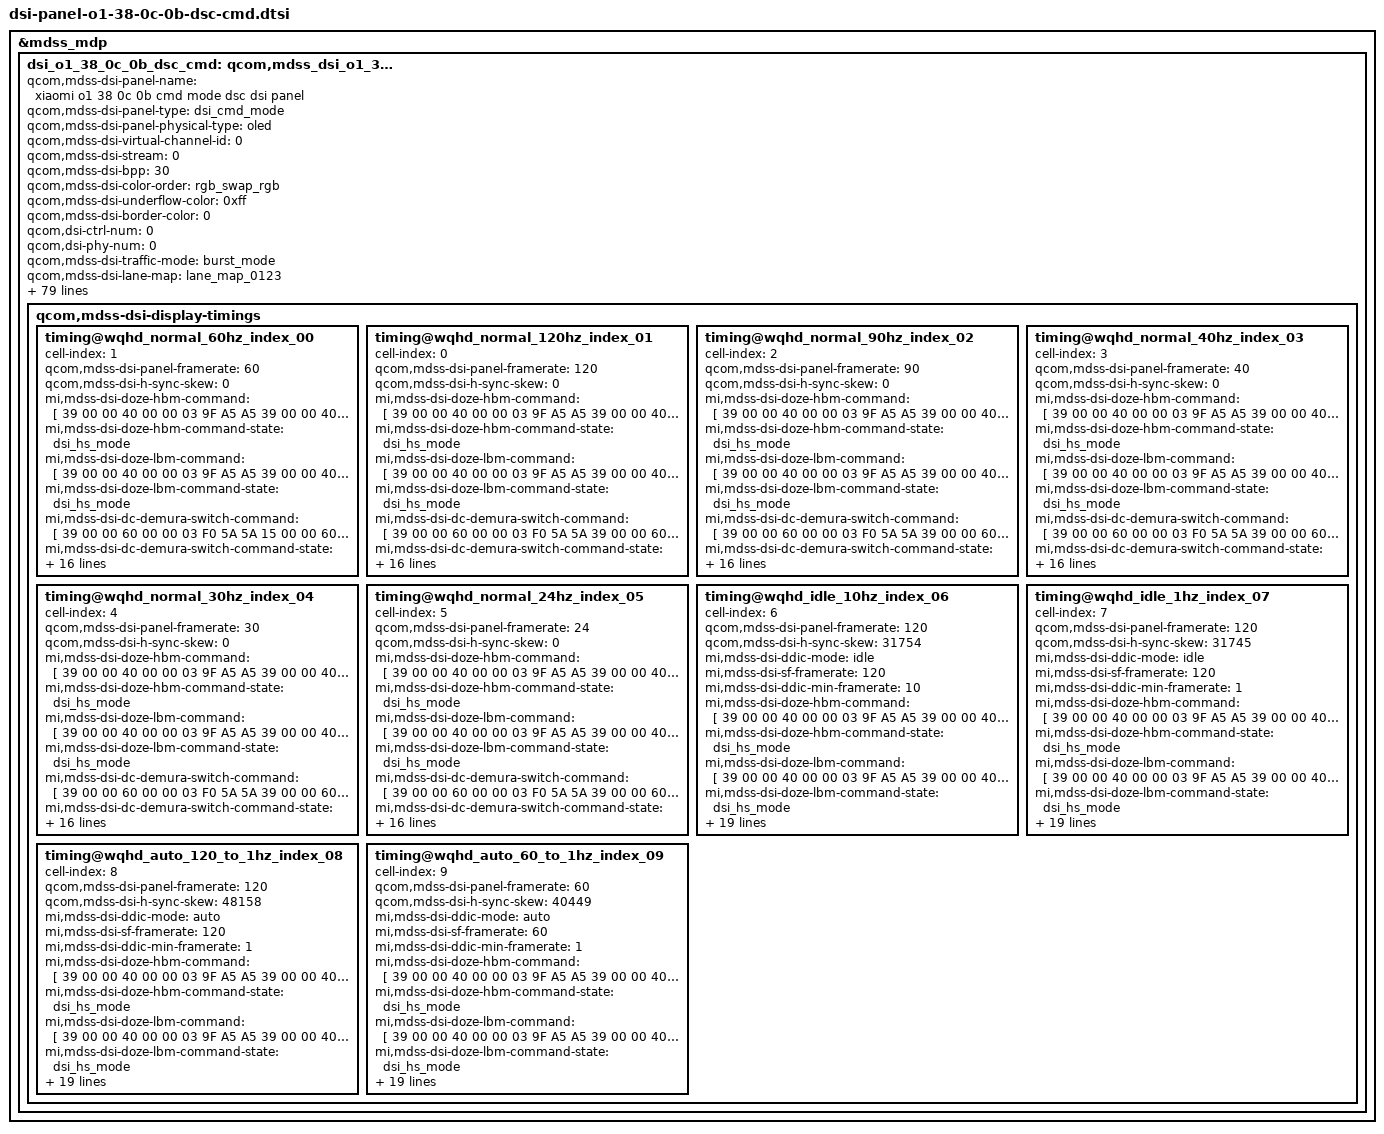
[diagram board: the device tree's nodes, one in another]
&mdss_mdp {
	dsi_o1_38_0c_0b_dsc_cmd: qcom,mdss_dsi_o1_38_0c_0b_dsc_cmd {
		qcom,mdss-dsi-panel-name = "xiaomi o1 38 0c 0b cmd mode dsc dsi panel";
		qcom,mdss-dsi-panel-type = "dsi_cmd_mode";
		qcom,mdss-dsi-panel-physical-type = "oled";
		qcom,mdss-dsi-virtual-channel-id = <0>;
		qcom,mdss-dsi-stream = <0>;
		qcom,mdss-dsi-bpp = <30>;
		qcom,mdss-dsi-color-order = "rgb_swap_rgb";
		qcom,mdss-dsi-underflow-color = <0xff>;
		qcom,mdss-dsi-border-color = <0>;
		qcom,dsi-ctrl-num = <0>;
		qcom,dsi-phy-num = <0>;
		qcom,mdss-dsi-traffic-mode = "burst_mode";
		qcom,mdss-dsi-lane-map = "lane_map_0123";
		qcom,mdss-dsi-bllp-eof-power-mode;
		qcom,mdss-dsi-bllp-power-mode;
		qcom,mdss-dsi-lane-0-state;
		qcom,mdss-dsi-lane-1-state;
		qcom,mdss-dsi-lane-2-state;
		qcom,mdss-dsi-lane-3-state;
		qcom,mdss-dsi-dma-trigger = "trigger_sw";
		qcom,mdss-dsi-mdp-trigger = "none";
		qcom,mdss-dsi-reset-sequence =<1 1>, <0 1>, <1 10>;
		qcom,mdss-pan-physical-width-dimension = <701>;
		qcom,mdss-pan-physical-height-dimension = <1558>;
		qcom,mdss-dsi-te-pin-select = <1>;
		qcom,mdss-dsi-wr-mem-start = <0x2c>;
		qcom,mdss-dsi-wr-mem-continue = <0x3c>;
		qcom,mdss-dsi-te-dcs-command = <1>;
		qcom,mdss-dsi-te-check-enable;
		qcom,mdss-dsi-te-using-te-pin;
		qcom,mdss-dsi-tx-eot-append;
		qcom,mdss-dsi-lp11-init;
		qcom,mdss-dsi-bl-inverted-dbv;
		qcom,mdss-dsi-panel-dimming-enabled;
		qcom,bl-update-flag = "delay_until_first_frame";
		qcom,mdss-dsi-panel-hdr-enabled;
		qcom,mdss-dsi-panel-hdr-color-primaries = <14500 15500 32000
			17000 15500 30000 8000 3000>;
		qcom,mdss-dsi-panel-peak-brightness = <32000000>;
		qcom,mdss-dsi-panel-blackness-level = <3230>;
		qcom,mdss-dsi-dma-schedule-line = <1>;
		qcom,mdss-dsi-dma-schedule-window = <50>;
		mi,panel-id = <0x00004F31 0x00380C0B>;
		mi,panel-on-dimming-delay = <120>;

		/* IRQF_ONESHOT | IRQF_TRIGGER_HEIGH */
		mi,esd-err-irq-gpio = <&tlmm 87 0x2004>;
		mi,esd-err-irq-gpio-flag = <0x2004>;

		qcom,qsync-enable;

		mi,mdss-dsi-panel-wp-read-command = [06 01 00 01 00 00 01 A1];
		mi,mdss-dsi-panel-wp-read-command-state = "dsi_hs_mode";
		mi,mdss-dsi-panel-wp-read-length = <8>;

		mi,mdss-dsi-fac-bl-max-level = <5460>;
		mi,mdss-fac-brightness-max-level = <5460>;
		mi,flatmode-status-check-enabled;
		mi,mdss-dsi-panel-flatmode-status-command = [
				06 01 00 01 00 00 01 5F
		];
		mi,mdss-dsi-panel-flatmode-status-command-state = "dsi_hs_mode";
		mi,mdss-dsi-panel-flatmode-status-read-length = <1>;
		mi,mdss-dsi-panel-flatmode-on-status-value = <0x00>;

		mi,doze-hbm-dbv-level = <412>;
		mi,doze-lbm-dbv-level = <35>;
		qcom,mdss-disable-cesta-hw-sleep;
		mi,sf-set-doze-brightness;

		qcom,mdss-dsi-display-timings {
			timing@wqhd_normal_60hz_index_00 {
				#include "dsi-panel-o1-38-0c-0b-dsc-cmd-common.dtsi"
				cell-index = <1>;
				qcom,mdss-dsi-panel-framerate = <60>;
				qcom,mdss-dsi-h-sync-skew = <0>;
				mi,mdss-dsi-doze-hbm-command = [
					//120HZ
					39 00 00 40 00 00 03 9F A5 A5
					39 00 00 40 00 00 03 F0 5A 5A
					39 00 00 40 00 00 04 B0 00 03 BD
					39 00 00 40 00 00 02 BD 66
					39 00 00 40 00 00 04 B0 00 08 BD
					39 00 00 40 00 00 02 BD 00
					39 00 00 40 00 00 02 B9 19
					39 00 00 40 00 00 04 B0 00 08 B9
					39 00 00 40 00 00 07 B9 02 00 02 02 00 02
					39 00 00 40 00 00 04 B0 00 06 B9
					39 00 00 40 00 00 02 B9 00
					39 00 00 40 00 00 04 B0 00 91 B9
					39 00 00 40 00 00 02 B9 00
					39 00 00 40 00 00 02 BD 01
					39 00 00 40 00 00 02 83 00
					39 00 00 40 00 00 02 F7 2F
					39 00 00 40 00 00 03 F0 A5 A5
					39 00 00 00 11 00 03 9F 5A 5A
					//1HZ AOD
					39 00 00 40 00 00 03 9F A5 A5
					39 00 00 40 00 00 03 F0 5A 5A
					39 00 00 40 00 00 04 B0 00 03 BD
					39 00 00 40 00 00 02 BD 64
					39 00 00 40 00 00 02 53 24
					39 00 00 40 00 00 02 83 1B
					39 00 00 40 00 00 03 51 01 9C
					39 00 00 40 00 00 02 B9 C1
					39 00 00 40 00 00 04 B0 00 08 B9
					39 00 00 40 00 00 07 B9 32 00 02 32 00 02
					39 00 00 40 00 00 04 B0 00 06 B9
					39 00 00 40 00 00 02 B9 03
					39 00 00 40 00 00 02 F7 2F
					39 00 00 40 00 00 03 F0 A5 A5
					39 00 00 00 00 00 03 9F 5A 5A
				];
				mi,mdss-dsi-doze-hbm-command-state = "dsi_hs_mode";

				mi,mdss-dsi-doze-lbm-command = [
					//120HZ
					39 00 00 40 00 00 03 9F A5 A5
					39 00 00 40 00 00 03 F0 5A 5A
					39 00 00 40 00 00 04 B0 00 03 BD
					39 00 00 40 00 00 02 BD 66
					39 00 00 40 00 00 04 B0 00 08 BD
					39 00 00 40 00 00 02 BD 00
					39 00 00 40 00 00 02 B9 19
					39 00 00 40 00 00 04 B0 00 08 B9
					39 00 00 40 00 00 07 B9 02 00 02 02 00 02
					39 00 00 40 00 00 04 B0 00 06 B9
					39 00 00 40 00 00 02 B9 00
					39 00 00 40 00 00 04 B0 00 91 B9
					39 00 00 40 00 00 02 B9 00
					39 00 00 40 00 00 02 BD 01
					39 00 00 40 00 00 02 83 00
					39 00 00 40 00 00 02 F7 2F
					39 00 00 40 00 00 03 F0 A5 A5
					39 00 00 00 11 00 03 9F 5A 5A
					//1HZ AOD
					39 00 00 40 00 00 03 9F A5 A5
					39 00 00 40 00 00 03 F0 5A 5A
					39 00 00 40 00 00 04 B0 00 03 BD
					39 00 00 40 00 00 02 BD 64
					39 00 00 40 00 00 02 53 24
					39 00 00 40 00 00 02 83 1B
					39 00 00 40 00 00 03 51 00 23
					39 00 00 40 00 00 02 B9 C1
					39 00 00 40 00 00 04 B0 00 08 B9
					39 00 00 40 00 00 07 B9 32 00 02 32 00 02
					39 00 00 40 00 00 04 B0 00 06 B9
					39 00 00 40 00 00 02 B9 03
					39 00 00 40 00 00 02 F7 2F
					39 00 00 40 00 00 03 F0 A5 A5
					39 00 00 00 00 00 03 9F 5A 5A
				];
				mi,mdss-dsi-doze-lbm-command-state = "dsi_hs_mode";

				mi,mdss-dsi-dc-demura-switch-command = [
					39 00 00 60 00 00 03 F0 5A 5A
					15 00 00 60 00 00 02 53 20
					39 00 00 60 00 00 04 B0 00 79 62
					15 00 00 60 00 00 02 62 01
					15 00 00 20 03 00 02 F7 2F
					39 00 00 60 00 00 04 B0 01 56 6B
					39 00 00 60 00 00 C2 6B 01 FF FF FF FF FF FF FF
								FF FF FF FF FF FF A8 FF A8 FF 96 FF
								84 FF 73 FF 50 FF 3E FF 1B FF 09 FE
								E6 FE E6 FE E6 FE E6 FE E6 FE E6 FE
								E6 FE E6 FE E6 FE E6 FE E6 FE E6 FE
								E6 FE E6 FE E6 FE E6 FE B1 FF FF FF
								FF FF FF FF FF FF FF FF FF FF A8 FF
								A8 FF 96 FF 84 FF 73 FF 50 FF 3E FF
								1B FF 09 FE E6 FE E6 FE E6 FE E6 FE
								E6 FE E6 FE E6 FE E6 FE E6 FE E6 FE
								E6 FE E6 FE E6 FE E6 FE E6 FE E6 FE
								B1 FF FF FF FF FF FF FF FF FF FF FF
								FF FF A8 FF A8 FF 96 FF 84 FF 73 FF
								50 FF 3E FF 1B FF 09 FE E6 FE E6 FE
								E6 FE E6 FE E6 FE E6 FE E6 FE E6 FE
								E6 FE E6 FE E6 FE E6 FE E6 FE E6 FE
								E6 FE E6 FE B1
					39 00 00 60 00 00 03 51 01 9C
					15 00 00 20 03 00 02 F7 2F
					39 00 00 60 00 00 04 B0 01 56 6B
					15 00 00 60 00 00 02 6B 00
					39 00 00 60 00 00 04 B0 00 79 62
					15 00 00 60 00 00 02 62 00
					15 00 00 60 00 00 02 F7 2F
					39 00 00 20 00 00 03 F0 A5 A5
				];
				mi,mdss-dsi-dc-demura-switch-command-state = "dsi_hs_mode";

				mi,mdss-dsi-pwm-demura-switch-command = [
					39 00 00 60 00 00 03 F0 5A 5A
					15 00 00 60 00 00 02 53 20
					39 00 00 60 00 00 04 B0 00 79 62
					15 00 00 60 00 00 02 62 01
					15 00 00 20 03 00 02 F7 2F
					39 00 00 60 00 00 04 B0 01 56 6B
					39 00 00 60 00 00 C2 6B 01 00 00 00 00 00 00 00
								00 00 00 00 00 00 00 00 00 00 00 00
								00 00 00 00 00 00 00 00 00 00 00 00
								00 00 00 00 00 00 8C 00 8C 00 8C 00
								8C 00 8C 00 8C 00 8C 00 8C 00 8C 00
								8C 00 8C 00 8C 00 8C 00 B0 00 00 00
								00 00 00 00 00 00 00 00 00 00 00 00
								00 00 00 00 00 00 00 00 00 00 00 00
								00 00 00 00 00 00 00 00 00 00 8C 00
								8C 00 8C 00 8C 00 8C 00 8C 00 8C 00
								8C 00 8C 00 8C 00 8C 00 8C 00 8C 00
								B0 00 00 00 00 00 00 00 00 00 00 00
								00 00 00 00 00 00 00 00 00 00 00 00
								00 00 00 00 00 00 00 00 00 00 00 00
								00 00 8C 00 8C 00 8C 00 8C 00 8C 00
								8C 00 8C 00 8C 00 8C 00 8C 00 8C 00
								8C 00 8C 00 B0
					39 00 00 60 00 00 03 51 01 9B
					15 00 00 20 03 00 02 F7 2F
					39 00 00 60 00 00 04 B0 01 56 6B
					15 00 00 60 00 00 02 6B 00
					39 00 00 60 00 00 04 B0 00 79 62
					15 00 00 60 00 00 02 62 00
					15 00 00 60 00 00 02 F7 2F
					39 00 00 20 00 00 03 F0 A5 A5
				];
				mi,mdss-dsi-pwm-demura-switch-command-state = "dsi_hs_mode";

				qcom,mdss-dsi-nolp-command = [
					39 00 00 40 00 00 03 9F A5 A5
					39 00 00 40 00 00 03 F0 5A 5A
					39 00 00 40 00 00 04 B0 00 03 BD
					39 00 00 40 00 00 02 BD 66
					39 00 00 40 00 00 02 B9 19
					39 00 00 40 00 00 04 B0 00 08 B9
					39 00 00 40 00 00 07 B9 02 00 02 02 00 02
					39 00 00 40 00 00 04 B0 00 06 B9
					39 00 00 40 00 00 02 B9 00
					39 00 00 40 00 00 02 53 20
					39 00 00 40 00 00 02 83 00
					39 00 00 40 00 00 03 51 00 23
					39 00 00 40 00 00 02 F7 2F
					39 00 00 40 00 00 03 F0 A5 A5
					39 00 00 00 00 00 03 9F 5A 5A
					//60HZ
					39 00 00 40 00 00 03 9F A5 A5
					39 00 00 40 00 00 03 F0 5A 5A
					39 00 00 40 00 00 04 B0 00 03 BD
					39 00 00 40 00 00 02 BD 66
					39 00 00 40 00 00 04 B0 00 08 BD
					39 00 00 40 00 00 02 BD 01
					39 00 00 40 00 00 02 B9 19
					39 00 00 40 00 00 04 B0 00 08 B9
					39 00 00 40 00 00 07 B9 02 00 02 02 00 02
					39 00 00 40 00 00 04 B0 00 06 B9
					39 00 00 40 00 00 02 B9 01
					39 00 00 40 00 00 04 B0 00 91 B9
					39 00 00 40 00 00 02 B9 00
					39 00 00 40 00 00 02 BD 01
					39 00 00 40 00 00 02 83 01
					39 00 00 40 00 00 02 F7 2F
					39 00 00 40 00 00 03 F0 A5 A5
					39 00 00 00 00 00 03 9F 5A 5A
				];
				qcom,mdss-dsi-nolp-command-update = <0x51 11 2>;
				qcom,mdss-dsi-nolp-command-state = "dsi_hs_mode";
				qcom,mdss-dsi-timing-switch-command = [
					39 00 00 40 00 00 03 9F A5 A5
					39 00 00 40 00 00 03 F0 5A 5A
					39 00 00 40 00 00 04 B0 00 03 BD
					39 00 00 40 00 00 02 BD 66
					39 00 00 40 00 00 04 B0 00 08 BD
					39 00 00 40 00 00 02 BD 00
					39 00 00 40 00 00 02 B9 19
					39 00 00 40 00 00 04 B0 00 08 B9
					39 00 00 40 00 00 07 B9 02 00 02 02 00 02
					39 00 00 40 00 00 04 B0 00 06 B9
					39 00 00 40 00 00 02 B9 00
					39 00 00 40 00 00 04 B0 00 91 B9
					39 00 00 40 00 00 02 B9 00
					39 00 00 40 00 00 02 BD 01
					39 00 00 40 00 00 02 83 01
					39 00 00 40 00 00 02 F7 2F
					39 00 00 40 00 00 03 F0 A5 A5
					39 00 00 00 00 00 03 9F 5A 5A
				];
				qcom,mdss-dsi-timing-switch-command-state = "dsi_hs_mode";
				qcom,mdss-dsi-on-command = [
					//DSC setting V1.1
					39 00 00 40 00 00 03 9F A5 A5
					39 00 00 40 00 00 59 9E 11 00 00 AB 30 80 0C 80 05 A0 00 19 02 D0 02 D0
											02 00 02 68 00 20 02 BE 00 0A 00 0C 04 00 03 0D 18 00 10 F0 07 10 20 00
 											06 0F 0F 33 0E 1C 2A 38 46 54 62 69 70 77 79 7B 7D 7E 01 02 22 00 2A 40
											2A BE 3A FC 3A FA 3A F8 3B 38 3B 78 3B B6 4B F6 4C 34 4C 74 5C 74 8C F4
					39 00 00 40 00 00 02 9D 01
					39 00 00 00 00 00 03 9F 5A 5A
					//AD Improve Setting
					39 00 00 40 00 00 03 F0 5A 5A
					39 00 00 40 00 00 03 F1 5A 5A
					15 00 00 40 00 00 02 D0 08
					39 00 00 40 00 00 04 B0 00 60 B7
					15 00 00 40 00 00 02 B7 45
					39 00 00 40 00 00 04 B0 00 6A B7
					15 00 00 40 00 00 02 B7 15
					39 00 00 40 00 00 04 B0 00 6D B7
					15 00 00 40 00 00 02 B7 45
					39 00 00 40 00 00 04 B0 00 77 B7
					15 00 00 40 00 00 02 B7 15
					39 00 00 00 00 00 0E F4 F3 E0 E1 D3 B3 D3 A3 D3 D3 B3 D3 A3 D3
					/* Sleep Out */
					05 00 00 00 78 00 01 11
					//TE ON
					39 00 00 40 00 00 03 9F A5 A5
					39 00 00 40 00 00 02 35 00
					39 00 00 00 00 00 03 9F 5A 5A
					//FIXED TE OFF
					39 00 00 40 00 00 03 F0 5A 5A
					39 00 00 40 00 00 02 B9 00
					39 00 00 40 00 00 04 B0 00 08 B9
					39 00 00 40 00 00 07 B9 00 00 00 00 00 00
					39 00 00 40 00 00 02 F7 0F
					39 00 00 00 00 00 03 F0 A5 A5
					//PAGE ADDRESS SET
					39 00 00 40 00 00 05 2A 00 00 05 9F
					39 00 00 40 00 00 05 2B 00 00 0C 7F
					//Scaler Setting
					39 00 00 40 00 00 03 F0 5A 5A
					39 00 00 40 00 00 02 C3 02
					39 00 00 40 00 00 05 2A 00 00 05 9F
					39 00 00 40 00 00 05 2B 00 00 0C 7F
					39 00 00 40 00 00 03 F0 A5 A5
					//Frequency Change Setting
					39 00 00 40 00 00 03 9F A5 A5
					39 00 00 40 00 00 03 F0 5A 5A
					39 00 00 40 00 00 02 83 00
					39 00 00 40 00 00 02 F7 2F
					39 00 00 40 00 00 03 F0 A5 A5
					39 00 00 00 00 00 03 9F 5A 5A
					//Error Flag Control
					39 00 00 40 00 00 03 F0 5A 5A
					39 00 00 40 00 00 02 E5 15
					39 00 00 40 00 00 04 B0 00 18 ED
					39 00 00 40 00 00 02 ED 1C
					39 00 00 40 00 00 04 B0 00 43 F4
					39 00 00 40 00 00 02 F4 30
					39 00 00 40 00 00 04 B0 00 01 ED
					39 00 00 40 00 00 03 ED 01 40
					39 00 00 00 00 00 03 F0 A5 A5
					//ACL Mode
					39 00 00 40 00 00 03 F0 5A 5A
					39 00 00 40 00 00 02 55 00
					39 00 00 00 00 00 03 F0 A5 A5
					//OD OFF
					39 00 00 40 00 00 03 F0 5A 5A
					39 00 00 40 00 00 04 B0 00 8B 68
					15 00 00 40 00 00 02 68 01
					15 00 00 40 00 00 02 F7 2F
					39 00 00 00 00 00 03 F0 A5 A5
					//Low Frequency Change(Manual Mode)
					39 00 00 40 00 00 03 9F A5 A5
					39 00 00 40 00 00 03 F0 5A 5A
					39 00 00 40 00 00 04 B0 00 03 BD
					39 00 00 40 00 00 02 BD 66
					39 00 00 40 00 00 04 B0 00 08 BD
					39 00 00 40 00 00 02 BD 00
					39 00 00 40 00 00 02 B9 19
					39 00 00 40 00 00 04 B0 00 08 B9
					39 00 00 40 00 00 07 B9 02 00 02 02 00 02
					39 00 00 40 00 00 04 B0 00 06 B9
					39 00 00 40 00 00 02 B9 00
					39 00 00 40 00 00 04 B0 00 91 B9
					39 00 00 40 00 00 02 B9 00
					39 00 00 40 00 00 02 BD 01
					39 00 00 40 00 00 02 83 01
					39 00 00 40 00 00 02 F7 2F
					39 00 00 40 00 00 03 F0 A5 A5
					39 00 00 00 00 00 03 9F 5A 5A
					//Dimming speed
					39 00 00 40 00 00 03 F0 5A 5A
					39 00 00 40 00 00 04 B0 00 20 67
					39 00 00 40 00 00 02 67 06
					39 00 00 40 00 00 02 F7 2F
					39 00 00 00 00 00 03 F0 A5 A5
					/* AOD ON */
					39 00 00 40 00 00 03 9F A5 A5
					39 00 00 40 00 00 03 F0 5A 5A
					15 00 00 40 00 00 02 53 24
					15 00 00 40 00 00 02 83 18
					39 00 00 40 00 00 02 F7 2F
					39 00 00 40 00 00 03 F0 A5 A5
					39 00 00 00 0B 00 03 9F 5A 5A
					/* AOD OFF */
					39 00 00 40 00 00 03 9F A5 A5
					39 00 00 40 00 00 03 F0 5A 5A
					15 00 00 40 00 00 02 53 20
					15 00 00 40 00 00 02 83 00
					39 00 00 40 00 00 02 F7 2F
					39 00 00 40 00 00 03 F0 A5 A5
					39 00 00 00 00 00 03 9F 5A 5A
					//Low Frequency Change(Manual Mode)
					39 00 00 40 00 00 03 9F A5 A5
					39 00 00 40 00 00 03 F0 5A 5A
					39 00 00 40 00 00 04 B0 00 03 BD
					39 00 00 40 00 00 02 BD 66
					39 00 00 40 00 00 04 B0 00 08 BD
					39 00 00 40 00 00 02 BD 00
					39 00 00 40 00 00 02 B9 19
					39 00 00 40 00 00 04 B0 00 08 B9
					39 00 00 40 00 00 07 B9 02 00 02 02 00 02
					39 00 00 40 00 00 04 B0 00 06 B9
					39 00 00 40 00 00 02 B9 00
					39 00 00 40 00 00 04 B0 00 91 B9
					39 00 00 40 00 00 02 B9 00
					39 00 00 40 00 00 02 BD 01
					39 00 00 40 00 00 02 83 01
					39 00 00 40 00 00 02 F7 2F
					39 00 00 40 00 00 03 F0 A5 A5
					39 00 00 00 00 00 03 9F 5A 5A
					//Brightness Control
					39 00 00 40 00 00 02 53 20
					39 00 00 00 00 00 03 51 00 00
					//PWM&DC switch
					39 00 00 40 00 00 03 F0 5A 5A
					39 00 00 40 00 00 04 B0 02 17 6B
					39 00 00 40 00 00 61 6B 00 10 18 20 28 30 38 40 48 50 58 60
							  	68 70 78 80 88 90 98 A0 A8 B0 B8 C0 C8 D0 D8 E0 E8 F0 F8 FF 00
							  	10 18 20 28 30 38 40 48 50 58 60 68 70 78 80 88 90 98 A0 A8 B0
							  	B8 C0 C8 D0 D8 E0 E8 F0 F8 FF 00 10 18 20 28 30 38 40 48 50 58
							  	60 68 70 78 80 88 90 98 A0 A8 B0 B8 C0 C8 D0 D8 E0 E8 F0 F8 FF
					39 00 00 40 00 00 04 B0 00 1E 67
					15 00 00 40 00 00 02 67 11
					15 00 00 40 00 00 02 F7 2F
					39 00 00 00 00 00 03 F0 A5 A5
					/* Display On */
					39 00 00 40 00 00 03 9F A5 A5
					05 00 00 40 00 00 01 29
					39 00 00 00 00 00 03 9F 5A 5A
				];
				qcom,mdss-dsi-on-command-state = "dsi_lp_mode";
			};
			timing@wqhd_normal_120hz_index_01 {
				#include "dsi-panel-o1-38-0c-0b-dsc-cmd-common.dtsi"
				cell-index = <0>;
				qcom,mdss-dsi-panel-framerate = <120>;
				qcom,mdss-dsi-h-sync-skew = <0>;
				mi,mdss-dsi-doze-hbm-command = [
					//1HZ AOD
					39 00 00 40 00 00 03 9F A5 A5
					39 00 00 40 00 00 03 F0 5A 5A
					39 00 00 40 00 00 04 B0 00 03 BD
					39 00 00 40 00 00 02 BD 64
					39 00 00 40 00 00 02 53 24
					39 00 00 40 00 00 02 83 1B
					39 00 00 40 00 00 03 51 01 9C
					39 00 00 40 00 00 02 B9 C1
					39 00 00 40 00 00 04 B0 00 08 B9
					39 00 00 40 00 00 07 B9 32 00 02 32 00 02
					39 00 00 40 00 00 04 B0 00 06 B9
					39 00 00 40 00 00 02 B9 03
					39 00 00 40 00 00 02 F7 2F
					39 00 00 40 00 00 03 F0 A5 A5
					39 00 00 00 00 00 03 9F 5A 5A
				];
				mi,mdss-dsi-doze-hbm-command-state = "dsi_hs_mode";

				mi,mdss-dsi-doze-lbm-command = [
					//1HZ AOD
					39 00 00 40 00 00 03 9F A5 A5
					39 00 00 40 00 00 03 F0 5A 5A
					39 00 00 40 00 00 04 B0 00 03 BD
					39 00 00 40 00 00 02 BD 64
					39 00 00 40 00 00 02 53 24
					39 00 00 40 00 00 02 83 1B
					39 00 00 40 00 00 03 51 00 23
					39 00 00 40 00 00 02 B9 C1
					39 00 00 40 00 00 04 B0 00 08 B9
					39 00 00 40 00 00 07 B9 32 00 02 32 00 02
					39 00 00 40 00 00 04 B0 00 06 B9
					39 00 00 40 00 00 02 B9 03
					39 00 00 40 00 00 02 F7 2F
					39 00 00 40 00 00 03 F0 A5 A5
					39 00 00 00 00 00 03 9F 5A 5A
				];
				mi,mdss-dsi-doze-lbm-command-state = "dsi_hs_mode";

				mi,mdss-dsi-dc-demura-switch-command = [
					39 00 00 60 00 00 03 F0 5A 5A
					39 00 00 60 00 00 04 B0 00 79 62
					15 00 00 60 00 00 02 62 01
					15 00 00 20 00 00 02 F7 2F
					39 00 00 60 00 00 04 B0 01 56 6B
					39 00 00 60 00 00 C2 6B 01 FF FF FF FF FF FF FF
								FF FF FF FF FF FF BF FF BF FF B3 FF
								A6 FF 99 FF 7F FF 73 FF 59 FF 4C FF
								33 FF 33 FF 33 FF 33 FF 33 FF 33 FF
								33 FF 33 FF 33 FF 33 FF 33 FF 33 FF
								33 FF 33 FF 33 FF 33 FF 0C FF FF FF
								FF FF FF FF FF FF FF FF FF FF BF FF
								BF FF B3 FF A6 FF 99 FF 7F FF 73 FF
								59 FF 4C FF 33 FF 33 FF 33 FF 33 FF
								33 FF 33 FF 33 FF 33 FF 33 FF 33 FF
								33 FF 33 FF 33 FF 33 FF 33 FF 33 FF
								0C FF FF FF FF FF FF FF FF FF FF FF
								FF FF BF FF BF FF B3 FF A6 FF 99 FF
								7F FF 73 FF 59 FF 4C FF 33 FF 33 FF
								33 FF 33 FF 33 FF 33 FF 33 FF 33 FF
								33 FF 33 FF 33 FF 33 FF 33 FF 33 FF
								33 FF 33 FF 0C
					39 00 00 60 00 00 03 51 01 9C
					15 00 00 20 00 00 02 F7 2F
					39 00 00 60 00 00 04 B0 01 56 6B
					15 00 00 60 00 00 02 6B 00
					39 00 00 60 00 00 04 B0 00 79 62
					15 00 00 60 00 00 02 62 00
					15 00 00 60 00 00 02 F7 2F
					39 00 00 20 00 00 03 F0 A5 A5
				];
				mi,mdss-dsi-dc-demura-switch-command-state = "dsi_hs_mode";

				mi,mdss-dsi-pwm-demura-switch-command = [
					39 00 00 60 00 00 03 F0 5A 5A
					39 00 00 60 00 00 04 B0 00 79 62
					15 00 00 60 00 00 02 62 01
					15 00 00 20 00 00 02 F7 2F
					39 00 00 60 00 00 04 B0 01 56 6B
					39 00 00 60 00 00 C2 6B 01 00 00 00 00 00 00 00
								00 00 00 00 00 00 00 00 00 00 00 00
								00 00 00 00 00 00 00 00 00 00 00 00
								00 00 00 00 00 00 66 00 66 00 66 00
								66 00 66 00 66 00 66 00 66 00 66 00
								66 00 66 00 66 00 66 00 80 00 00 00
								00 00 00 00 00 00 00 00 00 00 00 00
								00 00 00 00 00 00 00 00 00 00 00 00
								00 00 00 00 00 00 00 00 00 00 66 00
								66 00 66 00 66 00 66 00 66 00 66 00
								66 00 66 00 66 00 66 00 66 00 66 00
								80 00 00 00 00 00 00 00 00 00 00 00
								00 00 00 00 00 00 00 00 00 00 00 00
								00 00 00 00 00 00 00 00 00 00 00 00
								00 00 66 00 66 00 66 00 66 00 66 00
								66 00 66 00 66 00 66 00 66 00 66 00
								66 00 66 00 80
					39 00 00 60 00 00 03 51 01 9B
					15 00 00 20 00 00 02 F7 2F
					39 00 00 60 00 00 04 B0 01 56 6B
					15 00 00 60 00 00 02 6B 00
					39 00 00 60 00 00 04 B0 00 79 62
					15 00 00 60 00 00 02 62 00
					15 00 00 60 00 00 02 F7 2F
					39 00 00 20 00 00 03 F0 A5 A5
				];
				mi,mdss-dsi-pwm-demura-switch-command-state = "dsi_hs_mode";

				qcom,mdss-dsi-nolp-command = [
					39 00 00 40 00 00 03 9F A5 A5
					39 00 00 40 00 00 03 F0 5A 5A
					39 00 00 40 00 00 04 B0 00 03 BD
					39 00 00 40 00 00 02 BD 66
					39 00 00 40 00 00 02 B9 19
					39 00 00 40 00 00 04 B0 00 08 B9
					39 00 00 40 00 00 07 B9 02 00 02 02 00 02
					39 00 00 40 00 00 04 B0 00 06 B9
					39 00 00 40 00 00 02 B9 00
					39 00 00 40 00 00 02 53 20
					39 00 00 40 00 00 02 83 00
					39 00 00 40 00 00 03 51 00 23
					39 00 00 40 00 00 02 F7 2F
					39 00 00 40 00 00 03 F0 A5 A5
					39 00 00 00 00 00 03 9F 5A 5A
				];
				qcom,mdss-dsi-nolp-command-update = <0x51 11 2>;
				qcom,mdss-dsi-nolp-command-state = "dsi_hs_mode";
				qcom,mdss-dsi-timing-switch-command = [
					39 00 00 40 00 00 03 9F A5 A5
					39 00 00 40 00 00 03 F0 5A 5A
					39 00 00 40 00 00 04 B0 00 03 BD
					39 00 00 40 00 00 02 BD 66
					39 00 00 40 00 00 04 B0 00 08 BD
					39 00 00 40 00 00 02 BD 00
					39 00 00 40 00 00 02 B9 19
					39 00 00 40 00 00 04 B0 00 08 B9
					39 00 00 40 00 00 07 B9 02 00 02 02 00 02
					39 00 00 40 00 00 04 B0 00 06 B9
					39 00 00 40 00 00 02 B9 00
					39 00 00 40 00 00 04 B0 00 91 B9
					39 00 00 40 00 00 02 B9 00
					39 00 00 40 00 00 02 BD 01
					39 00 00 40 00 00 02 83 00
					39 00 00 40 00 00 02 F7 2F
					39 00 00 40 00 00 03 F0 A5 A5
					39 00 00 00 00 00 03 9F 5A 5A
				];
				qcom,mdss-dsi-timing-switch-command-state = "dsi_hs_mode";
				qcom,mdss-dsi-on-command = [
					//DSC setting V1.1
					39 00 00 40 00 00 03 9F A5 A5
					39 00 00 40 00 00 59 9E 11 00 00 AB 30 80 0C 80 05 A0 00 19 02 D0 02 D0
											02 00 02 68 00 20 02 BE 00 0A 00 0C 04 00 03 0D 18 00 10 F0 07 10 20 00
 											06 0F 0F 33 0E 1C 2A 38 46 54 62 69 70 77 79 7B 7D 7E 01 02 22 00 2A 40
											2A BE 3A FC 3A FA 3A F8 3B 38 3B 78 3B B6 4B F6 4C 34 4C 74 5C 74 8C F4
					39 00 00 40 00 00 02 9D 01
					39 00 00 00 00 00 03 9F 5A 5A
					//AD Improve Setting
					39 00 00 40 00 00 03 F0 5A 5A
					39 00 00 40 00 00 03 F1 5A 5A
					15 00 00 40 00 00 02 D0 08
					39 00 00 40 00 00 04 B0 00 60 B7
					15 00 00 40 00 00 02 B7 45
					39 00 00 40 00 00 04 B0 00 6A B7
					15 00 00 40 00 00 02 B7 15
					39 00 00 40 00 00 04 B0 00 6D B7
					15 00 00 40 00 00 02 B7 45
					39 00 00 40 00 00 04 B0 00 77 B7
					15 00 00 40 00 00 02 B7 15
					39 00 00 00 00 00 0E F4 F3 E0 E1 D3 B3 D3 A3 D3 D3 B3 D3 A3 D3
					/* Sleep Out */
					05 00 00 00 78 00 01 11
					//TE ON
					39 00 00 40 00 00 03 9F A5 A5
					39 00 00 40 00 00 02 35 00
					39 00 00 00 00 00 03 9F 5A 5A
					//FIXED TE OFF
					39 00 00 40 00 00 03 F0 5A 5A
					39 00 00 40 00 00 02 B9 00
					39 00 00 40 00 00 04 B0 00 08 B9
					39 00 00 40 00 00 07 B9 00 00 00 00 00 00
					39 00 00 40 00 00 02 F7 0F
					39 00 00 00 00 00 03 F0 A5 A5
					//PAGE ADDRESS SET
					39 00 00 40 00 00 05 2A 00 00 05 9F
					39 00 00 40 00 00 05 2B 00 00 0C 7F
					//Scaler Setting
					39 00 00 40 00 00 03 F0 5A 5A
					39 00 00 40 00 00 02 C3 02
					39 00 00 40 00 00 05 2A 00 00 05 9F
					39 00 00 40 00 00 05 2B 00 00 0C 7F
					39 00 00 40 00 00 03 F0 A5 A5
					//Frequency Change Setting
					39 00 00 40 00 00 03 9F A5 A5
					39 00 00 40 00 00 03 F0 5A 5A
					39 00 00 40 00 00 02 83 00
					39 00 00 40 00 00 02 F7 2F
					39 00 00 40 00 00 03 F0 A5 A5
					39 00 00 00 00 00 03 9F 5A 5A
					//Error Flag Control
					39 00 00 40 00 00 03 F0 5A 5A
					39 00 00 40 00 00 02 E5 15
					39 00 00 40 00 00 04 B0 00 18 ED
					39 00 00 40 00 00 02 ED 1C
					39 00 00 40 00 00 04 B0 00 43 F4
					39 00 00 40 00 00 02 F4 30
					39 00 00 40 00 00 04 B0 00 01 ED
					39 00 00 40 00 00 03 ED 01 40
					39 00 00 00 00 00 03 F0 A5 A5
					//ACL Mode
					39 00 00 40 00 00 03 F0 5A 5A
					39 00 00 40 00 00 02 55 00
					39 00 00 00 00 00 03 F0 A5 A5
					//OD OFF
					39 00 00 40 00 00 03 F0 5A 5A
					39 00 00 40 00 00 04 B0 00 8B 68
					15 00 00 40 00 00 02 68 01
					15 00 00 40 00 00 02 F7 2F
					39 00 00 00 00 00 03 F0 A5 A5
					//Low Frequency Change(Manual Mode)
					39 00 00 40 00 00 03 9F A5 A5
					39 00 00 40 00 00 03 F0 5A 5A
					39 00 00 40 00 00 04 B0 00 03 BD
					39 00 00 40 00 00 02 BD 66
					39 00 00 40 00 00 04 B0 00 08 BD
					39 00 00 40 00 00 02 BD 00
					39 00 00 40 00 00 02 B9 19
					39 00 00 40 00 00 04 B0 00 08 B9
					39 00 00 40 00 00 07 B9 02 00 02 02 00 02
					39 00 00 40 00 00 04 B0 00 06 B9
					39 00 00 40 00 00 02 B9 00
					39 00 00 40 00 00 04 B0 00 91 B9
					39 00 00 40 00 00 02 B9 00
					39 00 00 40 00 00 02 BD 01
					39 00 00 40 00 00 02 83 00
					39 00 00 40 00 00 02 F7 2F
					39 00 00 40 00 00 03 F0 A5 A5
					39 00 00 00 00 00 03 9F 5A 5A
					//Dimming speed
					39 00 00 40 00 00 03 F0 5A 5A
					39 00 00 40 00 00 04 B0 00 20 67
					39 00 00 40 00 00 02 67 06
					39 00 00 40 00 00 02 F7 2F
					39 00 00 00 00 00 03 F0 A5 A5
					/* AOD ON */
					39 00 00 40 00 00 03 9F A5 A5
					39 00 00 40 00 00 03 F0 5A 5A
					15 00 00 40 00 00 02 53 24
					15 00 00 40 00 00 02 83 18
					39 00 00 40 00 00 02 F7 2F
					39 00 00 40 00 00 03 F0 A5 A5
					39 00 00 00 0B 00 03 9F 5A 5A
					/* AOD OFF */
					39 00 00 40 00 00 03 9F A5 A5
					39 00 00 40 00 00 03 F0 5A 5A
					15 00 00 40 00 00 02 53 20
					15 00 00 40 00 00 02 83 00
					39 00 00 40 00 00 02 F7 2F
					39 00 00 40 00 00 03 F0 A5 A5
					39 00 00 00 00 00 03 9F 5A 5A
					//Low Frequency Change(Manual Mode)
					39 00 00 40 00 00 03 9F A5 A5
					39 00 00 40 00 00 03 F0 5A 5A
					39 00 00 40 00 00 04 B0 00 03 BD
					39 00 00 40 00 00 02 BD 66
					39 00 00 40 00 00 04 B0 00 08 BD
					39 00 00 40 00 00 02 BD 00
					39 00 00 40 00 00 02 B9 19
					39 00 00 40 00 00 04 B0 00 08 B9
					39 00 00 40 00 00 07 B9 02 00 02 02 00 02
					39 00 00 40 00 00 04 B0 00 06 B9
					39 00 00 40 00 00 02 B9 00
					39 00 00 40 00 00 04 B0 00 91 B9
					39 00 00 40 00 00 02 B9 00
					39 00 00 40 00 00 02 BD 01
					39 00 00 40 00 00 02 83 00
					39 00 00 40 00 00 02 F7 2F
					39 00 00 40 00 00 03 F0 A5 A5
					39 00 00 00 00 00 03 9F 5A 5A
					//Brightness Control
					39 00 00 40 00 00 02 53 20
					39 00 00 00 00 00 03 51 00 00
					//PWM&DC switch
					39 00 00 40 00 00 03 F0 5A 5A
					39 00 00 40 00 00 04 B0 02 17 6B
					39 00 00 40 00 00 61 6B 00 10 18 20 28 30 38 40 48 50 58 60
							  	68 70 78 80 88 90 98 A0 A8 B0 B8 C0 C8 D0 D8 E0 E8 F0 F8 FF 00
							  	10 18 20 28 30 38 40 48 50 58 60 68 70 78 80 88 90 98 A0 A8 B0
							  	B8 C0 C8 D0 D8 E0 E8 F0 F8 FF 00 10 18 20 28 30 38 40 48 50 58
							  	60 68 70 78 80 88 90 98 A0 A8 B0 B8 C0 C8 D0 D8 E0 E8 F0 F8 FF
					39 00 00 40 00 00 04 B0 00 1E 67
					15 00 00 40 00 00 02 67 11
					15 00 00 40 00 00 02 F7 2F
					39 00 00 00 00 00 03 F0 A5 A5
					/* Display On */
					39 00 00 40 00 00 03 9F A5 A5
					05 00 00 40 00 00 01 29
					39 00 00 00 00 00 03 9F 5A 5A
				];
				qcom,mdss-dsi-on-command-state = "dsi_lp_mode";
			};
			timing@wqhd_normal_90hz_index_02 {
				#include "dsi-panel-o1-38-0c-0b-dsc-cmd-common.dtsi"
				cell-index = <2>;
				qcom,mdss-dsi-panel-framerate = <90>;
				qcom,mdss-dsi-h-sync-skew = <0>;
				mi,mdss-dsi-doze-hbm-command = [
					//120HZ
					39 00 00 40 00 00 03 9F A5 A5
					39 00 00 40 00 00 03 F0 5A 5A
					39 00 00 40 00 00 04 B0 00 03 BD
					39 00 00 40 00 00 02 BD 66
					39 00 00 40 00 00 04 B0 00 08 BD
					39 00 00 40 00 00 02 BD 00
					39 00 00 40 00 00 02 B9 19
					39 00 00 40 00 00 04 B0 00 08 B9
					39 00 00 40 00 00 07 B9 02 00 02 02 00 02
					39 00 00 40 00 00 04 B0 00 06 B9
					39 00 00 40 00 00 02 B9 00
					39 00 00 40 00 00 04 B0 00 91 B9
					39 00 00 40 00 00 02 B9 00
					39 00 00 40 00 00 02 BD 01
					39 00 00 40 00 00 02 83 00
					39 00 00 40 00 00 02 F7 2F
					39 00 00 40 00 00 03 F0 A5 A5
					39 00 00 00 0B 00 03 9F 5A 5A
					//1HZ AOD
					39 00 00 40 00 00 03 9F A5 A5
					39 00 00 40 00 00 03 F0 5A 5A
					39 00 00 40 00 00 04 B0 00 03 BD
					39 00 00 40 00 00 02 BD 64
					39 00 00 40 00 00 02 53 24
					39 00 00 40 00 00 02 83 1B
					39 00 00 40 00 00 03 51 01 9C
					39 00 00 40 00 00 02 B9 C1
					39 00 00 40 00 00 04 B0 00 08 B9
					39 00 00 40 00 00 07 B9 32 00 02 32 00 02
					39 00 00 40 00 00 04 B0 00 06 B9
					39 00 00 40 00 00 02 B9 03
					39 00 00 40 00 00 02 F7 2F
					39 00 00 40 00 00 03 F0 A5 A5
					39 00 00 00 00 00 03 9F 5A 5A
				];
				mi,mdss-dsi-doze-hbm-command-state = "dsi_hs_mode";

				mi,mdss-dsi-doze-lbm-command = [
					//120HZ
					39 00 00 40 00 00 03 9F A5 A5
					39 00 00 40 00 00 03 F0 5A 5A
					39 00 00 40 00 00 04 B0 00 03 BD
					39 00 00 40 00 00 02 BD 66
					39 00 00 40 00 00 04 B0 00 08 BD
					39 00 00 40 00 00 02 BD 00
					39 00 00 40 00 00 02 B9 19
					39 00 00 40 00 00 04 B0 00 08 B9
					39 00 00 40 00 00 07 B9 02 00 02 02 00 02
					39 00 00 40 00 00 04 B0 00 06 B9
					39 00 00 40 00 00 02 B9 00
					39 00 00 40 00 00 04 B0 00 91 B9
					39 00 00 40 00 00 02 B9 00
					39 00 00 40 00 00 02 BD 01
					39 00 00 40 00 00 02 83 00
					39 00 00 40 00 00 02 F7 2F
					39 00 00 40 00 00 03 F0 A5 A5
					39 00 00 00 0B 00 03 9F 5A 5A
					//1HZ AOD
					39 00 00 40 00 00 03 9F A5 A5
					39 00 00 40 00 00 03 F0 5A 5A
					39 00 00 40 00 00 04 B0 00 03 BD
					39 00 00 40 00 00 02 BD 64
					39 00 00 40 00 00 02 53 24
					39 00 00 40 00 00 02 83 1B
					39 00 00 40 00 00 03 51 00 23
					39 00 00 40 00 00 02 B9 C1
					39 00 00 40 00 00 04 B0 00 08 B9
					39 00 00 40 00 00 07 B9 32 00 02 32 00 02
					39 00 00 40 00 00 04 B0 00 06 B9
					39 00 00 40 00 00 02 B9 03
					39 00 00 40 00 00 02 F7 2F
					39 00 00 40 00 00 03 F0 A5 A5
					39 00 00 00 00 00 03 9F 5A 5A
				];
				mi,mdss-dsi-doze-lbm-command-state = "dsi_hs_mode";

				mi,mdss-dsi-dc-demura-switch-command = [
					39 00 00 60 00 00 03 F0 5A 5A
					39 00 00 60 00 00 04 B0 00 79 62
					15 00 00 60 00 00 02 62 01
					15 00 00 20 00 00 02 F7 2F
					39 00 00 60 00 00 04 B0 01 56 6B
					39 00 00 60 00 00 C2 6B 01 FF FF FF FF FF FF FF
								FF FF FF FF FF FF BF FF BF FF B3 FF
								A6 FF 99 FF 7F FF 73 FF 59 FF 4C FF
								33 FF 33 FF 33 FF 33 FF 33 FF 33 FF
								33 FF 33 FF 33 FF 33 FF 33 FF 33 FF
								33 FF 33 FF 33 FF 33 FF 0C FF FF FF
								FF FF FF FF FF FF FF FF FF FF BF FF
								BF FF B3 FF A6 FF 99 FF 7F FF 73 FF
								59 FF 4C FF 33 FF 33 FF 33 FF 33 FF
								33 FF 33 FF 33 FF 33 FF 33 FF 33 FF
								33 FF 33 FF 33 FF 33 FF 33 FF 33 FF
								0C FF FF FF FF FF FF FF FF FF FF FF
								FF FF BF FF BF FF B3 FF A6 FF 99 FF
								7F FF 73 FF 59 FF 4C FF 33 FF 33 FF
								33 FF 33 FF 33 FF 33 FF 33 FF 33 FF
								33 FF 33 FF 33 FF 33 FF 33 FF 33 FF
								33 FF 33 FF 0C
					39 00 00 60 00 00 03 51 01 9C
					15 00 00 20 00 00 02 F7 2F
					39 00 00 60 00 00 04 B0 01 56 6B
					15 00 00 60 00 00 02 6B 00
					39 00 00 60 00 00 04 B0 00 79 62
					15 00 00 60 00 00 02 62 00
					15 00 00 60 00 00 02 F7 2F
					39 00 00 20 00 00 03 F0 A5 A5
				];
				mi,mdss-dsi-dc-demura-switch-command-state = "dsi_hs_mode";

				mi,mdss-dsi-pwm-demura-switch-command = [
					39 00 00 60 00 00 03 F0 5A 5A
					39 00 00 60 00 00 04 B0 00 79 62
					15 00 00 60 00 00 02 62 01
					15 00 00 20 00 00 02 F7 2F
					39 00 00 60 00 00 04 B0 01 56 6B
					39 00 00 60 00 00 C2 6B 01 00 00 00 00 00 00 00
								00 00 00 00 00 00 00 00 00 00 00 00
								00 00 00 00 00 00 00 00 00 00 00 00
								00 00 00 00 00 00 66 00 66 00 66 00
								66 00 66 00 66 00 66 00 66 00 66 00
								66 00 66 00 66 00 66 00 80 00 00 00
								00 00 00 00 00 00 00 00 00 00 00 00
								00 00 00 00 00 00 00 00 00 00 00 00
								00 00 00 00 00 00 00 00 00 00 66 00
								66 00 66 00 66 00 66 00 66 00 66 00
								66 00 66 00 66 00 66 00 66 00 66 00
								80 00 00 00 00 00 00 00 00 00 00 00
								00 00 00 00 00 00 00 00 00 00 00 00
								00 00 00 00 00 00 00 00 00 00 00 00
								00 00 66 00 66 00 66 00 66 00 66 00
								66 00 66 00 66 00 66 00 66 00 66 00
								66 00 66 00 80
					39 00 00 60 00 00 03 51 01 9B
					15 00 00 20 00 00 02 F7 2F
					39 00 00 60 00 00 04 B0 01 56 6B
					15 00 00 60 00 00 02 6B 00
					39 00 00 60 00 00 04 B0 00 79 62
					15 00 00 60 00 00 02 62 00
					15 00 00 60 00 00 02 F7 2F
					39 00 00 20 00 00 03 F0 A5 A5
				];
				mi,mdss-dsi-pwm-demura-switch-command-state = "dsi_hs_mode";

				qcom,mdss-dsi-nolp-command = [
					39 00 00 40 00 00 03 9F A5 A5
					39 00 00 40 00 00 03 F0 5A 5A
					39 00 00 40 00 00 04 B0 00 03 BD
					39 00 00 40 00 00 02 BD 66
					39 00 00 40 00 00 02 B9 19
					39 00 00 40 00 00 04 B0 00 08 B9
					39 00 00 40 00 00 07 B9 02 00 02 02 00 02
					39 00 00 40 00 00 04 B0 00 06 B9
					39 00 00 40 00 00 02 B9 00
					39 00 00 40 00 00 02 53 20
					39 00 00 40 00 00 02 83 00
					39 00 00 40 00 00 03 51 00 23
					39 00 00 40 00 00 02 F7 2F
					39 00 00 40 00 00 03 F0 A5 A5
					39 00 00 00 00 00 03 9F 5A 5A
					//90HZ
					39 00 00 40 00 00 03 9F A5 A5
					39 00 00 40 00 00 03 F0 5A 5A
					39 00 00 40 00 00 04 B0 00 03 BD
					39 00 00 40 00 00 02 BD 66
					39 00 00 40 00 00 04 B0 00 08 BD
					39 00 00 40 00 00 02 BD 00
					39 00 00 40 00 00 02 B9 19
					39 00 00 40 00 00 04 B0 00 08 B9
					39 00 00 40 00 00 07 B9 02 00 02 02 00 02
					39 00 00 40 00 00 04 B0 00 06 B9
					39 00 00 40 00 00 02 B9 00
					39 00 00 40 00 00 04 B0 00 91 B9
					39 00 00 40 00 00 02 B9 00
					39 00 00 40 00 00 02 BD 01
					39 00 00 40 00 00 02 83 10
					39 00 00 40 00 00 02 F7 2F
					39 00 00 40 00 00 03 F0 A5 A5
					39 00 00 00 00 00 03 9F 5A 5A
				];
				qcom,mdss-dsi-nolp-command-update = <0x51 11 2>;
				qcom,mdss-dsi-nolp-command-state = "dsi_hs_mode";
				qcom,mdss-dsi-timing-switch-command = [
					39 00 00 40 00 00 03 9F A5 A5
					39 00 00 40 00 00 03 F0 5A 5A
					39 00 00 40 00 00 04 B0 00 03 BD
					39 00 00 40 00 00 02 BD 66
					39 00 00 40 00 00 04 B0 00 08 BD
					39 00 00 40 00 00 02 BD 00
					39 00 00 40 00 00 02 B9 19
					39 00 00 40 00 00 04 B0 00 08 B9
					39 00 00 40 00 00 07 B9 02 00 02 02 00 02
					39 00 00 40 00 00 04 B0 00 06 B9
					39 00 00 40 00 00 02 B9 00
					39 00 00 40 00 00 04 B0 00 91 B9
					39 00 00 40 00 00 02 B9 00
					39 00 00 40 00 00 02 BD 01
					39 00 00 40 00 00 02 83 10
					39 00 00 40 00 00 02 F7 2F
					39 00 00 40 00 00 03 F0 A5 A5
					39 00 00 00 00 00 03 9F 5A 5A
				];
				qcom,mdss-dsi-timing-switch-command-state = "dsi_hs_mode";
				qcom,mdss-dsi-on-command = [
					//DSC setting V1.1
					39 00 00 40 00 00 03 9F A5 A5
					39 00 00 40 00 00 59 9E 11 00 00 AB 30 80 0C 80 05 A0 00 19 02 D0 02 D0
											02 00 02 68 00 20 02 BE 00 0A 00 0C 04 00 03 0D 18 00 10 F0 07 10 20 00
 											06 0F 0F 33 0E 1C 2A 38 46 54 62 69 70 77 79 7B 7D 7E 01 02 22 00 2A 40
											2A BE 3A FC 3A FA 3A F8 3B 38 3B 78 3B B6 4B F6 4C 34 4C 74 5C 74 8C F4
					39 00 00 40 00 00 02 9D 01
					39 00 00 00 00 00 03 9F 5A 5A
					//AD Improve Setting
					39 00 00 40 00 00 03 F0 5A 5A
					39 00 00 40 00 00 03 F1 5A 5A
					15 00 00 40 00 00 02 D0 08
					39 00 00 40 00 00 04 B0 00 60 B7
					15 00 00 40 00 00 02 B7 45
					39 00 00 40 00 00 04 B0 00 6A B7
					15 00 00 40 00 00 02 B7 15
					39 00 00 40 00 00 04 B0 00 6D B7
					15 00 00 40 00 00 02 B7 45
					39 00 00 40 00 00 04 B0 00 77 B7
					15 00 00 40 00 00 02 B7 15
					39 00 00 00 00 00 0E F4 F3 E0 E1 D3 B3 D3 A3 D3 D3 B3 D3 A3 D3
					/* Sleep Out */
					05 00 00 00 78 00 01 11
					//TE ON
					39 00 00 40 00 00 03 9F A5 A5
					39 00 00 40 00 00 02 35 00
					39 00 00 00 00 00 03 9F 5A 5A
					//FIXED TE OFF
					39 00 00 40 00 00 03 F0 5A 5A
					39 00 00 40 00 00 02 B9 00
					39 00 00 40 00 00 04 B0 00 08 B9
					39 00 00 40 00 00 07 B9 00 00 00 00 00 00
					39 00 00 40 00 00 02 F7 0F
					39 00 00 00 00 00 03 F0 A5 A5
					//PAGE ADDRESS SET
					39 00 00 40 00 00 05 2A 00 00 05 9F
					39 00 00 40 00 00 05 2B 00 00 0C 7F
					//Scaler Setting
					39 00 00 40 00 00 03 F0 5A 5A
					39 00 00 40 00 00 02 C3 02
					39 00 00 40 00 00 05 2A 00 00 05 9F
					39 00 00 40 00 00 05 2B 00 00 0C 7F
					39 00 00 40 00 00 03 F0 A5 A5
					//Frequency Change Setting
					39 00 00 40 00 00 03 9F A5 A5
					39 00 00 40 00 00 03 F0 5A 5A
					39 00 00 40 00 00 02 83 00
					39 00 00 40 00 00 02 F7 2F
					39 00 00 40 00 00 03 F0 A5 A5
					39 00 00 00 00 00 03 9F 5A 5A
					//Error Flag Control
					39 00 00 40 00 00 03 F0 5A 5A
					39 00 00 40 00 00 02 E5 15
					39 00 00 40 00 00 04 B0 00 18 ED
					39 00 00 40 00 00 02 ED 1C
					39 00 00 40 00 00 04 B0 00 43 F4
					39 00 00 40 00 00 02 F4 30
					39 00 00 40 00 00 04 B0 00 01 ED
					39 00 00 40 00 00 03 ED 01 40
					39 00 00 00 00 00 03 F0 A5 A5
					//ACL Mode
					39 00 00 40 00 00 03 F0 5A 5A
					39 00 00 40 00 00 02 55 00
					39 00 00 00 00 00 03 F0 A5 A5
					//OD OFF
					39 00 00 40 00 00 03 F0 5A 5A
					39 00 00 40 00 00 04 B0 00 8B 68
					15 00 00 40 00 00 02 68 01
					15 00 00 40 00 00 02 F7 2F
					39 00 00 00 00 00 03 F0 A5 A5
					//Low Frequency Change(Manual Mode)
					39 00 00 40 00 00 03 9F A5 A5
					39 00 00 40 00 00 03 F0 5A 5A
					39 00 00 40 00 00 04 B0 00 03 BD
					39 00 00 40 00 00 02 BD 66
					39 00 00 40 00 00 04 B0 00 08 BD
					39 00 00 40 00 00 02 BD 00
					39 00 00 40 00 00 02 B9 19
					39 00 00 40 00 00 04 B0 00 08 B9
					39 00 00 40 00 00 07 B9 02 00 02 02 00 02
					39 00 00 40 00 00 04 B0 00 06 B9
					39 00 00 40 00 00 02 B9 00
					39 00 00 40 00 00 04 B0 00 91 B9
					39 00 00 40 00 00 02 B9 00
					39 00 00 40 00 00 02 BD 01
					39 00 00 40 00 00 02 83 10
					39 00 00 40 00 00 02 F7 2F
					39 00 00 40 00 00 03 F0 A5 A5
					39 00 00 00 00 00 03 9F 5A 5A
					//Dimming speed
					39 00 00 40 00 00 03 F0 5A 5A
					39 00 00 40 00 00 04 B0 00 20 67
					39 00 00 40 00 00 02 67 06
					39 00 00 40 00 00 02 F7 2F
					39 00 00 00 00 00 03 F0 A5 A5
					/* AOD ON */
					39 00 00 40 00 00 03 9F A5 A5
					39 00 00 40 00 00 03 F0 5A 5A
					15 00 00 40 00 00 02 53 24
					15 00 00 40 00 00 02 83 18
					39 00 00 40 00 00 02 F7 2F
					39 00 00 40 00 00 03 F0 A5 A5
					39 00 00 00 0B 00 03 9F 5A 5A
					/* AOD OFF */
					39 00 00 40 00 00 03 9F A5 A5
					39 00 00 40 00 00 03 F0 5A 5A
					15 00 00 40 00 00 02 53 20
					15 00 00 40 00 00 02 83 00
					39 00 00 40 00 00 02 F7 2F
					39 00 00 40 00 00 03 F0 A5 A5
					39 00 00 00 00 00 03 9F 5A 5A
					//Low Frequency Change(Manual Mode)
					39 00 00 40 00 00 03 9F A5 A5
					39 00 00 40 00 00 03 F0 5A 5A
					39 00 00 40 00 00 04 B0 00 03 BD
					39 00 00 40 00 00 02 BD 66
					39 00 00 40 00 00 04 B0 00 08 BD
					39 00 00 40 00 00 02 BD 00
					39 00 00 40 00 00 02 B9 19
					39 00 00 40 00 00 04 B0 00 08 B9
					39 00 00 40 00 00 07 B9 02 00 02 02 00 02
					39 00 00 40 00 00 04 B0 00 06 B9
					39 00 00 40 00 00 02 B9 00
					39 00 00 40 00 00 04 B0 00 91 B9
					39 00 00 40 00 00 02 B9 00
					39 00 00 40 00 00 02 BD 01
					39 00 00 40 00 00 02 83 10
					39 00 00 40 00 00 02 F7 2F
					39 00 00 40 00 00 03 F0 A5 A5
					39 00 00 00 00 00 03 9F 5A 5A
					//Brightness Control
					39 00 00 40 00 00 02 53 20
					39 00 00 00 00 00 03 51 00 00
					//PWM&DC switch
					39 00 00 40 00 00 03 F0 5A 5A
					39 00 00 40 00 00 04 B0 02 17 6B
					39 00 00 40 00 00 61 6B 00 10 18 20 28 30 38 40 48 50 58 60
							  	68 70 78 80 88 90 98 A0 A8 B0 B8 C0 C8 D0 D8 E0 E8 F0 F8 FF 00
							  	10 18 20 28 30 38 40 48 50 58 60 68 70 78 80 88 90 98 A0 A8 B0
							  	B8 C0 C8 D0 D8 E0 E8 F0 F8 FF 00 10 18 20 28 30 38 40 48 50 58
							  	60 68 70 78 80 88 90 98 A0 A8 B0 B8 C0 C8 D0 D8 E0 E8 F0 F8 FF
					39 00 00 40 00 00 04 B0 00 1E 67
					15 00 00 40 00 00 02 67 11
					15 00 00 40 00 00 02 F7 2F
					39 00 00 00 00 00 03 F0 A5 A5
					/* Display On */
					39 00 00 40 00 00 03 9F A5 A5
					05 00 00 40 00 00 01 29
					39 00 00 00 00 00 03 9F 5A 5A
				];
				qcom,mdss-dsi-on-command-state = "dsi_lp_mode";
			};
			timing@wqhd_normal_40hz_index_03 {
				#include "dsi-panel-o1-38-0c-0b-dsc-cmd-common.dtsi"
				cell-index = <3>;
				qcom,mdss-dsi-panel-framerate = <40>;
				qcom,mdss-dsi-h-sync-skew = <0>;
				mi,mdss-dsi-doze-hbm-command = [
					//120HZ
					39 00 00 40 00 00 03 9F A5 A5
					39 00 00 40 00 00 03 F0 5A 5A
					39 00 00 40 00 00 04 B0 00 03 BD
					39 00 00 40 00 00 02 BD 66
					39 00 00 40 00 00 04 B0 00 08 BD
					39 00 00 40 00 00 02 BD 00
					39 00 00 40 00 00 02 B9 19
					39 00 00 40 00 00 04 B0 00 08 B9
					39 00 00 40 00 00 07 B9 02 00 02 02 00 02
					39 00 00 40 00 00 04 B0 00 06 B9
					39 00 00 40 00 00 02 B9 00
					39 00 00 40 00 00 04 B0 00 91 B9
					39 00 00 40 00 00 02 B9 00
					39 00 00 40 00 00 02 BD 01
					39 00 00 40 00 00 02 83 00
					39 00 00 40 00 00 02 F7 2F
					39 00 00 40 00 00 03 F0 A5 A5
					39 00 00 00 19 00 03 9F 5A 5A
					//1HZ AOD
					39 00 00 40 00 00 03 9F A5 A5
					39 00 00 40 00 00 03 F0 5A 5A
					39 00 00 40 00 00 04 B0 00 03 BD
					39 00 00 40 00 00 02 BD 64
					39 00 00 40 00 00 02 53 24
					39 00 00 40 00 00 02 83 1B
					39 00 00 40 00 00 03 51 01 9C
					39 00 00 40 00 00 02 B9 C1
					39 00 00 40 00 00 04 B0 00 08 B9
					39 00 00 40 00 00 07 B9 32 00 02 32 00 02
					39 00 00 40 00 00 04 B0 00 06 B9
					39 00 00 40 00 00 02 B9 03
					39 00 00 40 00 00 02 F7 2F
					39 00 00 40 00 00 03 F0 A5 A5
					39 00 00 00 00 00 03 9F 5A 5A
				];
				mi,mdss-dsi-doze-hbm-command-state = "dsi_hs_mode";

				mi,mdss-dsi-doze-lbm-command = [
					//120HZ
					39 00 00 40 00 00 03 9F A5 A5
					39 00 00 40 00 00 03 F0 5A 5A
					39 00 00 40 00 00 04 B0 00 03 BD
					39 00 00 40 00 00 02 BD 66
					39 00 00 40 00 00 04 B0 00 08 BD
					39 00 00 40 00 00 02 BD 00
					39 00 00 40 00 00 02 B9 19
					39 00 00 40 00 00 04 B0 00 08 B9
					39 00 00 40 00 00 07 B9 02 00 02 02 00 02
					39 00 00 40 00 00 04 B0 00 06 B9
					39 00 00 40 00 00 02 B9 00
					39 00 00 40 00 00 04 B0 00 91 B9
					39 00 00 40 00 00 02 B9 00
					39 00 00 40 00 00 02 BD 01
					39 00 00 40 00 00 02 83 00
					39 00 00 40 00 00 02 F7 2F
					39 00 00 40 00 00 03 F0 A5 A5
					39 00 00 00 19 00 03 9F 5A 5A
					//1HZ AOD
					39 00 00 40 00 00 03 9F A5 A5
					39 00 00 40 00 00 03 F0 5A 5A
					39 00 00 40 00 00 04 B0 00 03 BD
					39 00 00 40 00 00 02 BD 64
					39 00 00 40 00 00 02 53 24
					39 00 00 40 00 00 02 83 1B
					39 00 00 40 00 00 03 51 00 23
					39 00 00 40 00 00 02 B9 C1
					39 00 00 40 00 00 04 B0 00 08 B9
					39 00 00 40 00 00 07 B9 32 00 02 32 00 02
					39 00 00 40 00 00 04 B0 00 06 B9
					39 00 00 40 00 00 02 B9 03
					39 00 00 40 00 00 02 F7 2F
					39 00 00 40 00 00 03 F0 A5 A5
					39 00 00 00 00 00 03 9F 5A 5A
				];
				mi,mdss-dsi-doze-lbm-command-state = "dsi_hs_mode";

				mi,mdss-dsi-dc-demura-switch-command = [
					39 00 00 60 00 00 03 F0 5A 5A
					39 00 00 60 00 00 04 B0 00 79 62
					15 00 00 60 00 00 02 62 01
					15 00 00 20 00 00 02 F7 2F
					39 00 00 60 00 00 04 B0 01 56 6B
					39 00 00 60 00 00 C2 6B 01 FF FF FF FF FF FF FF
								FF FF FF FF FF FF BF FF BF FF B3 FF
								A6 FF 99 FF 7F FF 73 FF 59 FF 4C FF
								33 FF 33 FF 33 FF 33 FF 33 FF 33 FF
								33 FF 33 FF 33 FF 33 FF 33 FF 33 FF
								33 FF 33 FF 33 FF 33 FF 0C FF FF FF
								FF FF FF FF FF FF FF FF FF FF BF FF
								BF FF B3 FF A6 FF 99 FF 7F FF 73 FF
								59 FF 4C FF 33 FF 33 FF 33 FF 33 FF
								33 FF 33 FF 33 FF 33 FF 33 FF 33 FF
								33 FF 33 FF 33 FF 33 FF 33 FF 33 FF
								0C FF FF FF FF FF FF FF FF FF FF FF
								FF FF BF FF BF FF B3 FF A6 FF 99 FF
								7F FF 73 FF 59 FF 4C FF 33 FF 33 FF
								33 FF 33 FF 33 FF 33 FF 33 FF 33 FF
								33 FF 33 FF 33 FF 33 FF 33 FF 33 FF
								33 FF 33 FF 0C
					39 00 00 60 00 00 03 51 01 9C
					15 00 00 20 00 00 02 F7 2F
					39 00 00 60 00 00 04 B0 01 56 6B
					15 00 00 60 00 00 02 6B 00
					39 00 00 60 00 00 04 B0 00 79 62
					15 00 00 60 00 00 02 62 00
					15 00 00 60 00 00 02 F7 2F
					39 00 00 20 00 00 03 F0 A5 A5
				];
				mi,mdss-dsi-dc-demura-switch-command-state = "dsi_hs_mode";

				mi,mdss-dsi-pwm-demura-switch-command = [
					39 00 00 60 00 00 03 F0 5A 5A
					39 00 00 60 00 00 04 B0 00 79 62
					15 00 00 60 00 00 02 62 01
					15 00 00 20 00 00 02 F7 2F
					39 00 00 60 00 00 04 B0 01 56 6B
					39 00 00 60 00 00 C2 6B 01 00 00 00 00 00 00 00
								00 00 00 00 00 00 00 00 00 00 00 00
								00 00 00 00 00 00 00 00 00 00 00 00
								00 00 00 00 00 00 66 00 66 00 66 00
								66 00 66 00 66 00 66 00 66 00 66 00
								66 00 66 00 66 00 66 00 80 00 00 00
								00 00 00 00 00 00 00 00 00 00 00 00
								00 00 00 00 00 00 00 00 00 00 00 00
								00 00 00 00 00 00 00 00 00 00 66 00
								66 00 66 00 66 00 66 00 66 00 66 00
								66 00 66 00 66 00 66 00 66 00 66 00
								80 00 00 00 00 00 00 00 00 00 00 00
								00 00 00 00 00 00 00 00 00 00 00 00
								00 00 00 00 00 00 00 00 00 00 00 00
								00 00 66 00 66 00 66 00 66 00 66 00
								66 00 66 00 66 00 66 00 66 00 66 00
								66 00 66 00 80
					39 00 00 60 00 00 03 51 01 9B
					15 00 00 20 00 00 02 F7 2F
					39 00 00 60 00 00 04 B0 01 56 6B
					15 00 00 60 00 00 02 6B 00
					39 00 00 60 00 00 04 B0 00 79 62
					15 00 00 60 00 00 02 62 00
					15 00 00 60 00 00 02 F7 2F
					39 00 00 20 00 00 03 F0 A5 A5
				];
				mi,mdss-dsi-pwm-demura-switch-command-state = "dsi_hs_mode";

				qcom,mdss-dsi-nolp-command = [
					39 00 00 40 00 00 03 9F A5 A5
					39 00 00 40 00 00 03 F0 5A 5A
					39 00 00 40 00 00 04 B0 00 03 BD
					39 00 00 40 00 00 02 BD 66
					39 00 00 40 00 00 02 B9 19
					39 00 00 40 00 00 04 B0 00 08 B9
					39 00 00 40 00 00 07 B9 02 00 02 02 00 02
					39 00 00 40 00 00 04 B0 00 06 B9
					39 00 00 40 00 00 02 B9 00
					39 00 00 40 00 00 02 53 20
					39 00 00 40 00 00 02 83 00
					39 00 00 40 00 00 03 51 00 23
					39 00 00 40 00 00 02 F7 2F
					39 00 00 40 00 00 03 F0 A5 A5
					39 00 00 00 00 00 03 9F 5A 5A
					//40HZ
					39 00 00 40 00 00 03 9F A5 A5
					39 00 00 40 00 00 03 F0 5A 5A
					39 00 00 40 00 00 04 B0 00 03 BD
					39 00 00 40 00 00 02 BD 66
					39 00 00 40 00 00 04 B0 00 08 BD
					39 00 00 40 00 00 02 BD 00
					39 00 00 40 00 00 02 B9 19
					39 00 00 40 00 00 04 B0 00 08 B9
					39 00 00 40 00 00 07 B9 02 00 02 02 00 02
					39 00 00 40 00 00 04 B0 00 06 B9
					39 00 00 40 00 00 02 B9 00
					39 00 00 40 00 00 04 B0 00 91 B9
					39 00 00 40 00 00 02 B9 00
					39 00 00 40 00 00 02 BD 01
					39 00 00 40 00 00 02 83 02
					39 00 00 40 00 00 02 F7 2F
					39 00 00 40 00 00 03 F0 A5 A5
					39 00 00 00 00 00 03 9F A5 A5
				];
				qcom,mdss-dsi-nolp-command-update = <0x51 11 2>;
				qcom,mdss-dsi-nolp-command-state = "dsi_hs_mode";
				qcom,mdss-dsi-timing-switch-command = [
					39 00 00 40 00 00 03 9F A5 A5
					39 00 00 40 00 00 03 F0 5A 5A
					39 00 00 40 00 00 04 B0 00 03 BD
					39 00 00 40 00 00 02 BD 66
					39 00 00 40 00 00 04 B0 00 08 BD
					39 00 00 40 00 00 02 BD 00
					39 00 00 40 00 00 02 B9 19
					39 00 00 40 00 00 04 B0 00 08 B9
					39 00 00 40 00 00 07 B9 02 00 02 02 00 02
					39 00 00 40 00 00 04 B0 00 06 B9
					39 00 00 40 00 00 02 B9 00
					39 00 00 40 00 00 04 B0 00 91 B9
					39 00 00 40 00 00 02 B9 00
					39 00 00 40 00 00 02 BD 01
					39 00 00 40 00 00 02 83 02
					39 00 00 40 00 00 02 F7 2F
					39 00 00 40 00 00 03 F0 A5 A5
					39 00 00 00 00 00 03 9F A5 A5
				];
				qcom,mdss-dsi-timing-switch-command-state = "dsi_hs_mode";
				qcom,mdss-dsi-on-command = [
					//DSC setting V1.1
					39 00 00 40 00 00 03 9F A5 A5
					39 00 00 40 00 00 59 9E 11 00 00 AB 30 80 0C 80 05 A0 00 19 02 D0 02 D0
											02 00 02 68 00 20 02 BE 00 0A 00 0C 04 00 03 0D 18 00 10 F0 07 10 20 00
 											06 0F 0F 33 0E 1C 2A 38 46 54 62 69 70 77 79 7B 7D 7E 01 02 22 00 2A 40
											2A BE 3A FC 3A FA 3A F8 3B 38 3B 78 3B B6 4B F6 4C 34 4C 74 5C 74 8C F4
					39 00 00 40 00 00 02 9D 01
					39 00 00 00 00 00 03 9F 5A 5A
					//AD Improve Setting
					39 00 00 40 00 00 03 F0 5A 5A
					39 00 00 40 00 00 03 F1 5A 5A
					15 00 00 40 00 00 02 D0 08
					39 00 00 40 00 00 04 B0 00 60 B7
					15 00 00 40 00 00 02 B7 45
					39 00 00 40 00 00 04 B0 00 6A B7
					15 00 00 40 00 00 02 B7 15
					39 00 00 40 00 00 04 B0 00 6D B7
					15 00 00 40 00 00 02 B7 45
					39 00 00 40 00 00 04 B0 00 77 B7
					15 00 00 40 00 00 02 B7 15
					39 00 00 00 00 00 0E F4 F3 E0 E1 D3 B3 D3 A3 D3 D3 B3 D3 A3 D3
					/* Sleep Out */
					05 00 00 00 78 00 01 11
					//TE ON
					39 00 00 40 00 00 03 9F A5 A5
					39 00 00 40 00 00 02 35 00
					39 00 00 00 00 00 03 9F 5A 5A
					//FIXED TE OFF
					39 00 00 40 00 00 03 F0 5A 5A
					39 00 00 40 00 00 02 B9 00
					39 00 00 40 00 00 04 B0 00 08 B9
					39 00 00 40 00 00 07 B9 00 00 00 00 00 00
					39 00 00 40 00 00 02 F7 0F
					39 00 00 00 00 00 03 F0 A5 A5
					//PAGE ADDRESS SET
					39 00 00 40 00 00 05 2A 00 00 05 9F
					39 00 00 40 00 00 05 2B 00 00 0C 7F
					//Scaler Setting
					39 00 00 40 00 00 03 F0 5A 5A
					39 00 00 40 00 00 02 C3 02
					39 00 00 40 00 00 05 2A 00 00 05 9F
					39 00 00 40 00 00 05 2B 00 00 0C 7F
					39 00 00 40 00 00 03 F0 A5 A5
					//Frequency Change Setting
					39 00 00 40 00 00 03 9F A5 A5
					39 00 00 40 00 00 03 F0 5A 5A
					39 00 00 40 00 00 02 83 00
					39 00 00 40 00 00 02 F7 2F
					39 00 00 40 00 00 03 F0 A5 A5
					39 00 00 00 00 00 03 9F 5A 5A
					//Error Flag Control
					39 00 00 40 00 00 03 F0 5A 5A
					39 00 00 40 00 00 02 E5 15
					39 00 00 40 00 00 04 B0 00 18 ED
					39 00 00 40 00 00 02 ED 1C
					39 00 00 40 00 00 04 B0 00 43 F4
					39 00 00 40 00 00 02 F4 30
					39 00 00 40 00 00 04 B0 00 01 ED
					39 00 00 40 00 00 03 ED 01 40
					39 00 00 00 00 00 03 F0 A5 A5
					//ACL Mode
					39 00 00 40 00 00 03 F0 5A 5A
					39 00 00 40 00 00 02 55 00
					39 00 00 00 00 00 03 F0 A5 A5
					//OD OFF
					39 00 00 40 00 00 03 F0 5A 5A
					39 00 00 40 00 00 04 B0 00 8B 68
					15 00 00 40 00 00 02 68 01
					15 00 00 40 00 00 02 F7 2F
					39 00 00 00 00 00 03 F0 A5 A5
					//Low Frequency Change(Manual Mode)
					39 00 00 40 00 00 03 9F A5 A5
					39 00 00 40 00 00 03 F0 5A 5A
					39 00 00 40 00 00 04 B0 00 03 BD
					39 00 00 40 00 00 02 BD 66
					39 00 00 40 00 00 04 B0 00 08 BD
					39 00 00 40 00 00 02 BD 00
					39 00 00 40 00 00 02 B9 19
					39 00 00 40 00 00 04 B0 00 08 B9
					39 00 00 40 00 00 07 B9 02 00 02 02 00 02
					39 00 00 40 00 00 04 B0 00 06 B9
					39 00 00 40 00 00 02 B9 00
					39 00 00 40 00 00 04 B0 00 91 B9
					39 00 00 40 00 00 02 B9 00
					39 00 00 40 00 00 02 BD 01
					39 00 00 40 00 00 02 83 02
					39 00 00 40 00 00 02 F7 2F
					39 00 00 40 00 00 03 F0 A5 A5
					39 00 00 00 00 00 03 9F A5 A5
					//Dimming speed
					39 00 00 40 00 00 03 F0 5A 5A
					39 00 00 40 00 00 04 B0 00 20 67
					39 00 00 40 00 00 02 67 06
					39 00 00 40 00 00 02 F7 2F
					39 00 00 00 00 00 03 F0 A5 A5
					/* AOD ON */
					39 00 00 40 00 00 03 9F A5 A5
					39 00 00 40 00 00 03 F0 5A 5A
					15 00 00 40 00 00 02 53 24
					15 00 00 40 00 00 02 83 18
					39 00 00 40 00 00 02 F7 2F
					39 00 00 40 00 00 03 F0 A5 A5
					39 00 00 00 0B 00 03 9F 5A 5A
					/* AOD OFF */
					39 00 00 40 00 00 03 9F A5 A5
					39 00 00 40 00 00 03 F0 5A 5A
					15 00 00 40 00 00 02 53 20
					15 00 00 40 00 00 02 83 00
					39 00 00 40 00 00 02 F7 2F
					39 00 00 40 00 00 03 F0 A5 A5
					39 00 00 00 00 00 03 9F 5A 5A
					//Low Frequency Change(Manual Mode)
					39 00 00 40 00 00 03 9F A5 A5
					39 00 00 40 00 00 03 F0 5A 5A
					39 00 00 40 00 00 04 B0 00 03 BD
					39 00 00 40 00 00 02 BD 66
					39 00 00 40 00 00 04 B0 00 08 BD
					39 00 00 40 00 00 02 BD 00
					39 00 00 40 00 00 02 B9 19
					39 00 00 40 00 00 04 B0 00 08 B9
					39 00 00 40 00 00 07 B9 02 00 02 02 00 02
					39 00 00 40 00 00 04 B0 00 06 B9
					39 00 00 40 00 00 02 B9 00
					39 00 00 40 00 00 04 B0 00 91 B9
					39 00 00 40 00 00 02 B9 00
					39 00 00 40 00 00 02 BD 01
					39 00 00 40 00 00 02 83 02
					39 00 00 40 00 00 02 F7 2F
					39 00 00 40 00 00 03 F0 A5 A5
					39 00 00 00 00 00 03 9F A5 A5
					//Brightness Control
					39 00 00 40 00 00 02 53 20
					39 00 00 00 00 00 03 51 00 00
					//PWM&DC switch
					39 00 00 40 00 00 03 F0 5A 5A
					39 00 00 40 00 00 04 B0 02 17 6B
					39 00 00 40 00 00 61 6B 00 10 18 20 28 30 38 40 48 50 58 60
							  	68 70 78 80 88 90 98 A0 A8 B0 B8 C0 C8 D0 D8 E0 E8 F0 F8 FF 00
							  	10 18 20 28 30 38 40 48 50 58 60 68 70 78 80 88 90 98 A0 A8 B0
							  	B8 C0 C8 D0 D8 E0 E8 F0 F8 FF 00 10 18 20 28 30 38 40 48 50 58
							  	60 68 70 78 80 88 90 98 A0 A8 B0 B8 C0 C8 D0 D8 E0 E8 F0 F8 FF
					39 00 00 40 00 00 04 B0 00 1E 67
					15 00 00 40 00 00 02 67 11
					15 00 00 40 00 00 02 F7 2F
					39 00 00 00 00 00 03 F0 A5 A5
					/* Display On */
					39 00 00 40 00 00 03 9F A5 A5
					05 00 00 40 00 00 01 29
					39 00 00 00 00 00 03 9F 5A 5A
				];
				qcom,mdss-dsi-on-command-state = "dsi_lp_mode";
			};
			timing@wqhd_normal_30hz_index_04 {
				#include "dsi-panel-o1-38-0c-0b-dsc-cmd-common.dtsi"
				cell-index = <4>;
				qcom,mdss-dsi-panel-framerate = <30>;
				qcom,mdss-dsi-h-sync-skew = <0>;
				mi,mdss-dsi-doze-hbm-command = [
					//120HZ
					39 00 00 40 00 00 03 9F A5 A5
					39 00 00 40 00 00 03 F0 5A 5A
					39 00 00 40 00 00 04 B0 00 03 BD
					39 00 00 40 00 00 02 BD 66
					39 00 00 40 00 00 04 B0 00 08 BD
					39 00 00 40 00 00 02 BD 00
					39 00 00 40 00 00 02 B9 19
					39 00 00 40 00 00 04 B0 00 08 B9
					39 00 00 40 00 00 07 B9 02 00 02 02 00 02
					39 00 00 40 00 00 04 B0 00 06 B9
					39 00 00 40 00 00 02 B9 00
					39 00 00 40 00 00 04 B0 00 91 B9
					39 00 00 40 00 00 02 B9 00
					39 00 00 40 00 00 02 BD 01
					39 00 00 40 00 00 02 83 00
					39 00 00 40 00 00 02 F7 2F
					39 00 00 40 00 00 03 F0 A5 A5
					39 00 00 00 20 00 03 9F 5A 5A
					//1HZ AOD
					39 00 00 40 00 00 03 9F A5 A5
					39 00 00 40 00 00 03 F0 5A 5A
					39 00 00 40 00 00 04 B0 00 03 BD
					39 00 00 40 00 00 02 BD 64
					39 00 00 40 00 00 02 53 24
					39 00 00 40 00 00 02 83 1B
					39 00 00 40 00 00 03 51 01 9C
					39 00 00 40 00 00 02 B9 C1
					39 00 00 40 00 00 04 B0 00 08 B9
					39 00 00 40 00 00 07 B9 32 00 02 32 00 02
					39 00 00 40 00 00 04 B0 00 06 B9
					39 00 00 40 00 00 02 B9 03
					39 00 00 40 00 00 02 F7 2F
					39 00 00 40 00 00 03 F0 A5 A5
					39 00 00 00 00 00 03 9F 5A 5A
				];
				mi,mdss-dsi-doze-hbm-command-state = "dsi_hs_mode";

				mi,mdss-dsi-doze-lbm-command = [
					//120HZ
					39 00 00 40 00 00 03 9F A5 A5
					39 00 00 40 00 00 03 F0 5A 5A
					39 00 00 40 00 00 04 B0 00 03 BD
					39 00 00 40 00 00 02 BD 66
					39 00 00 40 00 00 04 B0 00 08 BD
					39 00 00 40 00 00 02 BD 00
					39 00 00 40 00 00 02 B9 19
					39 00 00 40 00 00 04 B0 00 08 B9
					39 00 00 40 00 00 07 B9 02 00 02 02 00 02
					39 00 00 40 00 00 04 B0 00 06 B9
					39 00 00 40 00 00 02 B9 00
					39 00 00 40 00 00 04 B0 00 91 B9
					39 00 00 40 00 00 02 B9 00
					39 00 00 40 00 00 02 BD 01
					39 00 00 40 00 00 02 83 00
					39 00 00 40 00 00 02 F7 2F
					39 00 00 40 00 00 03 F0 A5 A5
					39 00 00 00 20 00 03 9F 5A 5A
					//1HZ AOD
					39 00 00 40 00 00 03 9F A5 A5
					39 00 00 40 00 00 03 F0 5A 5A
					39 00 00 40 00 00 04 B0 00 03 BD
					39 00 00 40 00 00 02 BD 64
					39 00 00 40 00 00 02 53 24
					39 00 00 40 00 00 02 83 1B
					39 00 00 40 00 00 03 51 00 23
					39 00 00 40 00 00 02 B9 C1
					39 00 00 40 00 00 04 B0 00 08 B9
					39 00 00 40 00 00 07 B9 32 00 02 32 00 02
					39 00 00 40 00 00 04 B0 00 06 B9
					39 00 00 40 00 00 02 B9 03
					39 00 00 40 00 00 02 F7 2F
					39 00 00 40 00 00 03 F0 A5 A5
					39 00 00 00 00 00 03 9F 5A 5A
				];
				mi,mdss-dsi-doze-lbm-command-state = "dsi_hs_mode";

				mi,mdss-dsi-dc-demura-switch-command = [
					39 00 00 60 00 00 03 F0 5A 5A
					39 00 00 60 00 00 04 B0 00 79 62
					15 00 00 60 00 00 02 62 01
					15 00 00 20 00 00 02 F7 2F
					39 00 00 60 00 00 04 B0 01 56 6B
					39 00 00 60 00 00 C2 6B 01 FF FF FF FF FF FF FF
								FF FF FF FF FF FF BF FF BF FF B3 FF
								A6 FF 99 FF 7F FF 73 FF 59 FF 4C FF
								33 FF 33 FF 33 FF 33 FF 33 FF 33 FF
								33 FF 33 FF 33 FF 33 FF 33 FF 33 FF
								33 FF 33 FF 33 FF 33 FF 0C FF FF FF
								FF FF FF FF FF FF FF FF FF FF BF FF
								BF FF B3 FF A6 FF 99 FF 7F FF 73 FF
								59 FF 4C FF 33 FF 33 FF 33 FF 33 FF
								33 FF 33 FF 33 FF 33 FF 33 FF 33 FF
								33 FF 33 FF 33 FF 33 FF 33 FF 33 FF
								0C FF FF FF FF FF FF FF FF FF FF FF
								FF FF BF FF BF FF B3 FF A6 FF 99 FF
								7F FF 73 FF 59 FF 4C FF 33 FF 33 FF
								33 FF 33 FF 33 FF 33 FF 33 FF 33 FF
								33 FF 33 FF 33 FF 33 FF 33 FF 33 FF
								33 FF 33 FF 0C
					39 00 00 60 00 00 03 51 01 9C
					15 00 00 20 00 00 02 F7 2F
					39 00 00 60 00 00 04 B0 01 56 6B
					15 00 00 60 00 00 02 6B 00
					39 00 00 60 00 00 04 B0 00 79 62
					15 00 00 60 00 00 02 62 00
					15 00 00 60 00 00 02 F7 2F
					39 00 00 20 00 00 03 F0 A5 A5
				];
				mi,mdss-dsi-dc-demura-switch-command-state = "dsi_hs_mode";

				mi,mdss-dsi-pwm-demura-switch-command = [
					39 00 00 60 00 00 03 F0 5A 5A
					39 00 00 60 00 00 04 B0 00 79 62
					15 00 00 60 00 00 02 62 01
					15 00 00 20 00 00 02 F7 2F
					39 00 00 60 00 00 04 B0 01 56 6B
					39 00 00 60 00 00 C2 6B 01 00 00 00 00 00 00 00
								00 00 00 00 00 00 00 00 00 00 00 00
								00 00 00 00 00 00 00 00 00 00 00 00
								00 00 00 00 00 00 66 00 66 00 66 00
								66 00 66 00 66 00 66 00 66 00 66 00
								66 00 66 00 66 00 66 00 80 00 00 00
								00 00 00 00 00 00 00 00 00 00 00 00
								00 00 00 00 00 00 00 00 00 00 00 00
								00 00 00 00 00 00 00 00 00 00 66 00
								66 00 66 00 66 00 66 00 66 00 66 00
								66 00 66 00 66 00 66 00 66 00 66 00
								80 00 00 00 00 00 00 00 00 00 00 00
								00 00 00 00 00 00 00 00 00 00 00 00
								00 00 00 00 00 00 00 00 00 00 00 00
								00 00 66 00 66 00 66 00 66 00 66 00
								66 00 66 00 66 00 66 00 66 00 66 00
								66 00 66 00 80
					39 00 00 60 00 00 03 51 01 9B
					15 00 00 20 00 00 02 F7 2F
					39 00 00 60 00 00 04 B0 01 56 6B
					15 00 00 60 00 00 02 6B 00
					39 00 00 60 00 00 04 B0 00 79 62
					15 00 00 60 00 00 02 62 00
					15 00 00 60 00 00 02 F7 2F
					39 00 00 20 00 00 03 F0 A5 A5
				];
				mi,mdss-dsi-pwm-demura-switch-command-state = "dsi_hs_mode";

				qcom,mdss-dsi-nolp-command = [
					39 00 00 40 00 00 03 9F A5 A5
					39 00 00 40 00 00 03 F0 5A 5A
					39 00 00 40 00 00 04 B0 00 03 BD
					39 00 00 40 00 00 02 BD 66
					39 00 00 40 00 00 02 B9 19
					39 00 00 40 00 00 04 B0 00 08 B9
					39 00 00 40 00 00 07 B9 02 00 02 02 00 02
					39 00 00 40 00 00 04 B0 00 06 B9
					39 00 00 40 00 00 02 B9 00
					39 00 00 40 00 00 02 53 20
					39 00 00 40 00 00 02 83 00
					39 00 00 40 00 00 03 51 00 23
					39 00 00 40 00 00 02 F7 2F
					39 00 00 40 00 00 03 F0 A5 A5
					39 00 00 00 00 00 03 9F 5A 5A
					//30HZ
					39 00 00 40 00 00 03 9F A5 A5
					39 00 00 40 00 00 03 F0 5A 5A
					39 00 00 40 00 00 04 B0 00 03 BD
					39 00 00 40 00 00 02 BD 66
					39 00 00 40 00 00 04 B0 00 08 BD
					39 00 00 40 00 00 02 BD 00
					39 00 00 40 00 00 02 B9 19
					39 00 00 40 00 00 04 B0 00 08 B9
					39 00 00 40 00 00 07 B9 02 00 02 02 00 02
					39 00 00 40 00 00 04 B0 00 06 B9
					39 00 00 40 00 00 02 B9 00
					39 00 00 40 00 00 04 B0 00 91 B9
					39 00 00 40 00 00 02 B9 00
					39 00 00 40 00 00 02 BD 01
					39 00 00 40 00 00 02 83 03
					39 00 00 40 00 00 02 F7 2F
					39 00 00 40 00 00 03 F0 A5 A5
					39 00 00 00 00 00 03 9F 5A 5A
				];
				qcom,mdss-dsi-nolp-command-update = <0x51 11 2>;
				qcom,mdss-dsi-nolp-command-state = "dsi_hs_mode";
				qcom,mdss-dsi-timing-switch-command = [
					39 00 00 40 00 00 03 9F A5 A5
					39 00 00 40 00 00 03 F0 5A 5A
					39 00 00 40 00 00 04 B0 00 03 BD
					39 00 00 40 00 00 02 BD 66
					39 00 00 40 00 00 04 B0 00 08 BD
					39 00 00 40 00 00 02 BD 00
					39 00 00 40 00 00 02 B9 19
					39 00 00 40 00 00 04 B0 00 08 B9
					39 00 00 40 00 00 07 B9 02 00 02 02 00 02
					39 00 00 40 00 00 04 B0 00 06 B9
					39 00 00 40 00 00 02 B9 00
					39 00 00 40 00 00 04 B0 00 91 B9
					39 00 00 40 00 00 02 B9 00
					39 00 00 40 00 00 02 BD 01
					39 00 00 40 00 00 02 83 03
					39 00 00 40 00 00 02 F7 2F
					39 00 00 40 00 00 03 F0 A5 A5
					39 00 00 00 00 00 03 9F A5 A5
				];
				qcom,mdss-dsi-timing-switch-command-state = "dsi_hs_mode";
				qcom,mdss-dsi-on-command = [
					//DSC setting V1.1
					39 00 00 40 00 00 03 9F A5 A5
					39 00 00 40 00 00 59 9E 11 00 00 AB 30 80 0C 80 05 A0 00 19 02 D0 02 D0
											02 00 02 68 00 20 02 BE 00 0A 00 0C 04 00 03 0D 18 00 10 F0 07 10 20 00
 											06 0F 0F 33 0E 1C 2A 38 46 54 62 69 70 77 79 7B 7D 7E 01 02 22 00 2A 40
											2A BE 3A FC 3A FA 3A F8 3B 38 3B 78 3B B6 4B F6 4C 34 4C 74 5C 74 8C F4
					39 00 00 40 00 00 02 9D 01
					39 00 00 00 00 00 03 9F 5A 5A
					//AD Improve Setting
					39 00 00 40 00 00 03 F0 5A 5A
					39 00 00 40 00 00 03 F1 5A 5A
					15 00 00 40 00 00 02 D0 08
					39 00 00 40 00 00 04 B0 00 60 B7
					15 00 00 40 00 00 02 B7 45
					39 00 00 40 00 00 04 B0 00 6A B7
					15 00 00 40 00 00 02 B7 15
					39 00 00 40 00 00 04 B0 00 6D B7
					15 00 00 40 00 00 02 B7 45
					39 00 00 40 00 00 04 B0 00 77 B7
					15 00 00 40 00 00 02 B7 15
					39 00 00 00 00 00 0E F4 F3 E0 E1 D3 B3 D3 A3 D3 D3 B3 D3 A3 D3
					/* Sleep Out */
					05 00 00 00 78 00 01 11
					//TE ON
					39 00 00 40 00 00 03 9F A5 A5
					39 00 00 40 00 00 02 35 00
					39 00 00 00 00 00 03 9F 5A 5A
					//FIXED TE OFF
					39 00 00 40 00 00 03 F0 5A 5A
					39 00 00 40 00 00 02 B9 00
					39 00 00 40 00 00 04 B0 00 08 B9
					39 00 00 40 00 00 07 B9 00 00 00 00 00 00
					39 00 00 40 00 00 02 F7 0F
					39 00 00 00 00 00 03 F0 A5 A5
					//PAGE ADDRESS SET
					39 00 00 40 00 00 05 2A 00 00 05 9F
					39 00 00 40 00 00 05 2B 00 00 0C 7F
					//Scaler Setting
					39 00 00 40 00 00 03 F0 5A 5A
					39 00 00 40 00 00 02 C3 02
					39 00 00 40 00 00 05 2A 00 00 05 9F
					39 00 00 40 00 00 05 2B 00 00 0C 7F
					39 00 00 40 00 00 03 F0 A5 A5
					//Frequency Change Setting
					39 00 00 40 00 00 03 9F A5 A5
					39 00 00 40 00 00 03 F0 5A 5A
					39 00 00 40 00 00 02 83 00
					39 00 00 40 00 00 02 F7 2F
					39 00 00 40 00 00 03 F0 A5 A5
					39 00 00 00 00 00 03 9F 5A 5A
					//Error Flag Control
					39 00 00 40 00 00 03 F0 5A 5A
					39 00 00 40 00 00 02 E5 15
					39 00 00 40 00 00 04 B0 00 18 ED
					39 00 00 40 00 00 02 ED 1C
					39 00 00 40 00 00 04 B0 00 43 F4
					39 00 00 40 00 00 02 F4 30
					39 00 00 40 00 00 04 B0 00 01 ED
					39 00 00 40 00 00 03 ED 01 40
					39 00 00 00 00 00 03 F0 A5 A5
					//ACL Mode
					39 00 00 40 00 00 03 F0 5A 5A
					39 00 00 40 00 00 02 55 00
					39 00 00 00 00 00 03 F0 A5 A5
					//OD OFF
					39 00 00 40 00 00 03 F0 5A 5A
					39 00 00 40 00 00 04 B0 00 8B 68
					15 00 00 40 00 00 02 68 01
					15 00 00 40 00 00 02 F7 2F
					39 00 00 00 00 00 03 F0 A5 A5
					//Low Frequency Change(Manual Mode)
					39 00 00 40 00 00 03 9F A5 A5
					39 00 00 40 00 00 03 F0 5A 5A
					39 00 00 40 00 00 04 B0 00 03 BD
					39 00 00 40 00 00 02 BD 66
					39 00 00 40 00 00 04 B0 00 08 BD
					39 00 00 40 00 00 02 BD 00
					39 00 00 40 00 00 02 B9 19
					39 00 00 40 00 00 04 B0 00 08 B9
					39 00 00 40 00 00 07 B9 02 00 02 02 00 02
					39 00 00 40 00 00 04 B0 00 06 B9
					39 00 00 40 00 00 02 B9 00
					39 00 00 40 00 00 04 B0 00 91 B9
					39 00 00 40 00 00 02 B9 00
					39 00 00 40 00 00 02 BD 01
					39 00 00 40 00 00 02 83 03
					39 00 00 40 00 00 02 F7 2F
					39 00 00 40 00 00 03 F0 A5 A5
					39 00 00 00 00 00 03 9F 5A 5A
					//Dimming speed
					39 00 00 40 00 00 03 F0 5A 5A
					39 00 00 40 00 00 04 B0 00 20 67
					39 00 00 40 00 00 02 67 06
					39 00 00 40 00 00 02 F7 2F
					39 00 00 00 00 00 03 F0 A5 A5
					/* AOD ON */
					39 00 00 40 00 00 03 9F A5 A5
					39 00 00 40 00 00 03 F0 5A 5A
					15 00 00 40 00 00 02 53 24
					15 00 00 40 00 00 02 83 18
					39 00 00 40 00 00 02 F7 2F
					39 00 00 40 00 00 03 F0 A5 A5
					39 00 00 00 0B 00 03 9F 5A 5A
					/* AOD OFF */
					39 00 00 40 00 00 03 9F A5 A5
					39 00 00 40 00 00 03 F0 5A 5A
					15 00 00 40 00 00 02 53 20
					15 00 00 40 00 00 02 83 00
					39 00 00 40 00 00 02 F7 2F
					39 00 00 40 00 00 03 F0 A5 A5
					39 00 00 00 00 00 03 9F 5A 5A
					//Low Frequency Change(Manual Mode)
					39 00 00 40 00 00 03 9F A5 A5
					39 00 00 40 00 00 03 F0 5A 5A
					39 00 00 40 00 00 04 B0 00 03 BD
					39 00 00 40 00 00 02 BD 66
					39 00 00 40 00 00 04 B0 00 08 BD
					39 00 00 40 00 00 02 BD 00
					39 00 00 40 00 00 02 B9 19
					39 00 00 40 00 00 04 B0 00 08 B9
					39 00 00 40 00 00 07 B9 02 00 02 02 00 02
					39 00 00 40 00 00 04 B0 00 06 B9
					39 00 00 40 00 00 02 B9 00
					39 00 00 40 00 00 04 B0 00 91 B9
					39 00 00 40 00 00 02 B9 00 
					39 00 00 40 00 00 02 BD 01
					39 00 00 40 00 00 02 83 03
					39 00 00 40 00 00 02 F7 2F
					39 00 00 40 00 00 03 F0 A5 A5
					39 00 00 00 00 00 03 9F A5 A5
					//Brightness Control
					39 00 00 40 00 00 02 53 20
					39 00 00 00 00 00 03 51 00 00
					//PWM&DC switch
					39 00 00 40 00 00 03 F0 5A 5A
					39 00 00 40 00 00 04 B0 02 17 6B
					39 00 00 40 00 00 61 6B 00 10 18 20 28 30 38 40 48 50 58 60
							  	68 70 78 80 88 90 98 A0 A8 B0 B8 C0 C8 D0 D8 E0 E8 F0 F8 FF 00
							  	10 18 20 28 30 38 40 48 50 58 60 68 70 78 80 88 90 98 A0 A8 B0
							  	B8 C0 C8 D0 D8 E0 E8 F0 F8 FF 00 10 18 20 28 30 38 40 48 50 58
							  	60 68 70 78 80 88 90 98 A0 A8 B0 B8 C0 C8 D0 D8 E0 E8 F0 F8 FF
					39 00 00 40 00 00 04 B0 00 1E 67
					15 00 00 40 00 00 02 67 11
					15 00 00 40 00 00 02 F7 2F
					39 00 00 00 00 00 03 F0 A5 A5
					/* Display On */
					39 00 00 40 00 00 03 9F A5 A5
					05 00 00 40 00 00 01 29
					39 00 00 00 00 00 03 9F 5A 5A
				];
				qcom,mdss-dsi-on-command-state = "dsi_lp_mode";
			};
			timing@wqhd_normal_24hz_index_05 {
				#include "dsi-panel-o1-38-0c-0b-dsc-cmd-common.dtsi"
				cell-index = <5>;
				qcom,mdss-dsi-panel-framerate = <24>;
				qcom,mdss-dsi-h-sync-skew = <0>;
				mi,mdss-dsi-doze-hbm-command = [
					//120HZ
					39 00 00 40 00 00 03 9F A5 A5
					39 00 00 40 00 00 03 F0 5A 5A
					39 00 00 40 00 00 04 B0 00 03 BD
					39 00 00 40 00 00 02 BD 66
					39 00 00 40 00 00 04 B0 00 08 BD
					39 00 00 40 00 00 02 BD 00
					39 00 00 40 00 00 02 B9 19
					39 00 00 40 00 00 04 B0 00 08 B9
					39 00 00 40 00 00 07 B9 02 00 02 02 00 02
					39 00 00 40 00 00 04 B0 00 06 B9
					39 00 00 40 00 00 02 B9 00
					39 00 00 40 00 00 04 B0 00 91 B9
					39 00 00 40 00 00 02 B9 00
					39 00 00 40 00 00 02 BD 01
					39 00 00 40 00 00 02 83 00
					39 00 00 40 00 00 02 F7 2F
					39 00 00 40 00 00 03 F0 A5 A5
					39 00 00 00 2A 00 03 9F 5A 5A
					//1HZ AOD
					39 00 00 40 00 00 03 9F A5 A5
					39 00 00 40 00 00 03 F0 5A 5A
					39 00 00 40 00 00 04 B0 00 03 BD
					39 00 00 40 00 00 02 BD 64
					39 00 00 40 00 00 02 53 24
					39 00 00 40 00 00 02 83 1B
					39 00 00 40 00 00 03 51 01 9C
					39 00 00 40 00 00 02 B9 C1
					39 00 00 40 00 00 04 B0 00 08 B9
					39 00 00 40 00 00 07 B9 32 00 02 32 00 02
					39 00 00 40 00 00 04 B0 00 06 B9
					39 00 00 40 00 00 02 B9 03
					39 00 00 40 00 00 02 F7 2F
					39 00 00 40 00 00 03 F0 A5 A5
					39 00 00 00 00 00 03 9F 5A 5A
				];
				mi,mdss-dsi-doze-hbm-command-state = "dsi_hs_mode";

				mi,mdss-dsi-doze-lbm-command = [
					//120HZ
					39 00 00 40 00 00 03 9F A5 A5
					39 00 00 40 00 00 03 F0 5A 5A
					39 00 00 40 00 00 04 B0 00 03 BD
					39 00 00 40 00 00 02 BD 66
					39 00 00 40 00 00 04 B0 00 08 BD
					39 00 00 40 00 00 02 BD 00
					39 00 00 40 00 00 02 B9 19
					39 00 00 40 00 00 04 B0 00 08 B9
					39 00 00 40 00 00 07 B9 02 00 02 02 00 02
					39 00 00 40 00 00 04 B0 00 06 B9
					39 00 00 40 00 00 02 B9 00
					39 00 00 40 00 00 04 B0 00 91 B9
					39 00 00 40 00 00 02 B9 00
					39 00 00 40 00 00 02 BD 01
					39 00 00 40 00 00 02 83 00
					39 00 00 40 00 00 02 F7 2F
					39 00 00 40 00 00 03 F0 A5 A5
					39 00 00 00 2A 00 03 9F 5A 5A
					//1HZ AOD
					39 00 00 40 00 00 03 9F A5 A5
					39 00 00 40 00 00 03 F0 5A 5A
					39 00 00 40 00 00 04 B0 00 03 BD
					39 00 00 40 00 00 02 BD 64
					39 00 00 40 00 00 02 53 24
					39 00 00 40 00 00 02 83 1B
					39 00 00 40 00 00 03 51 00 23
					39 00 00 40 00 00 02 B9 C1
					39 00 00 40 00 00 04 B0 00 08 B9
					39 00 00 40 00 00 07 B9 32 00 02 32 00 02
					39 00 00 40 00 00 04 B0 00 06 B9
					39 00 00 40 00 00 02 B9 03
					39 00 00 40 00 00 02 F7 2F
					39 00 00 40 00 00 03 F0 A5 A5
					39 00 00 00 00 00 03 9F 5A 5A
				];
				mi,mdss-dsi-doze-lbm-command-state = "dsi_hs_mode";

				mi,mdss-dsi-dc-demura-switch-command = [
					39 00 00 60 00 00 03 F0 5A 5A
					39 00 00 60 00 00 04 B0 00 79 62
					15 00 00 60 00 00 02 62 01
					15 00 00 20 00 00 02 F7 2F
					39 00 00 60 00 00 04 B0 01 56 6B
					39 00 00 60 00 00 C2 6B 01 FF FF FF FF FF FF FF
								FF FF FF FF FF FF BF FF BF FF B3 FF
								A6 FF 99 FF 7F FF 73 FF 59 FF 4C FF
								33 FF 33 FF 33 FF 33 FF 33 FF 33 FF
								33 FF 33 FF 33 FF 33 FF 33 FF 33 FF
								33 FF 33 FF 33 FF 33 FF 0C FF FF FF
								FF FF FF FF FF FF FF FF FF FF BF FF
								BF FF B3 FF A6 FF 99 FF 7F FF 73 FF
								59 FF 4C FF 33 FF 33 FF 33 FF 33 FF
								33 FF 33 FF 33 FF 33 FF 33 FF 33 FF
								33 FF 33 FF 33 FF 33 FF 33 FF 33 FF
								0C FF FF FF FF FF FF FF FF FF FF FF
								FF FF BF FF BF FF B3 FF A6 FF 99 FF
								7F FF 73 FF 59 FF 4C FF 33 FF 33 FF
								33 FF 33 FF 33 FF 33 FF 33 FF 33 FF
								33 FF 33 FF 33 FF 33 FF 33 FF 33 FF
								33 FF 33 FF 0C
					39 00 00 60 00 00 03 51 01 9C
					15 00 00 20 00 00 02 F7 2F
					39 00 00 60 00 00 04 B0 01 56 6B
					15 00 00 60 00 00 02 6B 00
					39 00 00 60 00 00 04 B0 00 79 62
					15 00 00 60 00 00 02 62 00
					15 00 00 60 00 00 02 F7 2F
					39 00 00 20 00 00 03 F0 A5 A5
				];
				mi,mdss-dsi-dc-demura-switch-command-state = "dsi_hs_mode";

				mi,mdss-dsi-pwm-demura-switch-command = [
					39 00 00 60 00 00 03 F0 5A 5A
					39 00 00 60 00 00 04 B0 00 79 62
					15 00 00 60 00 00 02 62 01
					15 00 00 20 00 00 02 F7 2F
					39 00 00 60 00 00 04 B0 01 56 6B
					39 00 00 60 00 00 C2 6B 01 00 00 00 00 00 00 00
								00 00 00 00 00 00 00 00 00 00 00 00
								00 00 00 00 00 00 00 00 00 00 00 00
								00 00 00 00 00 00 66 00 66 00 66 00
								66 00 66 00 66 00 66 00 66 00 66 00
								66 00 66 00 66 00 66 00 80 00 00 00
								00 00 00 00 00 00 00 00 00 00 00 00
								00 00 00 00 00 00 00 00 00 00 00 00
								00 00 00 00 00 00 00 00 00 00 66 00
								66 00 66 00 66 00 66 00 66 00 66 00
								66 00 66 00 66 00 66 00 66 00 66 00
								80 00 00 00 00 00 00 00 00 00 00 00
								00 00 00 00 00 00 00 00 00 00 00 00
								00 00 00 00 00 00 00 00 00 00 00 00
								00 00 66 00 66 00 66 00 66 00 66 00
								66 00 66 00 66 00 66 00 66 00 66 00
								66 00 66 00 80
					39 00 00 60 00 00 03 51 01 9B
					15 00 00 20 00 00 02 F7 2F
					39 00 00 60 00 00 04 B0 01 56 6B
					15 00 00 60 00 00 02 6B 00
					39 00 00 60 00 00 04 B0 00 79 62
					15 00 00 60 00 00 02 62 00
					15 00 00 60 00 00 02 F7 2F
					39 00 00 20 00 00 03 F0 A5 A5
				];
				mi,mdss-dsi-pwm-demura-switch-command-state = "dsi_hs_mode";

				qcom,mdss-dsi-nolp-command = [
					39 00 00 40 00 00 03 9F A5 A5
					39 00 00 40 00 00 03 F0 5A 5A
					39 00 00 40 00 00 04 B0 00 03 BD
					39 00 00 40 00 00 02 BD 66
					39 00 00 40 00 00 02 B9 19
					39 00 00 40 00 00 04 B0 00 08 B9
					39 00 00 40 00 00 07 B9 02 00 02 02 00 02
					39 00 00 40 00 00 04 B0 00 06 B9
					39 00 00 40 00 00 02 B9 00
					39 00 00 40 00 00 02 53 20
					39 00 00 40 00 00 02 83 00
					39 00 00 40 00 00 03 51 00 23
					39 00 00 40 00 00 02 F7 2F
					39 00 00 40 00 00 03 F0 A5 A5
					39 00 00 00 00 00 03 9F 5A 5A
					//24HZ
					39 00 00 40 00 00 03 9F A5 A5
					39 00 00 40 00 00 03 F0 5A 5A
					39 00 00 40 00 00 04 B0 00 03 BD
					39 00 00 40 00 00 02 BD 66
					39 00 00 40 00 00 04 B0 00 08 BD
					39 00 00 40 00 00 02 BD 00
					39 00 00 40 00 00 02 B9 19
					39 00 00 40 00 00 04 B0 00 08 B9
					39 00 00 40 00 00 07 B9 02 00 02 02 00 02
					39 00 00 40 00 00 04 B0 00 06 B9
					39 00 00 40 00 00 02 B9 00
					39 00 00 40 00 00 04 B0 00 91 B9
					39 00 00 40 00 00 02 B9 00
					39 00 00 40 00 00 02 BD 01
					39 00 00 40 00 00 02 83 04
					39 00 00 40 00 00 02 F7 2F
					39 00 00 40 00 00 03 F0 A5 A5
					39 00 00 00 00 00 03 9F A5 A5
				];
				qcom,mdss-dsi-nolp-command-update = <0x51 11 2>;
				qcom,mdss-dsi-nolp-command-state = "dsi_hs_mode";
				qcom,mdss-dsi-timing-switch-command = [
					39 00 00 40 00 00 03 9F A5 A5
					39 00 00 40 00 00 03 F0 5A 5A
					39 00 00 40 00 00 04 B0 00 03 BD
					39 00 00 40 00 00 02 BD 66
					39 00 00 40 00 00 04 B0 00 08 BD
					39 00 00 40 00 00 02 BD 00
					39 00 00 40 00 00 02 B9 19
					39 00 00 40 00 00 04 B0 00 08 B9
					39 00 00 40 00 00 07 B9 02 00 02 02 00 02
					39 00 00 40 00 00 04 B0 00 06 B9
					39 00 00 40 00 00 02 B9 00
					39 00 00 40 00 00 04 B0 00 91 B9
					39 00 00 40 00 00 02 B9 00
					39 00 00 40 00 00 02 BD 01
					39 00 00 40 00 00 02 83 04
					39 00 00 40 00 00 02 F7 2F
					39 00 00 40 00 00 03 F0 A5 A5
					39 00 00 00 00 00 03 9F A5 A5
				];
				qcom,mdss-dsi-timing-switch-command-state = "dsi_hs_mode";
				qcom,mdss-dsi-on-command = [
					//DSC setting V1.1
					39 00 00 40 00 00 03 9F A5 A5
					39 00 00 40 00 00 59 9E 11 00 00 AB 30 80 0C 80 05 A0 00 19 02 D0 02 D0
											02 00 02 68 00 20 02 BE 00 0A 00 0C 04 00 03 0D 18 00 10 F0 07 10 20 00
 											06 0F 0F 33 0E 1C 2A 38 46 54 62 69 70 77 79 7B 7D 7E 01 02 22 00 2A 40
											2A BE 3A FC 3A FA 3A F8 3B 38 3B 78 3B B6 4B F6 4C 34 4C 74 5C 74 8C F4
					39 00 00 40 00 00 02 9D 01
					39 00 00 00 00 00 03 9F 5A 5A
					//AD Improve Setting
					39 00 00 40 00 00 03 F0 5A 5A
					39 00 00 40 00 00 03 F1 5A 5A
					15 00 00 40 00 00 02 D0 08
					39 00 00 40 00 00 04 B0 00 60 B7
					15 00 00 40 00 00 02 B7 45
					39 00 00 40 00 00 04 B0 00 6A B7
					15 00 00 40 00 00 02 B7 15
					39 00 00 40 00 00 04 B0 00 6D B7
					15 00 00 40 00 00 02 B7 45
					39 00 00 40 00 00 04 B0 00 77 B7
					15 00 00 40 00 00 02 B7 15
					39 00 00 00 00 00 0E F4 F3 E0 E1 D3 B3 D3 A3 D3 D3 B3 D3 A3 D3
					/* Sleep Out */
					05 00 00 00 78 00 01 11
					//TE ON
					39 00 00 40 00 00 03 9F A5 A5
					39 00 00 40 00 00 02 35 00
					39 00 00 00 00 00 03 9F 5A 5A
					//FIXED TE OFF
					39 00 00 40 00 00 03 F0 5A 5A
					39 00 00 40 00 00 02 B9 00
					39 00 00 40 00 00 04 B0 00 08 B9
					39 00 00 40 00 00 07 B9 00 00 00 00 00 00
					39 00 00 40 00 00 02 F7 0F
					39 00 00 00 00 00 03 F0 A5 A5
					//PAGE ADDRESS SET
					39 00 00 40 00 00 05 2A 00 00 05 9F
					39 00 00 40 00 00 05 2B 00 00 0C 7F
					//Scaler Setting
					39 00 00 40 00 00 03 F0 5A 5A
					39 00 00 40 00 00 02 C3 02
					39 00 00 40 00 00 05 2A 00 00 05 9F
					39 00 00 40 00 00 05 2B 00 00 0C 7F
					39 00 00 40 00 00 03 F0 A5 A5
					//Frequency Change Setting
					39 00 00 40 00 00 03 9F A5 A5
					39 00 00 40 00 00 03 F0 5A 5A
					39 00 00 40 00 00 02 83 00
					39 00 00 40 00 00 02 F7 2F
					39 00 00 40 00 00 03 F0 A5 A5
					39 00 00 00 00 00 03 9F 5A 5A
					//Error Flag Control
					39 00 00 40 00 00 03 F0 5A 5A
					39 00 00 40 00 00 02 E5 15
					39 00 00 40 00 00 04 B0 00 18 ED
					39 00 00 40 00 00 02 ED 1C
					39 00 00 40 00 00 04 B0 00 43 F4
					39 00 00 40 00 00 02 F4 30
					39 00 00 40 00 00 04 B0 00 01 ED
					39 00 00 40 00 00 03 ED 01 40
					39 00 00 00 00 00 03 F0 A5 A5
					//ACL Mode
					39 00 00 40 00 00 03 F0 5A 5A
					39 00 00 40 00 00 02 55 00
					39 00 00 00 00 00 03 F0 A5 A5
					//OD OFF
					39 00 00 40 00 00 03 F0 5A 5A
					39 00 00 40 00 00 04 B0 00 8B 68
					15 00 00 40 00 00 02 68 01
					15 00 00 40 00 00 02 F7 2F
					39 00 00 00 00 00 03 F0 A5 A5
					//Low Frequency Change(Manual Mode)
					39 00 00 40 00 00 03 9F A5 A5
					39 00 00 40 00 00 03 F0 5A 5A
					39 00 00 40 00 00 04 B0 00 03 BD
					39 00 00 40 00 00 02 BD 66
					39 00 00 40 00 00 04 B0 00 08 BD
					39 00 00 40 00 00 02 BD 00
					39 00 00 40 00 00 02 B9 19
					39 00 00 40 00 00 04 B0 00 08 B9
					39 00 00 40 00 00 07 B9 02 00 02 02 00 02
					39 00 00 40 00 00 04 B0 00 06 B9
					39 00 00 40 00 00 02 B9 00
					39 00 00 40 00 00 04 B0 00 91 B9
					39 00 00 40 00 00 02 B9 00
					39 00 00 40 00 00 02 BD 01
					39 00 00 40 00 00 02 83 04
					39 00 00 40 00 00 02 F7 2F
					39 00 00 40 00 00 03 F0 A5 A5
					39 00 00 00 00 00 03 9F A5 A5
					//Dimming speed
					39 00 00 40 00 00 03 F0 5A 5A
					39 00 00 40 00 00 04 B0 00 20 67
					39 00 00 40 00 00 02 67 06
					39 00 00 40 00 00 02 F7 2F
					39 00 00 00 00 00 03 F0 A5 A5
					/* AOD ON */
					39 00 00 40 00 00 03 9F A5 A5
					39 00 00 40 00 00 03 F0 5A 5A
					15 00 00 40 00 00 02 53 24
					15 00 00 40 00 00 02 83 18
					39 00 00 40 00 00 02 F7 2F
					39 00 00 40 00 00 03 F0 A5 A5
					39 00 00 00 0B 00 03 9F 5A 5A
					/* AOD OFF */
					39 00 00 40 00 00 03 9F A5 A5
					39 00 00 40 00 00 03 F0 5A 5A
					15 00 00 40 00 00 02 53 20
					15 00 00 40 00 00 02 83 00
					39 00 00 40 00 00 02 F7 2F
					39 00 00 40 00 00 03 F0 A5 A5
					39 00 00 00 00 00 03 9F 5A 5A
					//Low Frequency Change(Manual Mode)
					39 00 00 40 00 00 03 9F A5 A5
					39 00 00 40 00 00 03 F0 5A 5A
					39 00 00 40 00 00 04 B0 00 03 BD
					39 00 00 40 00 00 02 BD 66
					39 00 00 40 00 00 04 B0 00 08 BD
					39 00 00 40 00 00 02 BD 00
					39 00 00 40 00 00 02 B9 19
					39 00 00 40 00 00 04 B0 00 08 B9
					39 00 00 40 00 00 07 B9 02 00 02 02 00 02
					39 00 00 40 00 00 04 B0 00 06 B9
					39 00 00 40 00 00 02 B9 00
					39 00 00 40 00 00 04 B0 00 91 B9
					39 00 00 40 00 00 02 B9 00
					39 00 00 40 00 00 02 BD 01
					39 00 00 40 00 00 02 83 04
					39 00 00 40 00 00 02 F7 2F
					39 00 00 40 00 00 03 F0 A5 A5
					39 00 00 00 00 00 03 9F A5 A5
					//Brightness Control
					39 00 00 40 00 00 02 53 20
					39 00 00 00 00 00 03 51 00 00
					//PWM&DC switch
					39 00 00 40 00 00 03 F0 5A 5A
					39 00 00 40 00 00 04 B0 02 17 6B
					39 00 00 40 00 00 61 6B 00 10 18 20 28 30 38 40 48 50 58 60
							  	68 70 78 80 88 90 98 A0 A8 B0 B8 C0 C8 D0 D8 E0 E8 F0 F8 FF 00
							  	10 18 20 28 30 38 40 48 50 58 60 68 70 78 80 88 90 98 A0 A8 B0
							  	B8 C0 C8 D0 D8 E0 E8 F0 F8 FF 00 10 18 20 28 30 38 40 48 50 58
							  	60 68 70 78 80 88 90 98 A0 A8 B0 B8 C0 C8 D0 D8 E0 E8 F0 F8 FF
					39 00 00 40 00 00 04 B0 00 1E 67
					15 00 00 40 00 00 02 67 11
					15 00 00 40 00 00 02 F7 2F
					39 00 00 00 00 00 03 F0 A5 A5
					/* Display On */
					39 00 00 40 00 00 03 9F A5 A5
					05 00 00 40 00 00 01 29
					39 00 00 00 00 00 03 9F 5A 5A
				];
				qcom,mdss-dsi-on-command-state = "dsi_lp_mode";
			};
			timing@wqhd_idle_10hz_index_06 {
				#include "dsi-panel-o1-38-0c-0b-dsc-cmd-common.dtsi"
				cell-index = <6>;
				qcom,mdss-dsi-panel-framerate = <120>;
				/* ---------------------------- */
				/* | 15 - 14 | 13 - 7 | 6 - 0 | */
				/* ---------------------------- */
				/* |   mode  | sf fps | min fps| */
				/* ---------------------------- -*/
				/* mode: 1 idle, 2 auto, 3 qsync */
				/*   1 << 14 | 120 << 7 | 10     */
				qcom,mdss-dsi-h-sync-skew = <31754>;
				/* mode: 0 normal, 1 idle, 2 auto, 3 qsync, 4 diff, 5 test */
				mi,mdss-dsi-ddic-mode = "idle";
				mi,mdss-dsi-sf-framerate = <120>;
				mi,mdss-dsi-ddic-min-framerate = <10>;
				mi,mdss-dsi-doze-hbm-command = [
					//120HZ
					39 00 00 40 00 00 03 9F A5 A5
					39 00 00 40 00 00 03 F0 5A 5A
					39 00 00 40 00 00 04 B0 00 03 BD
					39 00 00 40 00 00 02 BD 66
					39 00 00 40 00 00 04 B0 00 08 BD
					39 00 00 40 00 00 02 BD 00
					39 00 00 40 00 00 02 B9 19
					39 00 00 40 00 00 04 B0 00 08 B9
					39 00 00 40 00 00 07 B9 02 00 02 02 00 02
					39 00 00 40 00 00 04 B0 00 06 B9
					39 00 00 40 00 00 02 B9 00
					39 00 00 40 00 00 04 B0 00 91 B9
					39 00 00 40 00 00 02 B9 00
					39 00 00 40 00 00 02 BD 01
					39 00 00 40 00 00 02 83 00
					39 00 00 40 00 00 02 F7 2F
					39 00 00 40 00 00 03 F0 A5 A5
					39 00 00 00 09 00 03 9F 5A 5A
					//1HZ AOD
					39 00 00 40 00 00 03 9F A5 A5
					39 00 00 40 00 00 03 F0 5A 5A
					39 00 00 40 00 00 04 B0 00 03 BD
					39 00 00 40 00 00 02 BD 64
					39 00 00 40 00 00 02 53 24
					39 00 00 40 00 00 02 83 1B
					39 00 00 40 00 00 03 51 01 9C
					39 00 00 40 00 00 02 B9 C1
					39 00 00 40 00 00 04 B0 00 08 B9
					39 00 00 40 00 00 07 B9 32 00 02 32 00 02
					39 00 00 40 00 00 04 B0 00 06 B9
					39 00 00 40 00 00 02 B9 03
					39 00 00 40 00 00 02 F7 2F
					39 00 00 40 00 00 03 F0 A5 A5
					39 00 00 00 00 00 03 9F 5A 5A
				];
				mi,mdss-dsi-doze-hbm-command-state = "dsi_hs_mode";

				mi,mdss-dsi-doze-lbm-command = [
					//120HZ
					39 00 00 40 00 00 03 9F A5 A5
					39 00 00 40 00 00 03 F0 5A 5A
					39 00 00 40 00 00 04 B0 00 03 BD
					39 00 00 40 00 00 02 BD 66
					39 00 00 40 00 00 04 B0 00 08 BD
					39 00 00 40 00 00 02 BD 00
					39 00 00 40 00 00 02 B9 19
					39 00 00 40 00 00 04 B0 00 08 B9
					39 00 00 40 00 00 07 B9 02 00 02 02 00 02
					39 00 00 40 00 00 04 B0 00 06 B9
					39 00 00 40 00 00 02 B9 00
					39 00 00 40 00 00 04 B0 00 91 B9
					39 00 00 40 00 00 02 B9 00
					39 00 00 40 00 00 02 BD 01
					39 00 00 40 00 00 02 83 00
					39 00 00 40 00 00 02 F7 2F
					39 00 00 40 00 00 03 F0 A5 A5
					39 00 00 00 09 00 03 9F 5A 5A
					//1HZ AOD
					39 00 00 40 00 00 03 9F A5 A5
					39 00 00 40 00 00 03 F0 5A 5A
					39 00 00 40 00 00 04 B0 00 03 BD
					39 00 00 40 00 00 02 BD 64
					39 00 00 40 00 00 02 53 24
					39 00 00 40 00 00 02 83 1B
					39 00 00 40 00 00 03 51 00 23
					39 00 00 40 00 00 02 B9 C1
					39 00 00 40 00 00 04 B0 00 08 B9
					39 00 00 40 00 00 07 B9 32 00 02 32 00 02
					39 00 00 40 00 00 04 B0 00 06 B9
					39 00 00 40 00 00 02 B9 03
					39 00 00 40 00 00 02 F7 2F
					39 00 00 40 00 00 03 F0 A5 A5
					39 00 00 00 00 00 03 9F 5A 5A
				];
				mi,mdss-dsi-doze-lbm-command-state = "dsi_hs_mode";

				mi,mdss-dsi-dc-demura-switch-command = [
					39 00 00 60 00 00 03 F0 5A 5A
					39 00 00 60 00 00 04 B0 00 79 62
					15 00 00 60 00 00 02 62 01
					15 00 00 20 00 00 02 F7 2F
					39 00 00 60 00 00 04 B0 01 56 6B
					39 00 00 60 00 00 C2 6B 01 FF FF FF FF FF FF FF
								FF FF FF FF FF FF BF FF BF FF B3 FF
								A6 FF 99 FF 7F FF 73 FF 59 FF 4C FF
								33 FF 33 FF 33 FF 33 FF 33 FF 33 FF
								33 FF 33 FF 33 FF 33 FF 33 FF 33 FF
								33 FF 33 FF 33 FF 33 FF 0C FF FF FF
								FF FF FF FF FF FF FF FF FF FF BF FF
								BF FF B3 FF A6 FF 99 FF 7F FF 73 FF
								59 FF 4C FF 33 FF 33 FF 33 FF 33 FF
								33 FF 33 FF 33 FF 33 FF 33 FF 33 FF
								33 FF 33 FF 33 FF 33 FF 33 FF 33 FF
								0C FF FF FF FF FF FF FF FF FF FF FF
								FF FF BF FF BF FF B3 FF A6 FF 99 FF
								7F FF 73 FF 59 FF 4C FF 33 FF 33 FF
								33 FF 33 FF 33 FF 33 FF 33 FF 33 FF
								33 FF 33 FF 33 FF 33 FF 33 FF 33 FF
								33 FF 33 FF 0C
					39 00 00 60 00 00 03 51 01 9C
					15 00 00 20 00 00 02 F7 2F
					39 00 00 60 00 00 04 B0 01 56 6B
					15 00 00 60 00 00 02 6B 00
					39 00 00 60 00 00 04 B0 00 79 62
					15 00 00 60 00 00 02 62 00
					15 00 00 60 00 00 02 F7 2F
					39 00 00 20 00 00 03 F0 A5 A5
				];
				mi,mdss-dsi-dc-demura-switch-command-state = "dsi_hs_mode";

				mi,mdss-dsi-pwm-demura-switch-command = [
					39 00 00 60 00 00 03 F0 5A 5A
					39 00 00 60 00 00 04 B0 00 79 62
					15 00 00 60 00 00 02 62 01
					15 00 00 20 00 00 02 F7 2F
					39 00 00 60 00 00 04 B0 01 56 6B
					39 00 00 60 00 00 C2 6B 01 00 00 00 00 00 00 00
								00 00 00 00 00 00 00 00 00 00 00 00
								00 00 00 00 00 00 00 00 00 00 00 00
								00 00 00 00 00 00 66 00 66 00 66 00
								66 00 66 00 66 00 66 00 66 00 66 00
								66 00 66 00 66 00 66 00 80 00 00 00
								00 00 00 00 00 00 00 00 00 00 00 00
								00 00 00 00 00 00 00 00 00 00 00 00
								00 00 00 00 00 00 00 00 00 00 66 00
								66 00 66 00 66 00 66 00 66 00 66 00
								66 00 66 00 66 00 66 00 66 00 66 00
								80 00 00 00 00 00 00 00 00 00 00 00
								00 00 00 00 00 00 00 00 00 00 00 00
								00 00 00 00 00 00 00 00 00 00 00 00
								00 00 66 00 66 00 66 00 66 00 66 00
								66 00 66 00 66 00 66 00 66 00 66 00
								66 00 66 00 80
					39 00 00 60 00 00 03 51 01 9B
					15 00 00 20 00 00 02 F7 2F
					39 00 00 60 00 00 04 B0 01 56 6B
					15 00 00 60 00 00 02 6B 00
					39 00 00 60 00 00 04 B0 00 79 62
					15 00 00 60 00 00 02 62 00
					15 00 00 60 00 00 02 F7 2F
					39 00 00 20 00 00 03 F0 A5 A5
				];
				mi,mdss-dsi-pwm-demura-switch-command-state = "dsi_hs_mode";

				qcom,mdss-dsi-nolp-command = [
					39 00 00 40 00 00 03 9F A5 A5
					39 00 00 40 00 00 03 F0 5A 5A
					39 00 00 40 00 00 04 B0 00 03 BD
					39 00 00 40 00 00 02 BD 66
					39 00 00 40 00 00 02 B9 19
					39 00 00 40 00 00 04 B0 00 08 B9
					39 00 00 40 00 00 07 B9 02 00 02 02 00 02
					39 00 00 40 00 00 04 B0 00 06 B9
					39 00 00 40 00 00 02 B9 00
					39 00 00 40 00 00 02 53 20
					39 00 00 40 00 00 02 83 00
					39 00 00 40 00 00 03 51 00 23
					39 00 00 40 00 00 02 F7 2F
					39 00 00 40 00 00 03 F0 A5 A5
					39 00 00 00 00 00 03 9F 5A 5A
					//10HZ
					39 00 00 40 00 00 03 F0 5A 5A
					39 00 00 40 00 00 04 B0 00 03 BD
					39 00 00 40 00 00 02 BD 64
					39 00 00 40 00 00 04 B0 00 08 BD
					39 00 00 40 00 00 02 BD 00
					39 00 00 40 00 00 02 B9 41
					39 00 00 40 00 00 04 B0 00 08 B9
					39 00 00 40 00 00 07 B9 CA 00 02 CA 00 02
					39 00 00 40 00 00 04 B0 00 06 B9
					39 00 00 40 00 00 02 B9 00
					39 00 00 40 00 00 04 B0 00 91 B9
					39 00 00 40 00 00 02 B9 80
					39 00 00 40 00 00 04 B0 00 7B BD
					39 00 00 40 00 00 03 BD 00 0B
					39 00 00 40 00 00 04 B0 00 2C BD
					39 00 00 40 00 00 02 BD 10
					39 00 00 40 00 00 04 B0 00 7D BD
					39 00 00 40 00 00 09 BD 00 00 00 01 00 03 00 0B
					39 00 00 40 00 00 04 B0 00 8D BD
					39 00 00 40 00 00 05 BD 01 02 03 09
					39 00 00 40 00 00 02 BD 05
					39 00 00 40 00 00 02 F7 2F
					39 00 00 00 00 00 03 F0 A5 A5
				];
				qcom,mdss-dsi-nolp-command-update = <0x51 11 2>;
				qcom,mdss-dsi-nolp-command-state = "dsi_hs_mode";
				qcom,mdss-dsi-timing-switch-command = [
					39 00 00 40 00 00 03 F0 5A 5A
					39 00 00 40 00 00 04 B0 00 03 BD
					39 00 00 40 00 00 02 BD 64
					39 00 00 40 00 00 04 B0 00 08 BD
					39 00 00 40 00 00 02 BD 00
					39 00 00 40 00 00 02 B9 41
					39 00 00 40 00 00 04 B0 00 08 B9
					39 00 00 40 00 00 07 B9 CA 00 02 CA 00 02
					39 00 00 40 00 00 04 B0 00 06 B9
					39 00 00 40 00 00 02 B9 00
					39 00 00 40 00 00 04 B0 00 91 B9
					39 00 00 40 00 00 02 B9 80
					39 00 00 40 00 00 04 B0 00 7B BD
					39 00 00 40 00 00 03 BD 00 0B
					39 00 00 40 00 00 04 B0 00 2C BD
					39 00 00 40 00 00 02 BD 10
					39 00 00 40 00 00 04 B0 00 7D BD
					39 00 00 40 00 00 09 BD 00 00 00 01 00 03 00 0B
					39 00 00 40 00 00 04 B0 00 8D BD
					39 00 00 40 00 00 05 BD 01 02 03 09
					39 00 00 40 00 00 02 BD 05
					39 00 00 40 00 00 02 F7 2F
					39 00 00 00 00 00 03 F0 A5 A5
				];
				qcom,mdss-dsi-timing-switch-command-state = "dsi_hs_mode";
				qcom,mdss-dsi-on-command = [
					//DSC setting V1.1
					39 00 00 40 00 00 03 9F A5 A5
					39 00 00 40 00 00 59 9E 11 00 00 AB 30 80 0C 80 05 A0 00 19 02 D0 02 D0
											02 00 02 68 00 20 02 BE 00 0A 00 0C 04 00 03 0D 18 00 10 F0 07 10 20 00
 											06 0F 0F 33 0E 1C 2A 38 46 54 62 69 70 77 79 7B 7D 7E 01 02 22 00 2A 40
											2A BE 3A FC 3A FA 3A F8 3B 38 3B 78 3B B6 4B F6 4C 34 4C 74 5C 74 8C F4
					39 00 00 40 00 00 02 9D 01
					39 00 00 00 00 00 03 9F 5A 5A
					//AD Improve Setting
					39 00 00 40 00 00 03 F0 5A 5A
					39 00 00 40 00 00 03 F1 5A 5A
					15 00 00 40 00 00 02 D0 08
					39 00 00 40 00 00 04 B0 00 60 B7
					15 00 00 40 00 00 02 B7 45
					39 00 00 40 00 00 04 B0 00 6A B7
					15 00 00 40 00 00 02 B7 15
					39 00 00 40 00 00 04 B0 00 6D B7
					15 00 00 40 00 00 02 B7 45
					39 00 00 40 00 00 04 B0 00 77 B7
					15 00 00 40 00 00 02 B7 15
					39 00 00 00 00 00 0E F4 F3 E0 E1 D3 B3 D3 A3 D3 D3 B3 D3 A3 D3
					/* Sleep Out */
					05 00 00 00 78 00 01 11
					//TE ON
					39 00 00 40 00 00 03 9F A5 A5
					39 00 00 40 00 00 02 35 00
					39 00 00 00 00 00 03 9F 5A 5A
					//FIXED TE OFF
					39 00 00 40 00 00 03 F0 5A 5A
					39 00 00 40 00 00 02 B9 00
					39 00 00 40 00 00 04 B0 00 08 B9
					39 00 00 40 00 00 07 B9 00 00 00 00 00 00
					39 00 00 40 00 00 02 F7 0F
					39 00 00 00 00 00 03 F0 A5 A5
					//PAGE ADDRESS SET
					39 00 00 40 00 00 05 2A 00 00 05 9F
					39 00 00 40 00 00 05 2B 00 00 0C 7F
					//Scaler Setting
					39 00 00 40 00 00 03 F0 5A 5A
					39 00 00 40 00 00 02 C3 02
					39 00 00 40 00 00 05 2A 00 00 05 9F
					39 00 00 40 00 00 05 2B 00 00 0C 7F
					39 00 00 40 00 00 03 F0 A5 A5
					//Frequency Change Setting
					39 00 00 40 00 00 03 9F A5 A5
					39 00 00 40 00 00 03 F0 5A 5A
					39 00 00 40 00 00 02 83 00
					39 00 00 40 00 00 02 F7 2F
					39 00 00 40 00 00 03 F0 A5 A5
					39 00 00 00 00 00 03 9F 5A 5A
					//Error Flag Control
					39 00 00 40 00 00 03 F0 5A 5A
					39 00 00 40 00 00 02 E5 15
					39 00 00 40 00 00 04 B0 00 18 ED
					39 00 00 40 00 00 02 ED 1C
					39 00 00 40 00 00 04 B0 00 43 F4
					39 00 00 40 00 00 02 F4 30
					39 00 00 40 00 00 04 B0 00 01 ED
					39 00 00 40 00 00 03 ED 01 40
					39 00 00 00 00 00 03 F0 A5 A5
					//ACL Mode
					39 00 00 40 00 00 03 F0 5A 5A
					39 00 00 40 00 00 02 55 00
					39 00 00 00 00 00 03 F0 A5 A5
					//OD OFF
					39 00 00 40 00 00 03 F0 5A 5A
					39 00 00 40 00 00 04 B0 00 8B 68
					15 00 00 40 00 00 02 68 01
					15 00 00 40 00 00 02 F7 2F
					39 00 00 00 00 00 03 F0 A5 A5
					//Low Frequency Change(AUTO Mode)
					39 00 00 40 00 00 03 F0 5A 5A
					39 00 00 40 00 00 04 B0 00 03 BD
					39 00 00 40 00 00 02 BD 64
					39 00 00 40 00 00 04 B0 00 08 BD
					39 00 00 40 00 00 02 BD 00
					39 00 00 40 00 00 02 B9 41
					39 00 00 40 00 00 04 B0 00 08 B9
					39 00 00 40 00 00 07 B9 CA 00 02 CA 00 02
					39 00 00 40 00 00 04 B0 00 06 B9
					39 00 00 40 00 00 02 B9 00
					39 00 00 40 00 00 04 B0 00 91 B9
					39 00 00 40 00 00 02 B9 80
					39 00 00 40 00 00 04 B0 00 7B BD
					39 00 00 40 00 00 03 BD 00 0B
					39 00 00 40 00 00 04 B0 00 2C BD
					39 00 00 40 00 00 02 BD 10
					39 00 00 40 00 00 04 B0 00 7D BD
					39 00 00 40 00 00 09 BD 00 00 00 01 00 03 00 0B
					39 00 00 40 00 00 04 B0 00 8D BD
					39 00 00 40 00 00 05 BD 01 02 03 09
					39 00 00 40 00 00 02 BD 05
					39 00 00 40 00 00 02 F7 2F
					39 00 00 00 00 00 03 F0 A5 A5
					//Dimming speed
					39 00 00 40 00 00 03 F0 5A 5A
					39 00 00 40 00 00 04 B0 00 20 67
					39 00 00 40 00 00 02 67 06
					39 00 00 40 00 00 02 F7 2F
					39 00 00 00 00 00 03 F0 A5 A5
					/* AOD ON */
					39 00 00 40 00 00 03 9F A5 A5
					39 00 00 40 00 00 03 F0 5A 5A
					15 00 00 40 00 00 02 53 24
					15 00 00 40 00 00 02 83 18
					39 00 00 40 00 00 02 F7 2F
					39 00 00 40 00 00 03 F0 A5 A5
					39 00 00 00 0B 00 03 9F 5A 5A
					/* AOD OFF */
					39 00 00 40 00 00 03 9F A5 A5
					39 00 00 40 00 00 03 F0 5A 5A
					15 00 00 40 00 00 02 53 20
					15 00 00 40 00 00 02 83 00
					39 00 00 40 00 00 02 F7 2F
					39 00 00 40 00 00 03 F0 A5 A5
					39 00 00 00 00 00 03 9F 5A 5A
					//Low Frequency Change(AUTO Mode)
					39 00 00 40 00 00 03 F0 5A 5A
					39 00 00 40 00 00 04 B0 00 03 BD
					39 00 00 40 00 00 02 BD 64
					39 00 00 40 00 00 04 B0 00 08 BD
					39 00 00 40 00 00 02 BD 00
					39 00 00 40 00 00 02 B9 41
					39 00 00 40 00 00 04 B0 00 08 B9
					39 00 00 40 00 00 07 B9 CA 00 02 CA 00 02
					39 00 00 40 00 00 04 B0 00 06 B9
					39 00 00 40 00 00 02 B9 00
					39 00 00 40 00 00 04 B0 00 91 B9
					39 00 00 40 00 00 02 B9 80
					39 00 00 40 00 00 04 B0 00 7B BD
					39 00 00 40 00 00 03 BD 00 0B
					39 00 00 40 00 00 04 B0 00 2C BD
					39 00 00 40 00 00 02 BD 10
					39 00 00 40 00 00 04 B0 00 7D BD
					39 00 00 40 00 00 09 BD 00 00 00 01 00 03 00 0B
					39 00 00 40 00 00 04 B0 00 8D BD
					39 00 00 40 00 00 05 BD 01 02 03 09
					39 00 00 40 00 00 02 BD 05
					39 00 00 40 00 00 02 F7 2F
					39 00 00 00 00 00 03 F0 A5 A5
					//Brightness Control
					39 00 00 40 00 00 02 53 20
					39 00 00 00 00 00 03 51 00 00
					//PWM&DC switch
					39 00 00 40 00 00 03 F0 5A 5A
					39 00 00 40 00 00 04 B0 02 17 6B
					39 00 00 40 00 00 61 6B 00 10 18 20 28 30 38 40 48 50 58 60
							  	68 70 78 80 88 90 98 A0 A8 B0 B8 C0 C8 D0 D8 E0 E8 F0 F8 FF 00
							  	10 18 20 28 30 38 40 48 50 58 60 68 70 78 80 88 90 98 A0 A8 B0
							  	B8 C0 C8 D0 D8 E0 E8 F0 F8 FF 00 10 18 20 28 30 38 40 48 50 58
							  	60 68 70 78 80 88 90 98 A0 A8 B0 B8 C0 C8 D0 D8 E0 E8 F0 F8 FF
					39 00 00 40 00 00 04 B0 00 1E 67
					15 00 00 40 00 00 02 67 11
					15 00 00 40 00 00 02 F7 2F
					39 00 00 00 00 00 03 F0 A5 A5
					/* Display On */
					39 00 00 40 00 00 03 9F A5 A5
					05 00 00 40 00 00 01 29
					39 00 00 00 00 00 03 9F 5A 5A
				];
				qcom,mdss-dsi-on-command-state = "dsi_lp_mode";
			};
			timing@wqhd_idle_1hz_index_07 {
				#include "dsi-panel-o1-38-0c-0b-dsc-cmd-common.dtsi"
				cell-index = <7>;
				qcom,mdss-dsi-panel-framerate = <120>;
				/* ---------------------------- */
				/* | 15 - 14 | 13 - 7 | 6 - 0 | */
				/* ---------------------------- */
				/* |   mode  | sf fps | min fps| */
				/* ---------------------------- -*/
				/* mode: 1 idle, 2 auto, 3 qsync */
				/*   1 << 14 | 120 << 7 | 1     */
				qcom,mdss-dsi-h-sync-skew = <31745>;
				/* mode: 0 normal, 1 idle, 2 auto, 3 qsync, 4 diff, 5 test */
				mi,mdss-dsi-ddic-mode = "idle";
				mi,mdss-dsi-sf-framerate = <120>;
				mi,mdss-dsi-ddic-min-framerate = <1>;
				mi,mdss-dsi-doze-hbm-command = [
					//120HZ
					39 00 00 40 00 00 03 9F A5 A5
					39 00 00 40 00 00 03 F0 5A 5A
					39 00 00 40 00 00 04 B0 00 03 BD
					39 00 00 40 00 00 02 BD 66
					39 00 00 40 00 00 04 B0 00 08 BD
					39 00 00 40 00 00 02 BD 00
					39 00 00 40 00 00 02 B9 19
					39 00 00 40 00 00 04 B0 00 08 B9
					39 00 00 40 00 00 07 B9 02 00 02 02 00 02
					39 00 00 40 00 00 04 B0 00 06 B9
					39 00 00 40 00 00 02 B9 00
					39 00 00 40 00 00 04 B0 00 91 B9
					39 00 00 40 00 00 02 B9 00
					39 00 00 40 00 00 02 BD 01
					39 00 00 40 00 00 02 83 00
					39 00 00 40 00 00 02 F7 2F
					39 00 00 40 00 00 03 F0 A5 A5
					39 00 00 00 09 00 03 9F 5A 5A
					//1HZ AOD
					39 00 00 40 00 00 03 9F A5 A5
					39 00 00 40 00 00 03 F0 5A 5A
					39 00 00 40 00 00 04 B0 00 03 BD
					39 00 00 40 00 00 02 BD 64
					39 00 00 40 00 00 02 53 24
					39 00 00 40 00 00 02 83 1B
					39 00 00 40 00 00 03 51 01 9C
					39 00 00 40 00 00 02 B9 C1
					39 00 00 40 00 00 04 B0 00 08 B9
					39 00 00 40 00 00 07 B9 32 00 02 32 00 02
					39 00 00 40 00 00 04 B0 00 06 B9
					39 00 00 40 00 00 02 B9 03
					39 00 00 40 00 00 02 F7 2F
					39 00 00 40 00 00 03 F0 A5 A5
					39 00 00 00 00 00 03 9F 5A 5A
				];
				mi,mdss-dsi-doze-hbm-command-state = "dsi_hs_mode";

				mi,mdss-dsi-doze-lbm-command = [
					//120HZ
					39 00 00 40 00 00 03 9F A5 A5
					39 00 00 40 00 00 03 F0 5A 5A
					39 00 00 40 00 00 04 B0 00 03 BD
					39 00 00 40 00 00 02 BD 66
					39 00 00 40 00 00 04 B0 00 08 BD
					39 00 00 40 00 00 02 BD 00
					39 00 00 40 00 00 02 B9 19
					39 00 00 40 00 00 04 B0 00 08 B9
					39 00 00 40 00 00 07 B9 02 00 02 02 00 02
					39 00 00 40 00 00 04 B0 00 06 B9
					39 00 00 40 00 00 02 B9 00
					39 00 00 40 00 00 04 B0 00 91 B9
					39 00 00 40 00 00 02 B9 00
					39 00 00 40 00 00 02 BD 01
					39 00 00 40 00 00 02 83 00
					39 00 00 40 00 00 02 F7 2F
					39 00 00 40 00 00 03 F0 A5 A5
					39 00 00 00 09 00 03 9F 5A 5A
					//1HZ AOD
					39 00 00 40 00 00 03 9F A5 A5
					39 00 00 40 00 00 03 F0 5A 5A
					39 00 00 40 00 00 04 B0 00 03 BD
					39 00 00 40 00 00 02 BD 64
					39 00 00 40 00 00 02 53 24
					39 00 00 40 00 00 02 83 1B
					39 00 00 40 00 00 03 51 00 23
					39 00 00 40 00 00 02 B9 C1
					39 00 00 40 00 00 04 B0 00 08 B9
					39 00 00 40 00 00 07 B9 32 00 02 32 00 02
					39 00 00 40 00 00 04 B0 00 06 B9
					39 00 00 40 00 00 02 B9 03
					39 00 00 40 00 00 02 F7 2F
					39 00 00 40 00 00 03 F0 A5 A5
					39 00 00 00 00 00 03 9F 5A 5A
				];
				mi,mdss-dsi-doze-lbm-command-state = "dsi_hs_mode";

				mi,mdss-dsi-dc-demura-switch-command = [
					39 00 00 60 00 00 03 F0 5A 5A
					39 00 00 60 00 00 04 B0 00 79 62
					15 00 00 60 00 00 02 62 01
					15 00 00 20 00 00 02 F7 2F
					39 00 00 60 00 00 04 B0 01 56 6B
					39 00 00 60 00 00 C2 6B 01 FF FF FF FF FF FF FF
								FF FF FF FF FF FF BF FF BF FF B3 FF
								A6 FF 99 FF 7F FF 73 FF 59 FF 4C FF
								33 FF 33 FF 33 FF 33 FF 33 FF 33 FF
								33 FF 33 FF 33 FF 33 FF 33 FF 33 FF
								33 FF 33 FF 33 FF 33 FF 0C FF FF FF
								FF FF FF FF FF FF FF FF FF FF BF FF
								BF FF B3 FF A6 FF 99 FF 7F FF 73 FF
								59 FF 4C FF 33 FF 33 FF 33 FF 33 FF
								33 FF 33 FF 33 FF 33 FF 33 FF 33 FF
								33 FF 33 FF 33 FF 33 FF 33 FF 33 FF
								0C FF FF FF FF FF FF FF FF FF FF FF
								FF FF BF FF BF FF B3 FF A6 FF 99 FF
								7F FF 73 FF 59 FF 4C FF 33 FF 33 FF
								33 FF 33 FF 33 FF 33 FF 33 FF 33 FF
								33 FF 33 FF 33 FF 33 FF 33 FF 33 FF
								33 FF 33 FF 0C
					39 00 00 60 00 00 03 51 01 9C
					15 00 00 20 00 00 02 F7 2F
					39 00 00 60 00 00 04 B0 01 56 6B
					15 00 00 60 00 00 02 6B 00
					39 00 00 60 00 00 04 B0 00 79 62
					15 00 00 60 00 00 02 62 00
					15 00 00 60 00 00 02 F7 2F
					39 00 00 20 00 00 03 F0 A5 A5
				];
				mi,mdss-dsi-dc-demura-switch-command-state = "dsi_hs_mode";

				mi,mdss-dsi-pwm-demura-switch-command = [
					39 00 00 60 00 00 03 F0 5A 5A
					39 00 00 60 00 00 04 B0 00 79 62
					15 00 00 60 00 00 02 62 01
					15 00 00 20 00 00 02 F7 2F
					39 00 00 60 00 00 04 B0 01 56 6B
					39 00 00 60 00 00 C2 6B 01 00 00 00 00 00 00 00
								00 00 00 00 00 00 00 00 00 00 00 00
								00 00 00 00 00 00 00 00 00 00 00 00
								00 00 00 00 00 00 66 00 66 00 66 00
								66 00 66 00 66 00 66 00 66 00 66 00
								66 00 66 00 66 00 66 00 80 00 00 00
								00 00 00 00 00 00 00 00 00 00 00 00
								00 00 00 00 00 00 00 00 00 00 00 00
								00 00 00 00 00 00 00 00 00 00 66 00
								66 00 66 00 66 00 66 00 66 00 66 00
								66 00 66 00 66 00 66 00 66 00 66 00
								80 00 00 00 00 00 00 00 00 00 00 00
								00 00 00 00 00 00 00 00 00 00 00 00
								00 00 00 00 00 00 00 00 00 00 00 00
								00 00 66 00 66 00 66 00 66 00 66 00
								66 00 66 00 66 00 66 00 66 00 66 00
								66 00 66 00 80
					39 00 00 60 00 00 03 51 01 9B
					15 00 00 20 00 00 02 F7 2F
					39 00 00 60 00 00 04 B0 01 56 6B
					15 00 00 60 00 00 02 6B 00
					39 00 00 60 00 00 04 B0 00 79 62
					15 00 00 60 00 00 02 62 00
					15 00 00 60 00 00 02 F7 2F
					39 00 00 20 00 00 03 F0 A5 A5
				];
				mi,mdss-dsi-pwm-demura-switch-command-state = "dsi_hs_mode";

				qcom,mdss-dsi-nolp-command = [
					39 00 00 40 00 00 03 9F A5 A5
					39 00 00 40 00 00 03 F0 5A 5A
					39 00 00 40 00 00 04 B0 00 03 BD
					39 00 00 40 00 00 02 BD 66
					39 00 00 40 00 00 02 B9 19
					39 00 00 40 00 00 04 B0 00 08 B9
					39 00 00 40 00 00 07 B9 02 00 02 02 00 02
					39 00 00 40 00 00 04 B0 00 06 B9
					39 00 00 40 00 00 02 B9 00
					39 00 00 40 00 00 02 53 20
					39 00 00 40 00 00 02 83 00
					39 00 00 40 00 00 03 51 00 23
					39 00 00 40 00 00 02 F7 2F
					39 00 00 40 00 00 03 F0 A5 A5
					39 00 00 00 00 00 03 9F 5A 5A
					//1HZ
					39 00 00 40 00 00 03 F0 5A 5A
					39 00 00 40 00 00 04 B0 00 03 BD
					39 00 00 40 00 00 02 BD 64
					39 00 00 40 00 00 04 B0 00 08 BD
					39 00 00 40 00 00 02 BD 00
					39 00 00 40 00 00 02 B9 41
					39 00 00 40 00 00 04 B0 00 08 B9
					39 00 00 40 00 00 07 B9 CA 00 02 CA 00 02
					39 00 00 40 00 00 04 B0 00 06 B9
					39 00 00 40 00 00 02 B9 00
					39 00 00 40 00 00 04 B0 00 91 B9
					39 00 00 40 00 00 02 B9 80
					39 00 00 40 00 00 04 B0 00 7B BD
					39 00 00 40 00 00 03 BD 00 77
					39 00 00 40 00 00 04 B0 00 2C BD
					39 00 00 40 00 00 02 BD 10
					39 00 00 40 00 00 04 B0 00 7D BD
					39 00 00 40 00 00 09 BD 00 00 00 01 00 03 00 0B
					39 00 00 40 00 00 04 B0 00 8D BD
					39 00 00 40 00 00 05 BD 01 02 03 09
					39 00 00 40 00 00 02 BD 05
					39 00 00 40 00 00 02 F7 2F
					39 00 00 00 00 00 03 F0 A5 A5
				];
				qcom,mdss-dsi-nolp-command-update = <0x51 11 2>;
				qcom,mdss-dsi-nolp-command-state = "dsi_hs_mode";
				qcom,mdss-dsi-timing-switch-command = [
					39 00 00 40 00 00 03 F0 5A 5A
					39 00 00 40 00 00 04 B0 00 03 BD
					39 00 00 40 00 00 02 BD 64
					39 00 00 40 00 00 04 B0 00 08 BD
					39 00 00 40 00 00 02 BD 00
					39 00 00 40 00 00 02 B9 41
					39 00 00 40 00 00 04 B0 00 08 B9
					39 00 00 40 00 00 07 B9 CA 00 02 CA 00 02
					39 00 00 40 00 00 04 B0 00 06 B9
					39 00 00 40 00 00 02 B9 00
					39 00 00 40 00 00 04 B0 00 91 B9
					39 00 00 40 00 00 02 B9 80
					39 00 00 40 00 00 04 B0 00 7B BD
					39 00 00 40 00 00 03 BD 00 77
					39 00 00 40 00 00 04 B0 00 2C BD
					39 00 00 40 00 00 02 BD 10
					39 00 00 40 00 00 04 B0 00 7D BD
					39 00 00 40 00 00 09 BD 00 00 00 01 00 03 00 0B
					39 00 00 40 00 00 04 B0 00 8D BD
					39 00 00 40 00 00 05 BD 01 02 03 09
					39 00 00 40 00 00 02 BD 05
					39 00 00 40 00 00 02 F7 2F
					39 00 00 00 00 00 03 F0 A5 A5
				];
				qcom,mdss-dsi-timing-switch-command-state = "dsi_hs_mode";
				qcom,mdss-dsi-on-command = [
					//DSC setting V1.1
					39 00 00 40 00 00 03 9F A5 A5
					39 00 00 40 00 00 59 9E 11 00 00 AB 30 80 0C 80 05 A0 00 19 02 D0 02 D0
											02 00 02 68 00 20 02 BE 00 0A 00 0C 04 00 03 0D 18 00 10 F0 07 10 20 00
 											06 0F 0F 33 0E 1C 2A 38 46 54 62 69 70 77 79 7B 7D 7E 01 02 22 00 2A 40
											2A BE 3A FC 3A FA 3A F8 3B 38 3B 78 3B B6 4B F6 4C 34 4C 74 5C 74 8C F4
					39 00 00 40 00 00 02 9D 01
					39 00 00 00 00 00 03 9F 5A 5A
					//AD Improve Setting
					39 00 00 40 00 00 03 F0 5A 5A
					39 00 00 40 00 00 03 F1 5A 5A
					15 00 00 40 00 00 02 D0 08
					39 00 00 40 00 00 04 B0 00 60 B7
					15 00 00 40 00 00 02 B7 45
					39 00 00 40 00 00 04 B0 00 6A B7
					15 00 00 40 00 00 02 B7 15
					39 00 00 40 00 00 04 B0 00 6D B7
					15 00 00 40 00 00 02 B7 45
					39 00 00 40 00 00 04 B0 00 77 B7
					15 00 00 40 00 00 02 B7 15
					39 00 00 00 00 00 0E F4 F3 E0 E1 D3 B3 D3 A3 D3 D3 B3 D3 A3 D3
					/* Sleep Out */
					05 00 00 00 78 00 01 11
					//TE ON
					39 00 00 40 00 00 03 9F A5 A5
					39 00 00 40 00 00 02 35 00
					39 00 00 00 00 00 03 9F 5A 5A
					//FIXED TE OFF
					39 00 00 40 00 00 03 F0 5A 5A
					39 00 00 40 00 00 02 B9 00
					39 00 00 40 00 00 04 B0 00 08 B9
					39 00 00 40 00 00 07 B9 00 00 00 00 00 00
					39 00 00 40 00 00 02 F7 0F
					39 00 00 00 00 00 03 F0 A5 A5
					//PAGE ADDRESS SET
					39 00 00 40 00 00 05 2A 00 00 05 9F
					39 00 00 40 00 00 05 2B 00 00 0C 7F
					//Scaler Setting
					39 00 00 40 00 00 03 F0 5A 5A
					39 00 00 40 00 00 02 C3 02
					39 00 00 40 00 00 05 2A 00 00 05 9F
					39 00 00 40 00 00 05 2B 00 00 0C 7F
					39 00 00 40 00 00 03 F0 A5 A5
					//Frequency Change Setting
					39 00 00 40 00 00 03 9F A5 A5
					39 00 00 40 00 00 03 F0 5A 5A
					39 00 00 40 00 00 02 83 00
					39 00 00 40 00 00 02 F7 2F
					39 00 00 40 00 00 03 F0 A5 A5
					39 00 00 00 00 00 03 9F 5A 5A
					//Error Flag Control
					39 00 00 40 00 00 03 F0 5A 5A
					39 00 00 40 00 00 02 E5 15
					39 00 00 40 00 00 04 B0 00 18 ED
					39 00 00 40 00 00 02 ED 1C
					39 00 00 40 00 00 04 B0 00 43 F4
					39 00 00 40 00 00 02 F4 30
					39 00 00 40 00 00 04 B0 00 01 ED
					39 00 00 40 00 00 03 ED 01 40
					39 00 00 00 00 00 03 F0 A5 A5
					//ACL Mode
					39 00 00 40 00 00 03 F0 5A 5A
					39 00 00 40 00 00 02 55 00
					39 00 00 00 00 00 03 F0 A5 A5
					//OD OFF
					39 00 00 40 00 00 03 F0 5A 5A
					39 00 00 40 00 00 04 B0 00 8B 68
					15 00 00 40 00 00 02 68 01
					15 00 00 40 00 00 02 F7 2F
					39 00 00 00 00 00 03 F0 A5 A5
					//Low Frequency Change(AUTO Mode)
					39 00 00 40 00 00 03 F0 5A 5A
					39 00 00 40 00 00 04 B0 00 03 BD
					39 00 00 40 00 00 02 BD 64
					39 00 00 40 00 00 04 B0 00 08 BD
					39 00 00 40 00 00 02 BD 00
					39 00 00 40 00 00 02 B9 41
					39 00 00 40 00 00 04 B0 00 08 B9
					39 00 00 40 00 00 07 B9 CA 00 02 CA 00 02
					39 00 00 40 00 00 04 B0 00 06 B9
					39 00 00 40 00 00 02 B9 00
					39 00 00 40 00 00 04 B0 00 91 B9
					39 00 00 40 00 00 02 B9 80
					39 00 00 40 00 00 04 B0 00 7B BD
					39 00 00 40 00 00 03 BD 00 77
					39 00 00 40 00 00 04 B0 00 2C BD
					39 00 00 40 00 00 02 BD 10
					39 00 00 40 00 00 04 B0 00 7D BD
					39 00 00 40 00 00 09 BD 00 00 00 01 00 03 00 0B
					39 00 00 40 00 00 04 B0 00 8D BD
					39 00 00 40 00 00 05 BD 01 02 03 09
					39 00 00 40 00 00 02 BD 05
					39 00 00 40 00 00 02 F7 2F
					39 00 00 00 00 00 03 F0 A5 A5
					//Dimming speed
					39 00 00 40 00 00 03 F0 5A 5A
					39 00 00 40 00 00 04 B0 00 20 67
					39 00 00 40 00 00 02 67 06
					39 00 00 40 00 00 02 F7 2F
					39 00 00 00 00 00 03 F0 A5 A5
					/* AOD ON */
					39 00 00 40 00 00 03 9F A5 A5
					39 00 00 40 00 00 03 F0 5A 5A
					15 00 00 40 00 00 02 53 24
					15 00 00 40 00 00 02 83 18
					39 00 00 40 00 00 02 F7 2F
					39 00 00 40 00 00 03 F0 A5 A5
					39 00 00 00 0B 00 03 9F 5A 5A
					/* AOD OFF */
					39 00 00 40 00 00 03 9F A5 A5
					39 00 00 40 00 00 03 F0 5A 5A
					15 00 00 40 00 00 02 53 20
					15 00 00 40 00 00 02 83 00
					39 00 00 40 00 00 02 F7 2F
					39 00 00 40 00 00 03 F0 A5 A5
					39 00 00 00 00 00 03 9F 5A 5A
					//Low Frequency Change(AUTO Mode)
					39 00 00 40 00 00 03 F0 5A 5A
					39 00 00 40 00 00 04 B0 00 03 BD
					39 00 00 40 00 00 02 BD 64
					39 00 00 40 00 00 04 B0 00 08 BD
					39 00 00 40 00 00 02 BD 00
					39 00 00 40 00 00 02 B9 41
					39 00 00 40 00 00 04 B0 00 08 B9
					39 00 00 40 00 00 07 B9 CA 00 02 CA 00 02
					39 00 00 40 00 00 04 B0 00 06 B9
					39 00 00 40 00 00 02 B9 00
					39 00 00 40 00 00 04 B0 00 91 B9
					39 00 00 40 00 00 02 B9 80
					39 00 00 40 00 00 04 B0 00 7B BD
					39 00 00 40 00 00 03 BD 00 77
					39 00 00 40 00 00 04 B0 00 2C BD
					39 00 00 40 00 00 02 BD 10
					39 00 00 40 00 00 04 B0 00 7D BD
					39 00 00 40 00 00 09 BD 00 00 00 01 00 03 00 0B
					39 00 00 40 00 00 04 B0 00 8D BD
					39 00 00 40 00 00 05 BD 01 02 03 09
					39 00 00 40 00 00 02 BD 05
					39 00 00 40 00 00 02 F7 2F
					39 00 00 00 00 00 03 F0 A5 A5
					//Brightness Control
					39 00 00 40 00 00 02 53 20
					39 00 00 00 00 00 03 51 00 00
					//PWM&DC switch
					39 00 00 40 00 00 03 F0 5A 5A
					39 00 00 40 00 00 04 B0 02 17 6B
					39 00 00 40 00 00 61 6B 00 10 18 20 28 30 38 40 48 50 58 60
							  	68 70 78 80 88 90 98 A0 A8 B0 B8 C0 C8 D0 D8 E0 E8 F0 F8 FF 00
							  	10 18 20 28 30 38 40 48 50 58 60 68 70 78 80 88 90 98 A0 A8 B0
							  	B8 C0 C8 D0 D8 E0 E8 F0 F8 FF 00 10 18 20 28 30 38 40 48 50 58
							  	60 68 70 78 80 88 90 98 A0 A8 B0 B8 C0 C8 D0 D8 E0 E8 F0 F8 FF
					39 00 00 40 00 00 04 B0 00 1E 67
					15 00 00 40 00 00 02 67 11
					15 00 00 40 00 00 02 F7 2F
					39 00 00 00 00 00 03 F0 A5 A5
					/* Display On */
					39 00 00 40 00 00 03 9F A5 A5
					05 00 00 40 00 00 01 29
					39 00 00 00 00 00 03 9F 5A 5A
				];
				qcom,mdss-dsi-on-command-state = "dsi_lp_mode";
			};
			timing@wqhd_auto_120_to_1hz_index_08 {
				#include "dsi-panel-o1-38-0c-0b-dsc-cmd-common.dtsi"
				cell-index = <8>;
				qcom,mdss-dsi-panel-framerate = <120>;
				/* ---------------------------- */
				/* | 15 - 14 | 13 - 7 | 6 - 0 | */
				/* ---------------------------- */
				/* |   mode  | sf fps | min fps| */
				/* ---------------------------- -*/
				/* mode: 1 idle, 2 auto, 3 qsync */
				/*   2 << 14 | 120 << 7 | 30     */
				qcom,mdss-dsi-h-sync-skew = <48158>;
				/* mode: 0 normal, 1 idle, 2 auto, 3 qsync, 4 diff, 5 test */
				mi,mdss-dsi-ddic-mode = "auto";
				mi,mdss-dsi-sf-framerate = <120>;
				mi,mdss-dsi-ddic-min-framerate = <1>;
				mi,mdss-dsi-doze-hbm-command = [
					//120HZ
					39 00 00 40 00 00 03 9F A5 A5
					39 00 00 40 00 00 03 F0 5A 5A
					39 00 00 40 00 00 04 B0 00 03 BD
					39 00 00 40 00 00 02 BD 66
					39 00 00 40 00 00 04 B0 00 08 BD
					39 00 00 40 00 00 02 BD 00
					39 00 00 40 00 00 02 B9 19
					39 00 00 40 00 00 04 B0 00 08 B9
					39 00 00 40 00 00 07 B9 02 00 02 02 00 02
					39 00 00 40 00 00 04 B0 00 06 B9
					39 00 00 40 00 00 02 B9 00
					39 00 00 40 00 00 04 B0 00 91 B9
					39 00 00 40 00 00 02 B9 00
					39 00 00 40 00 00 02 BD 01
					39 00 00 40 00 00 02 83 00
					39 00 00 40 00 00 02 F7 2F
					39 00 00 40 00 00 03 F0 A5 A5
					39 00 00 00 2A 00 03 9F 5A 5A
					//1HZ AOD
					39 00 00 40 00 00 03 9F A5 A5
					39 00 00 40 00 00 03 F0 5A 5A
					39 00 00 40 00 00 04 B0 00 03 BD
					39 00 00 40 00 00 02 BD 64
					39 00 00 40 00 00 02 53 24
					39 00 00 40 00 00 02 83 1B
					39 00 00 40 00 00 03 51 01 9C
					39 00 00 40 00 00 02 B9 C1
					39 00 00 40 00 00 04 B0 00 08 B9
					39 00 00 40 00 00 07 B9 32 00 02 32 00 02
					39 00 00 40 00 00 04 B0 00 06 B9
					39 00 00 40 00 00 02 B9 03
					39 00 00 40 00 00 02 F7 2F
					39 00 00 40 00 00 03 F0 A5 A5
					39 00 00 00 00 00 03 9F 5A 5A
				];
				mi,mdss-dsi-doze-hbm-command-state = "dsi_hs_mode";

				mi,mdss-dsi-doze-lbm-command = [
					//120HZ
					39 00 00 40 00 00 03 9F A5 A5
					39 00 00 40 00 00 03 F0 5A 5A
					39 00 00 40 00 00 04 B0 00 03 BD
					39 00 00 40 00 00 02 BD 66
					39 00 00 40 00 00 04 B0 00 08 BD
					39 00 00 40 00 00 02 BD 00
					39 00 00 40 00 00 02 B9 19
					39 00 00 40 00 00 04 B0 00 08 B9
					39 00 00 40 00 00 07 B9 02 00 02 02 00 02
					39 00 00 40 00 00 04 B0 00 06 B9
					39 00 00 40 00 00 02 B9 00
					39 00 00 40 00 00 04 B0 00 91 B9
					39 00 00 40 00 00 02 B9 00
					39 00 00 40 00 00 02 BD 01
					39 00 00 40 00 00 02 83 00
					39 00 00 40 00 00 02 F7 2F
					39 00 00 40 00 00 03 F0 A5 A5
					39 00 00 00 2A 00 03 9F 5A 5A
					//1HZ AOD
					39 00 00 40 00 00 03 9F A5 A5
					39 00 00 40 00 00 03 F0 5A 5A
					39 00 00 40 00 00 04 B0 00 03 BD
					39 00 00 40 00 00 02 BD 64
					39 00 00 40 00 00 02 53 24
					39 00 00 40 00 00 02 83 1B
					39 00 00 40 00 00 03 51 00 23
					39 00 00 40 00 00 02 B9 C1
					39 00 00 40 00 00 04 B0 00 08 B9
					39 00 00 40 00 00 07 B9 32 00 02 32 00 02
					39 00 00 40 00 00 04 B0 00 06 B9
					39 00 00 40 00 00 02 B9 03
					39 00 00 40 00 00 02 F7 2F
					39 00 00 40 00 00 03 F0 A5 A5
					39 00 00 00 00 00 03 9F 5A 5A
				];
				mi,mdss-dsi-doze-lbm-command-state = "dsi_hs_mode";

				mi,mdss-dsi-dc-demura-switch-command = [
					39 00 00 60 00 00 03 F0 5A 5A
					39 00 00 60 00 00 04 B0 00 79 62
					15 00 00 60 00 00 02 62 01
					15 00 00 20 00 00 02 F7 2F
					39 00 00 60 00 00 04 B0 01 56 6B
					39 00 00 60 00 00 C2 6B 01 FF FF FF FF FF FF FF
								FF FF FF FF FF FF BF FF BF FF B3 FF
								A6 FF 99 FF 7F FF 73 FF 59 FF 4C FF
								33 FF 33 FF 33 FF 33 FF 33 FF 33 FF
								33 FF 33 FF 33 FF 33 FF 33 FF 33 FF
								33 FF 33 FF 33 FF 33 FF 0C FF FF FF
								FF FF FF FF FF FF FF FF FF FF BF FF
								BF FF B3 FF A6 FF 99 FF 7F FF 73 FF
								59 FF 4C FF 33 FF 33 FF 33 FF 33 FF
								33 FF 33 FF 33 FF 33 FF 33 FF 33 FF
								33 FF 33 FF 33 FF 33 FF 33 FF 33 FF
								0C FF FF FF FF FF FF FF FF FF FF FF
								FF FF BF FF BF FF B3 FF A6 FF 99 FF
								7F FF 73 FF 59 FF 4C FF 33 FF 33 FF
								33 FF 33 FF 33 FF 33 FF 33 FF 33 FF
								33 FF 33 FF 33 FF 33 FF 33 FF 33 FF
								33 FF 33 FF 0C
					39 00 00 60 00 00 03 51 01 9C
					15 00 00 20 00 00 02 F7 2F
					39 00 00 60 00 00 04 B0 01 56 6B
					15 00 00 60 00 00 02 6B 00
					39 00 00 60 00 00 04 B0 00 79 62
					15 00 00 60 00 00 02 62 00
					15 00 00 60 00 00 02 F7 2F
					39 00 00 20 00 00 03 F0 A5 A5
				];
				mi,mdss-dsi-dc-demura-switch-command-state = "dsi_hs_mode";

				mi,mdss-dsi-pwm-demura-switch-command = [
					39 00 00 60 00 00 03 F0 5A 5A
					39 00 00 60 00 00 04 B0 00 79 62
					15 00 00 60 00 00 02 62 01
					15 00 00 20 00 00 02 F7 2F
					39 00 00 60 00 00 04 B0 01 56 6B
					39 00 00 60 00 00 C2 6B 01 00 00 00 00 00 00 00
								00 00 00 00 00 00 00 00 00 00 00 00
								00 00 00 00 00 00 00 00 00 00 00 00
								00 00 00 00 00 00 66 00 66 00 66 00
								66 00 66 00 66 00 66 00 66 00 66 00
								66 00 66 00 66 00 66 00 80 00 00 00
								00 00 00 00 00 00 00 00 00 00 00 00
								00 00 00 00 00 00 00 00 00 00 00 00
								00 00 00 00 00 00 00 00 00 00 66 00
								66 00 66 00 66 00 66 00 66 00 66 00
								66 00 66 00 66 00 66 00 66 00 66 00
								80 00 00 00 00 00 00 00 00 00 00 00
								00 00 00 00 00 00 00 00 00 00 00 00
								00 00 00 00 00 00 00 00 00 00 00 00
								00 00 66 00 66 00 66 00 66 00 66 00
								66 00 66 00 66 00 66 00 66 00 66 00
								66 00 66 00 80
					39 00 00 60 00 00 03 51 01 9B
					15 00 00 20 00 00 02 F7 2F
					39 00 00 60 00 00 04 B0 01 56 6B
					15 00 00 60 00 00 02 6B 00
					39 00 00 60 00 00 04 B0 00 79 62
					15 00 00 60 00 00 02 62 00
					15 00 00 60 00 00 02 F7 2F
					39 00 00 20 00 00 03 F0 A5 A5
				];
				mi,mdss-dsi-pwm-demura-switch-command-state = "dsi_hs_mode";

				qcom,mdss-dsi-nolp-command = [
					39 00 00 40 00 00 03 9F A5 A5
					39 00 00 40 00 00 03 9F A5 A5
					39 00 00 40 00 00 03 F0 5A 5A
					39 00 00 40 00 00 04 B0 00 03 BD
					39 00 00 40 00 00 02 BD 66
					39 00 00 40 00 00 02 B9 19
					39 00 00 40 00 00 04 B0 00 08 B9
					39 00 00 40 00 00 07 B9 02 00 02 02 00 02
					39 00 00 40 00 00 04 B0 00 06 B9
					39 00 00 40 00 00 02 B9 00
					39 00 00 40 00 00 02 53 20
					39 00 00 40 00 00 02 83 00
					39 00 00 40 00 00 03 51 00 23
					39 00 00 40 00 00 02 F7 2F
					39 00 00 40 00 00 03 F0 A5 A5
					39 00 00 00 00 00 03 9F 5A 5A
					//Auto120
					39 00 00 40 00 00 03 F0 5A 5A
					39 00 00 40 00 00 04 B0 00 03 BD
					39 00 00 40 00 00 02 BD 64
					39 00 00 40 00 00 04 B0 00 08 BD
					39 00 00 40 00 00 02 BD 00
					39 00 00 40 00 00 02 B9 41
					39 00 00 40 00 00 04 B0 00 08 B9
					39 00 00 40 00 00 07 B9 CA 00 02 CA 00 02
					39 00 00 40 00 00 04 B0 00 06 B9
					39 00 00 40 00 00 02 B9 00
					39 00 00 40 00 00 04 B0 00 91 B9
					39 00 00 40 00 00 02 B9 80
					39 00 00 40 00 00 04 B0 00 7B BD
					39 00 00 40 00 00 03 BD 00 77
					39 00 00 40 00 00 04 B0 00 2C BD
					39 00 00 40 00 00 02 BD 10
					39 00 00 40 00 00 04 B0 00 7D BD
					39 00 00 40 00 00 09 BD 00 00 00 01 00 03 00 0B
					39 00 00 40 00 00 04 B0 00 8D BD
					39 00 00 40 00 00 05 BD 01 02 03 09
					39 00 00 40 00 00 02 BD 05
					39 00 00 40 00 00 02 F7 2F
					39 00 00 00 00 00 03 F0 A5 A5
				];
				qcom,mdss-dsi-nolp-command-update = <0x51 11 2>;
				qcom,mdss-dsi-nolp-command-state = "dsi_hs_mode";
				qcom,mdss-dsi-timing-switch-command = [
					39 00 00 40 00 00 03 F0 5A 5A
					39 00 00 40 00 00 04 B0 00 03 BD
					39 00 00 40 00 00 02 BD 64
					39 00 00 40 00 00 04 B0 00 08 BD
					39 00 00 40 00 00 02 BD 00
					39 00 00 40 00 00 02 B9 41
					39 00 00 40 00 00 04 B0 00 08 B9
					39 00 00 40 00 00 07 B9 CA 00 02 CA 00 02
					39 00 00 40 00 00 04 B0 00 06 B9
					39 00 00 40 00 00 02 B9 00
					39 00 00 40 00 00 04 B0 00 91 B9
					39 00 00 40 00 00 02 B9 80
					39 00 00 40 00 00 04 B0 00 7B BD
					39 00 00 40 00 00 03 BD 00 77
					39 00 00 40 00 00 04 B0 00 2C BD
					39 00 00 40 00 00 02 BD 10
					39 00 00 40 00 00 04 B0 00 7D BD
					39 00 00 40 00 00 09 BD 00 00 00 01 00 03 00 0B
					39 00 00 40 00 00 04 B0 00 8D BD
					39 00 00 40 00 00 05 BD 01 02 03 09
					39 00 00 40 00 00 02 BD 05
					39 00 00 40 00 00 02 F7 2F
					39 00 00 00 00 00 03 F0 A5 A5
				];
				qcom,mdss-dsi-timing-switch-command-state = "dsi_hs_mode";
				qcom,mdss-dsi-on-command = [
					//DSC setting V1.1
					39 00 00 40 00 00 03 9F A5 A5
					39 00 00 40 00 00 59 9E 11 00 00 AB 30 80 0C 80 05 A0 00 19 02 D0 02 D0
											02 00 02 68 00 20 02 BE 00 0A 00 0C 04 00 03 0D 18 00 10 F0 07 10 20 00
 											06 0F 0F 33 0E 1C 2A 38 46 54 62 69 70 77 79 7B 7D 7E 01 02 22 00 2A 40
											2A BE 3A FC 3A FA 3A F8 3B 38 3B 78 3B B6 4B F6 4C 34 4C 74 5C 74 8C F4
					39 00 00 40 00 00 02 9D 01
					39 00 00 00 00 00 03 9F 5A 5A
					//AD Improve Setting
					39 00 00 40 00 00 03 F0 5A 5A
					39 00 00 40 00 00 03 F1 5A 5A
					15 00 00 40 00 00 02 D0 08
					39 00 00 40 00 00 04 B0 00 60 B7
					15 00 00 40 00 00 02 B7 45
					39 00 00 40 00 00 04 B0 00 6A B7
					15 00 00 40 00 00 02 B7 15
					39 00 00 40 00 00 04 B0 00 6D B7
					15 00 00 40 00 00 02 B7 45
					39 00 00 40 00 00 04 B0 00 77 B7
					15 00 00 40 00 00 02 B7 15
					39 00 00 00 00 00 0E F4 F3 E0 E1 D3 B3 D3 A3 D3 D3 B3 D3 A3 D3
					/* Sleep Out */
					05 00 00 00 78 00 01 11
					//TE ON
					39 00 00 40 00 00 03 9F A5 A5
					39 00 00 40 00 00 02 35 00
					39 00 00 00 00 00 03 9F 5A 5A
					//FIXED TE OFF
					39 00 00 40 00 00 03 F0 5A 5A
					39 00 00 40 00 00 02 B9 00
					39 00 00 40 00 00 04 B0 00 08 B9
					39 00 00 40 00 00 07 B9 00 00 00 00 00 00
					39 00 00 40 00 00 02 F7 0F
					39 00 00 00 00 00 03 F0 A5 A5
					//PAGE ADDRESS SET
					39 00 00 40 00 00 05 2A 00 00 05 9F
					39 00 00 40 00 00 05 2B 00 00 0C 7F
					//Scaler Setting
					39 00 00 40 00 00 03 F0 5A 5A
					39 00 00 40 00 00 02 C3 02
					39 00 00 40 00 00 05 2A 00 00 05 9F
					39 00 00 40 00 00 05 2B 00 00 0C 7F
					39 00 00 40 00 00 03 F0 A5 A5
					//Frequency Change Setting
					39 00 00 40 00 00 03 9F A5 A5
					39 00 00 40 00 00 03 F0 5A 5A
					39 00 00 40 00 00 02 83 00
					39 00 00 40 00 00 02 F7 2F
					39 00 00 40 00 00 03 F0 A5 A5
					39 00 00 00 00 00 03 9F 5A 5A
					//Error Flag Control
					39 00 00 40 00 00 03 F0 5A 5A
					39 00 00 40 00 00 02 E5 15
					39 00 00 40 00 00 04 B0 00 18 ED
					39 00 00 40 00 00 02 ED 1C
					39 00 00 40 00 00 04 B0 00 43 F4
					39 00 00 40 00 00 02 F4 30
					39 00 00 40 00 00 04 B0 00 01 ED
					39 00 00 40 00 00 03 ED 01 40
					39 00 00 00 00 00 03 F0 A5 A5
					//ACL Mode
					39 00 00 40 00 00 03 F0 5A 5A
					39 00 00 40 00 00 02 55 00
					39 00 00 00 00 00 03 F0 A5 A5
					//OD OFF
					39 00 00 40 00 00 03 F0 5A 5A
					39 00 00 40 00 00 04 B0 00 8B 68
					15 00 00 40 00 00 02 68 01
					15 00 00 40 00 00 02 F7 2F
					39 00 00 00 00 00 03 F0 A5 A5
					//Low Frequency Change
					39 00 00 40 00 00 03 F0 5A 5A
					39 00 00 40 00 00 04 B0 00 03 BD
					39 00 00 40 00 00 02 BD 64
					39 00 00 40 00 00 04 B0 00 08 BD
					39 00 00 40 00 00 02 BD 00
					39 00 00 40 00 00 02 B9 41
					39 00 00 40 00 00 04 B0 00 08 B9
					39 00 00 40 00 00 07 B9 CA 00 02 CA 00 02
					39 00 00 40 00 00 04 B0 00 06 B9
					39 00 00 40 00 00 02 B9 00
					39 00 00 40 00 00 04 B0 00 91 B9
					39 00 00 40 00 00 02 B9 80
					39 00 00 40 00 00 04 B0 00 7B BD
					39 00 00 40 00 00 03 BD 00 77
					39 00 00 40 00 00 04 B0 00 2C BD
					39 00 00 40 00 00 02 BD 10
					39 00 00 40 00 00 04 B0 00 7D BD
					39 00 00 40 00 00 09 BD 00 00 00 01 00 03 00 0B
					39 00 00 40 00 00 04 B0 00 8D BD
					39 00 00 40 00 00 05 BD 01 02 03 09
					39 00 00 40 00 00 02 BD 05
					39 00 00 40 00 00 02 F7 2F
					39 00 00 00 00 00 03 F0 A5 A5
					//Dimming speed
					39 00 00 40 00 00 03 F0 5A 5A
					39 00 00 40 00 00 04 B0 00 20 67
					39 00 00 40 00 00 02 67 06
					39 00 00 40 00 00 02 F7 2F
					39 00 00 00 00 00 03 F0 A5 A5
					/* AOD ON */
					39 00 00 40 00 00 03 9F A5 A5
					39 00 00 40 00 00 03 F0 5A 5A
					15 00 00 40 00 00 02 53 24
					15 00 00 40 00 00 02 83 18
					39 00 00 40 00 00 02 F7 2F
					39 00 00 40 00 00 03 F0 A5 A5
					39 00 00 00 0B 00 03 9F 5A 5A
					/* AOD OFF */
					39 00 00 40 00 00 03 9F A5 A5
					39 00 00 40 00 00 03 F0 5A 5A
					15 00 00 40 00 00 02 53 20
					15 00 00 40 00 00 02 83 00
					39 00 00 40 00 00 02 F7 2F
					39 00 00 40 00 00 03 F0 A5 A5
					39 00 00 00 00 00 03 9F 5A 5A
					//Low Frequency Change
					39 00 00 40 00 00 03 F0 5A 5A 
					39 00 00 40 00 00 04 B0 00 03 BD
					39 00 00 40 00 00 02 BD 64
					39 00 00 40 00 00 04 B0 00 08 BD
					39 00 00 40 00 00 02 BD 00
					39 00 00 40 00 00 02 B9 41
					39 00 00 40 00 00 04 B0 00 08 B9
					39 00 00 40 00 00 07 B9 CA 00 02 CA 00 02
					39 00 00 40 00 00 04 B0 00 06 B9
					39 00 00 40 00 00 02 B9 00
					39 00 00 40 00 00 04 B0 00 91 B9
					39 00 00 40 00 00 02 B9 80
					39 00 00 40 00 00 04 B0 00 7B BD
					39 00 00 40 00 00 03 BD 00 77
					39 00 00 40 00 00 04 B0 00 2C BD
					39 00 00 40 00 00 02 BD 10
					39 00 00 40 00 00 04 B0 00 7D BD
					39 00 00 40 00 00 09 BD 00 00 00 01 00 03 00 0B
					39 00 00 40 00 00 04 B0 00 8D BD
					39 00 00 40 00 00 05 BD 01 02 03 09
					39 00 00 40 00 00 02 BD 05
					39 00 00 40 00 00 02 F7 2F
					39 00 00 00 00 00 03 F0 A5 A5
					//Brightness Control
					39 00 00 40 00 00 02 53 20
					39 00 00 00 00 00 03 51 00 00
					//PWM&DC switch
					39 00 00 40 00 00 03 F0 5A 5A
					39 00 00 40 00 00 04 B0 02 17 6B
					39 00 00 40 00 00 61 6B 00 10 18 20 28 30 38 40 48 50 58 60
							  	68 70 78 80 88 90 98 A0 A8 B0 B8 C0 C8 D0 D8 E0 E8 F0 F8 FF 00
							  	10 18 20 28 30 38 40 48 50 58 60 68 70 78 80 88 90 98 A0 A8 B0
							  	B8 C0 C8 D0 D8 E0 E8 F0 F8 FF 00 10 18 20 28 30 38 40 48 50 58
							  	60 68 70 78 80 88 90 98 A0 A8 B0 B8 C0 C8 D0 D8 E0 E8 F0 F8 FF
					39 00 00 40 00 00 04 B0 00 1E 67
					15 00 00 40 00 00 02 67 11
					15 00 00 40 00 00 02 F7 2F
					39 00 00 00 00 00 03 F0 A5 A5
					/* Display On */
					39 00 00 40 00 00 03 9F A5 A5
					05 00 00 40 00 00 01 29
					39 00 00 00 00 00 03 9F 5A 5A
				];
				qcom,mdss-dsi-on-command-state = "dsi_lp_mode";
			};
			timing@wqhd_auto_60_to_1hz_index_09 {
				#include "dsi-panel-o1-38-0c-0b-dsc-cmd-common.dtsi"
				cell-index = <9>;
				qcom,mdss-dsi-panel-framerate = <60>;
				/* ---------------------------- */
				/* | 15 - 14 | 13 - 7 | 6 - 0 | */
				/* ---------------------------- */
				/* |   mode  | sf fps | min fps| */
				/* ---------------------------- -*/
				/* mode: 1 idle, 2 auto, 3 qsync */
				/*   2 << 14 | 60 << 7 | 1     */
				qcom,mdss-dsi-h-sync-skew = <40449>;
				/* mode: 0 normal, 1 idle, 2 auto, 3 qsync, 4 diff, 5 test */
				mi,mdss-dsi-ddic-mode = "auto";
				mi,mdss-dsi-sf-framerate = <60>;
				mi,mdss-dsi-ddic-min-framerate = <1>;
				mi,mdss-dsi-doze-hbm-command = [
					//120HZ
					39 00 00 40 00 00 03 9F A5 A5
					39 00 00 40 00 00 03 F0 5A 5A
					39 00 00 40 00 00 04 B0 00 03 BD
					39 00 00 40 00 00 02 BD 66
					39 00 00 40 00 00 04 B0 00 08 BD
					39 00 00 40 00 00 02 BD 00
					39 00 00 40 00 00 02 B9 19
					39 00 00 40 00 00 04 B0 00 08 B9
					39 00 00 40 00 00 07 B9 02 00 02 02 00 02
					39 00 00 40 00 00 04 B0 00 06 B9
					39 00 00 40 00 00 02 B9 00
					39 00 00 40 00 00 04 B0 00 91 B9
					39 00 00 40 00 00 02 B9 00
					39 00 00 40 00 00 02 BD 01
					39 00 00 40 00 00 02 83 00
					39 00 00 40 00 00 02 F7 2F
					39 00 00 40 00 00 03 F0 A5 A5
					39 00 00 00 2A 00 03 9F 5A 5A
					//1HZ AOD
					39 00 00 40 00 00 03 9F A5 A5
					39 00 00 40 00 00 03 F0 5A 5A
					39 00 00 40 00 00 04 B0 00 03 BD
					39 00 00 40 00 00 02 BD 64
					39 00 00 40 00 00 02 53 24
					39 00 00 40 00 00 02 83 1B
					39 00 00 40 00 00 03 51 01 9C
					39 00 00 40 00 00 02 B9 C1
					39 00 00 40 00 00 04 B0 00 08 B9
					39 00 00 40 00 00 07 B9 32 00 02 32 00 02
					39 00 00 40 00 00 04 B0 00 06 B9
					39 00 00 40 00 00 02 B9 03
					39 00 00 40 00 00 02 F7 2F
					39 00 00 40 00 00 03 F0 A5 A5
					39 00 00 00 00 00 03 9F 5A 5A
				];
				mi,mdss-dsi-doze-hbm-command-state = "dsi_hs_mode";

				mi,mdss-dsi-doze-lbm-command = [
					//120HZ
					39 00 00 40 00 00 03 9F A5 A5
					39 00 00 40 00 00 03 F0 5A 5A
					39 00 00 40 00 00 04 B0 00 03 BD
					39 00 00 40 00 00 02 BD 66
					39 00 00 40 00 00 04 B0 00 08 BD
					39 00 00 40 00 00 02 BD 00
					39 00 00 40 00 00 02 B9 19
					39 00 00 40 00 00 04 B0 00 08 B9
					39 00 00 40 00 00 07 B9 02 00 02 02 00 02
					39 00 00 40 00 00 04 B0 00 06 B9
					39 00 00 40 00 00 02 B9 00
					39 00 00 40 00 00 04 B0 00 91 B9
					39 00 00 40 00 00 02 B9 00
					39 00 00 40 00 00 02 BD 01
					39 00 00 40 00 00 02 83 00
					39 00 00 40 00 00 02 F7 2F
					39 00 00 40 00 00 03 F0 A5 A5
					39 00 00 00 2A 00 03 9F 5A 5A
					//1HZ AOD
					39 00 00 40 00 00 03 9F A5 A5
					39 00 00 40 00 00 03 F0 5A 5A
					39 00 00 40 00 00 04 B0 00 03 BD
					39 00 00 40 00 00 02 BD 64
					39 00 00 40 00 00 02 53 24
					39 00 00 40 00 00 02 83 1B
					39 00 00 40 00 00 03 51 00 23
					39 00 00 40 00 00 02 B9 C1
					39 00 00 40 00 00 04 B0 00 08 B9
					39 00 00 40 00 00 07 B9 32 00 02 32 00 02
					39 00 00 40 00 00 04 B0 00 06 B9
					39 00 00 40 00 00 02 B9 03
					39 00 00 40 00 00 02 F7 2F
					39 00 00 40 00 00 03 F0 A5 A5
					39 00 00 00 00 00 03 9F 5A 5A
				];
				mi,mdss-dsi-doze-lbm-command-state = "dsi_hs_mode";

				mi,mdss-dsi-dc-demura-switch-command = [
					39 00 00 60 00 00 03 F0 5A 5A
					15 00 00 60 00 00 02 53 20
					39 00 00 60 00 00 04 B0 00 79 62
					15 00 00 60 00 00 02 62 01
					15 00 00 20 03 00 02 F7 2F
					39 00 00 60 00 00 04 B0 01 56 6B
					39 00 00 60 00 00 C2 6B 01 FF FF FF FF FF FF FF
								FF FF FF FF FF FF A8 FF A8 FF 96 FF
								84 FF 73 FF 50 FF 3E FF 1B FF 09 FE
								E6 FE E6 FE E6 FE E6 FE E6 FE E6 FE
								E6 FE E6 FE E6 FE E6 FE E6 FE E6 FE
								E6 FE E6 FE E6 FE E6 FE B1 FF FF FF
								FF FF FF FF FF FF FF FF FF FF A8 FF
								A8 FF 96 FF 84 FF 73 FF 50 FF 3E FF
								1B FF 09 FE E6 FE E6 FE E6 FE E6 FE
								E6 FE E6 FE E6 FE E6 FE E6 FE E6 FE
								E6 FE E6 FE E6 FE E6 FE E6 FE E6 FE
								B1 FF FF FF FF FF FF FF FF FF FF FF
								FF FF A8 FF A8 FF 96 FF 84 FF 73 FF
								50 FF 3E FF 1B FF 09 FE E6 FE E6 FE
								E6 FE E6 FE E6 FE E6 FE E6 FE E6 FE
								E6 FE E6 FE E6 FE E6 FE E6 FE E6 FE
								E6 FE E6 FE B1
					39 00 00 60 00 00 03 51 01 9C
					15 00 00 20 03 00 02 F7 2F
					39 00 00 60 00 00 04 B0 01 56 6B
					15 00 00 60 00 00 02 6B 00
					39 00 00 60 00 00 04 B0 00 79 62
					15 00 00 60 00 00 02 62 00
					15 00 00 60 00 00 02 F7 2F
					39 00 00 20 00 00 03 F0 A5 A5
				];
				mi,mdss-dsi-dc-demura-switch-command-state = "dsi_hs_mode";

				mi,mdss-dsi-pwm-demura-switch-command = [
					39 00 00 60 00 00 03 F0 5A 5A
					15 00 00 60 00 00 02 53 20
					39 00 00 60 00 00 04 B0 00 79 62
					15 00 00 60 00 00 02 62 01
					15 00 00 20 03 00 02 F7 2F
					39 00 00 60 00 00 04 B0 01 56 6B
					39 00 00 60 00 00 C2 6B 01 00 00 00 00 00 00 00
								00 00 00 00 00 00 00 00 00 00 00 00
								00 00 00 00 00 00 00 00 00 00 00 00
								00 00 00 00 00 00 8C 00 8C 00 8C 00
								8C 00 8C 00 8C 00 8C 00 8C 00 8C 00
								8C 00 8C 00 8C 00 8C 00 B0 00 00 00
								00 00 00 00 00 00 00 00 00 00 00 00
								00 00 00 00 00 00 00 00 00 00 00 00
								00 00 00 00 00 00 00 00 00 00 8C 00
								8C 00 8C 00 8C 00 8C 00 8C 00 8C 00
								8C 00 8C 00 8C 00 8C 00 8C 00 8C 00
								B0 00 00 00 00 00 00 00 00 00 00 00
								00 00 00 00 00 00 00 00 00 00 00 00
								00 00 00 00 00 00 00 00 00 00 00 00
								00 00 8C 00 8C 00 8C 00 8C 00 8C 00
								8C 00 8C 00 8C 00 8C 00 8C 00 8C 00
								8C 00 8C 00 B0
					39 00 00 60 00 00 03 51 01 9B
					15 00 00 20 03 00 02 F7 2F
					39 00 00 60 00 00 04 B0 01 56 6B
					15 00 00 60 00 00 02 6B 00
					39 00 00 60 00 00 04 B0 00 79 62
					15 00 00 60 00 00 02 62 00
					15 00 00 60 00 00 02 F7 2F
					39 00 00 20 00 00 03 F0 A5 A5
				];
				mi,mdss-dsi-pwm-demura-switch-command-state = "dsi_hs_mode";

				qcom,mdss-dsi-nolp-command = [
					39 00 00 40 00 00 03 9F A5 A5
					39 00 00 40 00 00 03 F0 5A 5A
					39 00 00 40 00 00 04 B0 00 03 BD
					39 00 00 40 00 00 02 BD 66
					39 00 00 40 00 00 02 B9 19
					39 00 00 40 00 00 04 B0 00 08 B9
					39 00 00 40 00 00 07 B9 02 00 02 02 00 02
					39 00 00 40 00 00 04 B0 00 06 B9
					39 00 00 40 00 00 02 B9 00
					39 00 00 40 00 00 02 53 20
					39 00 00 40 00 00 02 83 00
					39 00 00 40 00 00 03 51 00 23
					39 00 00 40 00 00 02 F7 2F
					39 00 00 40 00 00 03 F0 A5 A5
					39 00 00 00 00 00 03 9F 5A 5A
					//Auto60
					39 00 00 40 00 00 03 F0 5A 5A
					39 00 00 40 00 00 04 B0 00 03 BD
					39 00 00 40 00 00 02 BD 64
					39 00 00 40 00 00 04 B0 00 08 BD
					39 00 00 40 00 00 02 BD 01
					39 00 00 40 00 00 02 B9 41
					39 00 00 40 00 00 04 B0 00 08 B9
					39 00 00 40 00 00 07 B9 CA 00 02 CA 00 02
					39 00 00 40 00 00 04 B0 00 06 B9
					39 00 00 40 00 00 02 B9 01
					39 00 00 40 00 00 04 B0 00 91 B9
					39 00 00 40 00 00 02 B9 80
					39 00 00 40 00 00 04 B0 00 7B BD
					39 00 00 40 00 00 03 BD 00 77
					39 00 00 40 00 00 04 B0 00 2C BD
					39 00 00 40 00 00 02 BD 00
					39 00 00 40 00 00 04 B0 00 7D BD
					39 00 00 40 00 00 07 BD 00 01 00 03 00 0B
					39 00 00 40 00 00 04 B0 00 8D BD
					39 00 00 40 00 00 04 BD 02 03 09
					39 00 00 40 00 00 02 BD 05
					39 00 00 40 00 00 02 F7 2F
					39 00 00 00 00 00 03 F0 A5 A5
				];
				qcom,mdss-dsi-nolp-command-update = <0x51 11 2>;
				qcom,mdss-dsi-nolp-command-state = "dsi_hs_mode";
				qcom,mdss-dsi-timing-switch-command = [
					39 00 00 40 00 00 03 F0 5A 5A
					39 00 00 40 00 00 04 B0 00 03 BD
					39 00 00 40 00 00 02 BD 64
					39 00 00 40 00 00 04 B0 00 08 BD
					39 00 00 40 00 00 02 BD 01
					39 00 00 40 00 00 02 B9 41
					39 00 00 40 00 00 04 B0 00 08 B9
					39 00 00 40 00 00 07 B9 CA 00 02 CA 00 02
					39 00 00 40 00 00 04 B0 00 06 B9
					39 00 00 40 00 00 02 B9 01
					39 00 00 40 00 00 04 B0 00 91 B9
					39 00 00 40 00 00 02 B9 80
					39 00 00 40 00 00 04 B0 00 7B BD
					39 00 00 40 00 00 03 BD 00 77
					39 00 00 40 00 00 04 B0 00 2C BD
					39 00 00 40 00 00 02 BD 00
					39 00 00 40 00 00 04 B0 00 7D BD
					39 00 00 40 00 00 07 BD 00 01 00 03 00 0B
					39 00 00 40 00 00 04 B0 00 8D BD
					39 00 00 40 00 00 04 BD 02 03 09
					39 00 00 40 00 00 02 BD 05
					39 00 00 40 00 00 02 F7 2F
					39 00 00 00 00 00 03 F0 A5 A5
				];
				qcom,mdss-dsi-timing-switch-command-state = "dsi_hs_mode";
				qcom,mdss-dsi-on-command = [
					//DSC setting V1.1
					39 00 00 40 00 00 03 9F A5 A5
					39 00 00 40 00 00 59 9E 11 00 00 AB 30 80 0C 80 05 A0 00 19 02 D0 02 D0
											02 00 02 68 00 20 02 BE 00 0A 00 0C 04 00 03 0D 18 00 10 F0 07 10 20 00
 											06 0F 0F 33 0E 1C 2A 38 46 54 62 69 70 77 79 7B 7D 7E 01 02 22 00 2A 40
											2A BE 3A FC 3A FA 3A F8 3B 38 3B 78 3B B6 4B F6 4C 34 4C 74 5C 74 8C F4
					39 00 00 40 00 00 02 9D 01
					39 00 00 00 00 00 03 9F 5A 5A
					/* Sleep Out */
					05 00 00 00 78 00 01 11
					//TE ON
					39 00 00 40 00 00 03 9F A5 A5
					39 00 00 40 00 00 02 35 00
					39 00 00 00 00 00 03 9F 5A 5A
					//FIXED TE OFF
					39 00 00 40 00 00 03 F0 5A 5A
					39 00 00 40 00 00 02 B9 00
					39 00 00 40 00 00 04 B0 00 08 B9
					39 00 00 40 00 00 07 B9 00 00 00 00 00 00
					39 00 00 40 00 00 02 F7 0F
					39 00 00 00 00 00 03 F0 A5 A5
					//PAGE ADDRESS SET
					39 00 00 40 00 00 05 2A 00 00 05 9F
					39 00 00 40 00 00 05 2B 00 00 0C 7F
					//Scaler Setting
					39 00 00 40 00 00 03 F0 5A 5A
					39 00 00 40 00 00 02 C3 02
					39 00 00 40 00 00 05 2A 00 00 05 9F
					39 00 00 40 00 00 05 2B 00 00 0C 7F
					39 00 00 40 00 00 03 F0 A5 A5
					//Frequency Change Setting
					39 00 00 40 00 00 03 9F A5 A5
					39 00 00 40 00 00 03 F0 5A 5A
					39 00 00 40 00 00 02 83 00
					39 00 00 40 00 00 02 F7 2F
					39 00 00 40 00 00 03 F0 A5 A5
					39 00 00 00 00 00 03 9F 5A 5A
					//Error Flag Control
					39 00 00 40 00 00 03 F0 5A 5A
					39 00 00 40 00 00 02 E5 15
					39 00 00 40 00 00 04 B0 00 18 ED
					39 00 00 40 00 00 02 ED 1C
					39 00 00 40 00 00 04 B0 00 43 F4
					39 00 00 40 00 00 02 F4 30
					39 00 00 40 00 00 04 B0 00 01 ED
					39 00 00 40 00 00 03 ED 01 40
					39 00 00 00 00 00 03 F0 A5 A5
					//ACL Mode
					39 00 00 40 00 00 03 F0 5A 5A
					39 00 00 40 00 00 02 55 00
					39 00 00 00 00 00 03 F0 A5 A5
					//OD OFF
					39 00 00 40 00 00 03 F0 5A 5A
					39 00 00 40 00 00 04 B0 00 8B 68
					15 00 00 40 00 00 02 68 01
					15 00 00 40 00 00 02 F7 2F
					39 00 00 00 00 00 03 F0 A5 A5
					//Low Frequency Change
					39 00 00 40 00 00 03 F0 5A 5A
					39 00 00 40 00 00 04 B0 00 03 BD
					39 00 00 40 00 00 02 BD 64
					39 00 00 40 00 00 04 B0 00 08 BD
					39 00 00 40 00 00 02 BD 01
					39 00 00 40 00 00 02 B9 41
					39 00 00 40 00 00 04 B0 00 08 B9
					39 00 00 40 00 00 07 B9 CA 00 02 CA 00 02
					39 00 00 40 00 00 04 B0 00 06 B9
					39 00 00 40 00 00 02 B9 01
					39 00 00 40 00 00 04 B0 00 91 B9
					39 00 00 40 00 00 02 B9 80
					39 00 00 40 00 00 04 B0 00 7B BD
					39 00 00 40 00 00 03 BD 00 77
					39 00 00 40 00 00 04 B0 00 2C BD
					39 00 00 40 00 00 02 BD 00
					39 00 00 40 00 00 04 B0 00 7D BD
					39 00 00 40 00 00 07 BD 00 01 00 03 00 0B
					39 00 00 40 00 00 04 B0 00 8D BD
					39 00 00 40 00 00 04 BD 02 03 09
					39 00 00 40 00 00 02 BD 05
					39 00 00 40 00 00 02 F7 2F
					39 00 00 00 00 00 03 F0 A5 A5
					//Dimming speed
					39 00 00 40 00 00 03 F0 5A 5A
					39 00 00 40 00 00 04 B0 00 20 67
					39 00 00 40 00 00 02 67 06
					39 00 00 40 00 00 02 F7 2F
					39 00 00 00 00 00 03 F0 A5 A5
					/* AOD ON */
					39 00 00 40 00 00 03 9F A5 A5
					39 00 00 40 00 00 03 F0 5A 5A
					15 00 00 40 00 00 02 53 24
					15 00 00 40 00 00 02 83 18
					39 00 00 40 00 00 02 F7 2F
					39 00 00 40 00 00 03 F0 A5 A5
					39 00 00 00 0B 00 03 9F 5A 5A
					/* AOD OFF */
					39 00 00 40 00 00 03 9F A5 A5
					39 00 00 40 00 00 03 F0 5A 5A
					15 00 00 40 00 00 02 53 20
					15 00 00 40 00 00 02 83 00
					39 00 00 40 00 00 02 F7 2F
					39 00 00 40 00 00 03 F0 A5 A5
					39 00 00 00 00 00 03 9F 5A 5A
					//Low Frequency Change
					39 00 00 40 00 00 03 F0 5A 5A
					39 00 00 40 00 00 04 B0 00 03 BD
					39 00 00 40 00 00 02 BD 64
					39 00 00 40 00 00 04 B0 00 08 BD
					39 00 00 40 00 00 02 BD 01
					39 00 00 40 00 00 02 B9 41
					39 00 00 40 00 00 04 B0 00 08 B9
					39 00 00 40 00 00 07 B9 CA 00 02 CA 00 02
					39 00 00 40 00 00 04 B0 00 06 B9
					39 00 00 40 00 00 02 B9 01
					39 00 00 40 00 00 04 B0 00 91 B9
					39 00 00 40 00 00 02 B9 80
					39 00 00 40 00 00 04 B0 00 7B BD
					39 00 00 40 00 00 03 BD 00 77
					39 00 00 40 00 00 04 B0 00 2C BD
					39 00 00 40 00 00 02 BD 00
					39 00 00 40 00 00 04 B0 00 7D BD
					39 00 00 40 00 00 07 BD 00 01 00 03 00 0B
					39 00 00 40 00 00 04 B0 00 8D BD
					39 00 00 40 00 00 04 BD 02 03 09
					39 00 00 40 00 00 02 BD 05
					39 00 00 40 00 00 02 F7 2F
					39 00 00 00 00 00 03 F0 A5 A5
					//Brightness Control
					39 00 00 40 00 00 02 53 20
					39 00 00 00 00 00 03 51 00 00
					//PWM&DC switch
					39 00 00 40 00 00 03 F0 5A 5A
					39 00 00 40 00 00 04 B0 02 17 6B
					39 00 00 40 00 00 61 6B 00 10 18 20 28 30 38 40 48 50 58 60
							  	68 70 78 80 88 90 98 A0 A8 B0 B8 C0 C8 D0 D8 E0 E8 F0 F8 FF 00
							  	10 18 20 28 30 38 40 48 50 58 60 68 70 78 80 88 90 98 A0 A8 B0
							  	B8 C0 C8 D0 D8 E0 E8 F0 F8 FF 00 10 18 20 28 30 38 40 48 50 58
							  	60 68 70 78 80 88 90 98 A0 A8 B0 B8 C0 C8 D0 D8 E0 E8 F0 F8 FF
					39 00 00 40 00 00 04 B0 00 1E 67
					15 00 00 40 00 00 02 67 11
					15 00 00 40 00 00 02 F7 2F
					39 00 00 00 00 00 03 F0 A5 A5
					/* Display On */
					39 00 00 40 00 00 03 9F A5 A5
					05 00 00 40 00 00 01 29
					39 00 00 00 00 00 03 9F 5A 5A
				];
				qcom,mdss-dsi-on-command-state = "dsi_lp_mode";
			};
		};
	};
};
&dsi_o1_38_0c_0b_dsc_cmd {
	qcom,panel-supply-entries = <&dsi_panel_pwr_supply_O1>;
	qcom,mdss-dsi-bl-pmic-control-type = "bl_ctrl_dcs";
	qcom,mdss-dsi-bl-min-level = <15>;
	qcom,mdss-dsi-bl-max-level = <16383>;
	qcom,bl-dsc-cmd-state = "dsi_hs_mode";
	qcom,mdss-brightness-max-level = <16383>;
	qcom,mdss-brightness-init-level = <614>;
	qcom,platform-reset-gpio = <&tlmm 98 0>;

	mi,max-brightness-normal = <5460>;

	mi,panel-build-id-read-needed;
	mi,panel-build-id-read-length = <1>;
	mi,mdss-dsi-panel-build-id-read-command = [06 01 00 01 00 00 01 DA];
	mi,mdss-dsi-panel-build-id-read-command-state = "dsi_hs_mode";
	mi,dc-feature-enabled;
	mi,dc-feature-type = "type_dc_pwm_switch_skip_bl";
	mi,mdss-dsi-panel-dc-threshold = <412>;

	qcom,mdss-dsi-panel-vsync-delay;
	qcom,ulps-enabled;
	qcom,dsi-select-clocks = "pll_byte_clk0", "pll_dsi_clk0";
	qcom,mdss-dsi-clk-strength = <0xFF>;
};
